VERSION "$Format:%h$"

NS_ :

BS_:

BU_: APB APP APS BCCEN BDY DAS DBG EAS EPAS EPAS2 EPAS3S EPB EPBM ESP GTW GTWU IBST IC MCU OCS PARK PARK3 RADAR RCM RT3000 SCCM SDM SEC TAS TAS2 TAS2DBG TOOL TPMS VCSEATD VCSEATP

BO_ 1463 EPBM_alertLog: 8 EPBM
 SG_ EPBM_alertID M : 0|15@1+ (1,0) [0|0] "" GTW
 SG_ EPBM_alertType : 15|1@1+ (1,0) [0|0] "" GTW
 SG_ EPBM_a001_leftEncIntrpt m1 : 16|16@1+ (1,0) [0|0] "" GTW
 SG_ EPBM_a002_leftIdleOc m2 : 16|16@1+ (0.01115686274,0) [0|0] "" GTW
 SG_ EPBM_a003_leftEncIrrational m3 : 16|16@1+ (1,0) [0|0] "" GTW
 SG_ EPBM_a005_leftOc m5 : 16|16@1+ (0.017346834,-37.87878788) [0|0] "A" GTW
 SG_ EPBM_a006_leftUc m6 : 16|16@1+ (0.017346834,-37.87878788) [0|0] "A" GTW
 SG_ EPBM_a007_leftEndStop m7 : 16|16@1+ (0.017346834,-37.87878788) [0|0] "A" GTW
 SG_ EPBM_a008_voltageCounts m8 : 16|16@1+ (1,0) [0|0] "" GTW
 SG_ EPBM_a008_encPosition m8 : 32|16@1+ (1,0) [0|0] "" GTW
 SG_ EPBM_a009_voltageN m9 : 16|16@1+ (0.004833984375,0) [0|0] "V" GTW
 SG_ EPBM_a009_voltageP m9 : 32|16@1+ (0.004833984375,0) [0|0] "V" GTW
 SG_ EPBM_a010_voltageN m10 : 16|16@1+ (0.004833984375,0) [0|0] "V" GTW
 SG_ EPBM_a010_voltageP m10 : 32|16@1+ (0.004833984375,0) [0|0] "V" GTW
 SG_ EPBM_a011_voltageN m11 : 16|16@1+ (0.004833984375,0) [0|0] "V" GTW
 SG_ EPBM_a011_voltageP m11 : 32|16@1+ (0.004833984375,0) [0|0] "V" GTW
 SG_ EPBM_a012_voltageN m12 : 16|16@1+ (0.004833984375,0) [0|0] "V" GTW
 SG_ EPBM_a012_voltageP m12 : 32|16@1+ (0.004833984375,0) [0|0] "V" GTW
 SG_ EPBM_a013_reqState m13 : 16|16@1+ (1,0) [0|0] "" GTW
 SG_ EPBM_a013_substate m13 : 32|16@1+ (1,0) [0|0] "" GTW
 SG_ EPBM_a014_reqState m14 : 16|16@1+ (1,0) [0|0] "" GTW
 SG_ EPBM_a014_substate m14 : 32|16@1+ (1,0) [0|0] "" GTW
 SG_ EPBM_a015_state m15 : 16|16@1+ (1,0) [0|0] "" GTW
 SG_ EPBM_a015_reqState m15 : 32|16@1+ (1,0) [0|0] "" GTW
 SG_ EPBM_a015_EPB_substate m15 : 48|8@1+ (1,0) [0|0] "" GTW
 SG_ EPBM_a016_leftPHalfBridge m16 : 16|16@1+ (1,0) [0|0] "" GTW
 SG_ EPBM_a017_leftNHalfBridge m17 : 16|16@1+ (1,0) [0|0] "" GTW
 SG_ EPBM_a018_voltageN m18 : 16|16@1+ (0.004833984375,0) [0|0] "V" GTW
 SG_ EPBM_a018_voltageP m18 : 32|16@1+ (0.004833984375,0) [0|0] "V" GTW
 SG_ EPBM_a019_voltageN m19 : 16|16@1+ (0.004833984375,0) [0|0] "V" GTW
 SG_ EPBM_a019_voltageP m19 : 32|16@1+ (0.004833984375,0) [0|0] "V" GTW
 SG_ EPBM_a020_voltageN m20 : 16|16@1+ (0.004833984375,0) [0|0] "V" GTW
 SG_ EPBM_a020_voltageP m20 : 32|16@1+ (0.004833984375,0) [0|0] "V" GTW
 SG_ EPBM_a021_voltageN m21 : 16|16@1+ (0.004833984375,0) [0|0] "V" GTW
 SG_ EPBM_a021_voltageP m21 : 32|16@1+ (0.004833984375,0) [0|0] "V" GTW
 SG_ EPBM_a022_substateEPB m22 : 16|16@1+ (1,0) [0|0] "" GTW
 SG_ EPBM_a022_substateEPBM m22 : 32|16@1+ (1,0) [0|0] "" GTW
 SG_ EPBM_a023_targetCurrent m23 : 16|16@1+ (0.017346834,-37.87878788) [0|0] "A" GTW
 SG_ EPBM_a023_measuredCurrent m23 : 32|16@1+ (0.017346834,-37.87878788) [0|0] "A" GTW
 SG_ EPBM_a023_peakCurrent m23 : 48|16@1+ (0.017346834,-37.87878788) [0|0] "A" GTW
 SG_ EPBM_a024_encPosition m24 : 16|16@1+ (1,0) [0|0] "" GTW
 SG_ EPBM_a024_current m24 : 32|16@1+ (0.017346834,-37.87878788) [0|0] "A" GTW
 SG_ EPBM_a025_encPosition m25 : 16|16@1+ (1,0) [0|0] "" GTW
 SG_ EPBM_a025_voltageCounts m25 : 32|16@1+ (1,0) [0|0] "" GTW
 SG_ EPBM_a026_leftUnderRelease m26 : 16|16@1+ (1,0) [0|0] "" GTW
 SG_ EPBM_a027_encoderElapsed m27 : 16|16@1+ (1,0) [0|0] "" GTW
 SG_ EPBM_a028_uncalibratedCurrent m28 : 16|12@1+ (0.017346834,-37.87878788) [0|0] "A" GTW
 SG_ EPBM_a028_calibratedCurrent m28 : 28|12@1+ (0.017346834,-37.87878788) [0|0] "A" GTW
 SG_ EPBM_a029_canDisabled m29 : 16|16@1+ (1,0) [0|0] "" GTW
 SG_ EPBM_a030_spiCksum m30 : 16|16@1+ (1,0) [0|0] "" GTW
 SG_ EPBM_a030_calcCksum m30 : 32|16@1+ (1,0) [0|0] "" GTW
 SG_ EPBM_a031_stateEPB m31 : 16|16@1+ (1,0) [0|0] "" GTW
 SG_ EPBM_a031_stateEPBM m31 : 32|16@1+ (1,0) [0|0] "" GTW
 SG_ EPBM_a032_reqStateEPB m32 : 16|16@1+ (1,0) [0|0] "" GTW
 SG_ EPBM_a032_reqStateEPBM m32 : 32|16@1+ (1,0) [0|0] "" GTW
 SG_ EPBM_a033_canID m33 : 16|12@1+ (1,0) [0|0] "" GTW
 SG_ EPBM_a033_mbox m33 : 28|4@1+ (1,0) [0|0] "" GTW
 SG_ EPBM_a034_canID m34 : 16|12@1+ (1,0) [0|0] "" GTW
 SG_ EPBM_a034_errorType m34 : 28|4@1+ (1,0) [0|0] "" GTW
 SG_ EPBM_a034_badValue1 m34 : 32|16@1+ (1,0) [0|0] "" GTW
 SG_ EPBM_a034_badValue2 m34 : 48|16@1+ (1,0) [0|0] "" GTW
 SG_ EPBM_canAddress m35 : 16|12@1+ (1,0) [0|0] "" GTW
 SG_ EPBM_canErrorType m35 : 28|4@1+ (1,0) [0|0] "" GTW
 SG_ EPBM_canErrorWord1 m35 : 32|16@1+ (1,0) [0|0] "" GTW
 SG_ EPBM_canErrorWord2 m35 : 48|16@1+ (1,0) [0|0] "" GTW
 SG_ EPBM_a036_canOverrun m36 : 16|16@1+ (1,0) [0|0] "" GTW
 SG_ EPBM_a037_firmware m37 : 16|16@1+ (1,0) [0|0] "" GTW
 SG_ EPBM_eepromErrorType m38 : 16|16@1+ (1,0) [0|0] "" GTW
 SG_ EPBM_a039_watchdogReset m39 : 16|16@1+ (1,0) [0|0] "" GTW
 SG_ EPBM_a040_memoryError m40 : 16|16@1+ (1,0) [0|0] "" GTW
 SG_ EPBM_a041_spiOpen m41 : 16|16@1+ (1,0) [0|0] "" GTW
 SG_ EPBM_a042_spiRead m42 : 16|16@1+ (1,0) [0|0] "" GTW
 SG_ EPBM_a043_ABS_A m43 : 16|16@1+ (1,0) [0|0] "" GTW
 SG_ EPBM_a043_ABS_E m43 : 32|16@1+ (1,0) [0|0] "" GTW
 SG_ EPBM_a043_ABS_B m43 : 48|16@1+ (1,0) [0|0] "" GTW
 SG_ EPBM_a044_DI_Torque1 m44 : 16|1@1+ (1,0) [0|0] "" GTW
 SG_ EPBM_a044_DI_Torque2 m44 : 17|1@1+ (1,0) [0|0] "" GTW
 SG_ EPBM_a044_DI_state m44 : 18|1@1+ (1,0) [0|0] "" GTW
 SG_ EPBM_a044_DI_state2 m44 : 19|1@1+ (1,0) [0|0] "" GTW
 SG_ EPBM_a045_GTW_status m45 : 16|1@1+ (1,0) [0|0] "" GTW
 SG_ EPBM_a045_GTW_chControl m45 : 17|1@1+ (1,0) [0|0] "" GTW
 SG_ EPBM_a045_GTW_carConfig m45 : 18|1@1+ (1,0) [0|0] "" GTW
 SG_ EPBM_a045_GTW_odo m45 : 19|1@1+ (1,0) [0|0] "" GTW
 SG_ EPBM_a046_SBW_RQ_SCCM m46 : 16|16@1+ (1,0) [0|0] "" GTW
 SG_ EPBM_a047_EPB_status m47 : 16|16@1+ (1,0) [0|0] "" GTW
 SG_ EPBM_a048_CHG_status m48 : 16|16@1+ (1,0) [0|0] "" GTW
 SG_ EPBM_a049_ESP_125h m49 : 16|1@1+ (1,0) [0|0] "" GTW
 SG_ EPBM_a049_ESP_A m49 : 17|1@1+ (1,0) [0|0] "" GTW
 SG_ EPBM_a049_ESP_B m49 : 18|1@1+ (1,0) [0|0] "" GTW
 SG_ EPBM_a049_ESP_E m49 : 19|1@1+ (1,0) [0|0] "" GTW
 SG_ EPBM_a049_ESP_C m49 : 20|1@1+ (1,0) [0|0] "" GTW
 SG_ EPBM_a049_ESP_wheelSpeeds m49 : 21|1@1+ (1,0) [0|0] "" GTW
 SG_ EPBM_a049_ESP_145h m49 : 22|1@1+ (1,0) [0|0] "" GTW
 SG_ EPBM_a049_ESP_115h m49 : 23|1@1+ (1,0) [0|0] "" GTW
 SG_ EPBM_a050_MCU_chControl m50 : 16|16@1+ (1,0) [0|0] "" GTW
 SG_ EPBM_a050_MCU_chControl2 m50 : 32|1@1+ (1,0) [0|0] "" GTW
 SG_ EPBM_a051_voltageN m51 : 16|16@1+ (0.004833984375,0) [0|0] "V" GTW
 SG_ EPBM_a051_voltageP m51 : 32|16@1+ (0.004833984375,0) [0|0] "V" GTW
 SG_ EPBM_a052_voltageN m52 : 16|16@1+ (0.004833984375,0) [0|0] "V" GTW
 SG_ EPBM_a052_voltageP m52 : 32|16@1+ (0.004833984375,0) [0|0] "V" GTW
 SG_ EPBM_a055_taskID m55 : 16|16@1+ (1,0) [0|0] "" GTW
 SG_ EPBM_a055_stackUsed m55 : 32|16@1+ (1,0) [0|0] "" GTW
 SG_ EPBM_a055_stackSize m55 : 48|16@1+ (1,0) [0|0] "" GTW
 SG_ EPBM_a056_twelveV m56 : 16|16@1+ (0.004833984375,0) [0|0] "V" GTW
 SG_ EPBM_a057_twelveV m57 : 16|16@1+ (0.004833984375,0) [0|0] "V" GTW
 SG_ EPBM_a058_5vLost m58 : 16|16@1+ (1,0) [0|0] "" GTW
 SG_ EPBM_a059_batt1 m59 : 16|16@1+ (0.004833984375,0) [0|0] "V" GTW
 SG_ EPBM_a059_batt2 m59 : 32|16@1+ (0.004833984375,0) [0|0] "V" GTW
 SG_ EPBM_a060_maxCycles1 m60 : 16|16@1+ (1,0) [0|0] "" GTW
 SG_ EPBM_a061_maxCycles2 m61 : 16|16@1+ (1,0) [0|0] "" GTW
 SG_ EPBM_a062_diGear m62 : 16|16@1+ (1,0) [0|0] "" GTW
 SG_ EPBM_a062_state m62 : 32|16@1+ (1,0) [0|0] "" GTW
 SG_ EPBM_a063_frontWhlSpeed m63 : 16|16@1+ (1,0) [0|0] "MPH" GTW
 SG_ EPBM_a063_rearWhlSpeed m63 : 32|16@1+ (1,0) [0|0] "MPH" GTW
 SG_ EPBM_a063_motorMPH m63 : 48|16@1+ (1,0) [0|0] "MPH" GTW
 SG_ EPBM_a065_rightEncIntrpt m65 : 16|16@1+ (1,0) [0|0] "" GTW
 SG_ EPBM_a066_rightIdleOc m66 : 16|16@1+ (0.01115686274,0) [0|0] "" GTW
 SG_ EPBM_a067_rightEncIrrational m67 : 16|16@1+ (1,0) [0|0] "" GTW
 SG_ EPBM_a069_rightOc m69 : 16|16@1+ (0.017346834,-37.87878788) [0|0] "A" GTW
 SG_ EPBM_a070_rightUc m70 : 16|16@1+ (0.017346834,-37.87878788) [0|0] "A" GTW
 SG_ EPBM_a071_rightEndStop m71 : 16|16@1+ (0.017346834,-37.87878788) [0|0] "A" GTW
 SG_ EPBM_a072_voltageCounts m72 : 16|16@1+ (1,0) [0|0] "" GTW
 SG_ EPBM_a072_encPosition m72 : 32|16@1+ (1,0) [0|0] "" GTW
 SG_ EPBM_a073_voltageN m73 : 16|16@1+ (0.004833984375,0) [0|0] "V" GTW
 SG_ EPBM_a073_voltageP m73 : 32|16@1+ (0.004833984375,0) [0|0] "V" GTW
 SG_ EPBM_a074_voltageN m74 : 16|16@1+ (0.004833984375,0) [0|0] "V" GTW
 SG_ EPBM_a074_voltageP m74 : 32|16@1+ (0.004833984375,0) [0|0] "V" GTW
 SG_ EPBM_a075_voltageN m75 : 16|16@1+ (0.004833984375,0) [0|0] "V" GTW
 SG_ EPBM_a075_voltageP m75 : 32|16@1+ (0.004833984375,0) [0|0] "V" GTW
 SG_ EPBM_a076_voltageN m76 : 16|16@1+ (0.004833984375,0) [0|0] "V" GTW
 SG_ EPBM_a076_voltageP m76 : 32|16@1+ (0.004833984375,0) [0|0] "V" GTW
 SG_ EPBM_a077_reqState m77 : 16|16@1+ (1,0) [0|0] "" GTW
 SG_ EPBM_a077_substate m77 : 32|16@1+ (1,0) [0|0] "" GTW
 SG_ EPBM_a078_reqState m78 : 16|16@1+ (1,0) [0|0] "" GTW
 SG_ EPBM_a078_substate m78 : 32|16@1+ (1,0) [0|0] "" GTW
 SG_ EPBM_a079_state m79 : 16|16@1+ (1,0) [0|0] "" GTW
 SG_ EPBM_a079_reqState m79 : 32|16@1+ (1,0) [0|0] "" GTW
 SG_ EPBM_a079_EPB_substate m79 : 48|8@1+ (1,0) [0|0] "" GTW
 SG_ EPBM_a080_rightPHalfBridge m80 : 16|16@1+ (1,0) [0|0] "" GTW
 SG_ EPBM_a081_rightNHalfBridge m81 : 16|16@1+ (1,0) [0|0] "" GTW
 SG_ EPBM_a082_voltageN m82 : 16|16@1+ (0.004833984375,0) [0|0] "V" GTW
 SG_ EPBM_a082_voltageP m82 : 32|16@1+ (0.004833984375,0) [0|0] "V" GTW
 SG_ EPBM_a083_voltageN m83 : 16|16@1+ (0.004833984375,0) [0|0] "V" GTW
 SG_ EPBM_a083_voltageP m83 : 32|16@1+ (0.004833984375,0) [0|0] "V" GTW
 SG_ EPBM_a084_voltageN m84 : 16|16@1+ (0.004833984375,0) [0|0] "V" GTW
 SG_ EPBM_a084_voltageP m84 : 32|16@1+ (0.004833984375,0) [0|0] "V" GTW
 SG_ EPBM_a085_voltageN m85 : 16|16@1+ (0.004833984375,0) [0|0] "V" GTW
 SG_ EPBM_a085_voltageP m85 : 32|16@1+ (0.004833984375,0) [0|0] "V" GTW
 SG_ EPBM_a086_substateEPB m86 : 16|16@1+ (1,0) [0|0] "" GTW
 SG_ EPBM_a086_substateEPBM m86 : 32|16@1+ (1,0) [0|0] "" GTW
 SG_ EPBM_a087_targetCurrent m87 : 16|16@1+ (0.017346834,-37.87878788) [0|0] "A" GTW
 SG_ EPBM_a087_measuredCurrent m87 : 32|16@1+ (0.017346834,-37.87878788) [0|0] "A" GTW
 SG_ EPBM_a087_peakCurrent m87 : 48|16@1+ (0.017346834,-37.87878788) [0|0] "A" GTW
 SG_ EPBM_a088_encPosition m88 : 16|16@1+ (1,0) [0|0] "" GTW
 SG_ EPBM_a088_current m88 : 32|16@1+ (0.017346834,-37.87878788) [0|0] "A" GTW
 SG_ EPBM_a089_encPosition m89 : 16|16@1+ (1,0) [0|0] "" GTW
 SG_ EPBM_a089_voltageCounts m89 : 32|16@1+ (1,0) [0|0] "" GTW
 SG_ EPBM_a090_rightUnderRelease m90 : 16|16@1+ (1,0) [0|0] "" GTW
 SG_ EPBM_a091_encoderElapsed m91 : 16|16@1+ (1,0) [0|0] "" GTW
 SG_ EPBM_a092_uncalibratedCurrent m92 : 16|12@1+ (0.017346834,-37.87878788) [0|0] "A" GTW
 SG_ EPBM_a092_calibratedCurrent m92 : 28|12@1+ (0.017346834,-37.87878788) [0|0] "A" GTW
 SG_ EPBM_a093_DAS_control m93 : 16|1@1+ (1,0) [0|0] "" GTW
 SG_ EPBM_a095_expectedConfig m95 : 16|3@1+ (1,0) [0|0] "" GTW
 SG_ EPBM_a095_actualConfig m95 : 19|3@1+ (1,0) [0|0] "" GTW
 SG_ EPBM_a095_alertLatch m95 : 22|10@1+ (1,0) [0|0] "" GTW
 SG_ EPBM_a095_chassisType m95 : 48|1@1+ (1,0) [0|0] "" GTW
 SG_ EPBM_a095_timeout m95 : 49|1@1+ (1,0) [0|0] "" GTW
 SG_ EPBM_a095_brakeHwType_CAN m95 : 50|2@1+ (1,0) [0|0] "" GTW
 SG_ EPBM_a095_brakeHwType_EPB m95 : 54|2@1+ (1,0) [0|0] "" GTW
 SG_ EPBM_a095_chassisType_CAN m95 : 56|2@1+ (1,0) [0|0] "" GTW
 SG_ EPBM_a095_chassisType_EPB m95 : 58|2@1+ (1,0) [0|0] "" GTW
 SG_ EPBM_a096_selfParkAbortReason m96 : 16|16@1+ (1,0) [0|0] "" GTW
 SG_ EPBM_a097_parkOocStatus m97 : 16|1@1+ (1,0) [0|0] "" GTW
 SG_ EPBM_a098_pmState2 m98 : 16|1@1+ (1,0) [0|0] "" GTW
 SG_ EPBM_a100_uncalibratedCurrentL m100 : 16|12@1+ (0.017346834,-37.87878788) [0|0] "A" GTW
 SG_ EPBM_a100_uncalibratedCurrentR m100 : 28|12@1+ (0.017346834,-37.87878788) [0|0] "A" GTW
 SG_ EPBM_a101_uncalibratedCurrentL m101 : 16|12@1+ (0.017346834,-37.87878788) [0|0] "A" GTW
 SG_ EPBM_a101_uncalibratedCurrentR m101 : 28|12@1+ (0.017346834,-37.87878788) [0|0] "A" GTW
 SG_ EPBM_a102_measuredCurrent m102 : 16|12@1+ (0.017346834,-37.87878788) [0|0] "A" GTW
 SG_ EPBM_a102_targetCurrent m102 : 28|12@1+ (0.017346834,-37.87878788) [0|0] "A" GTW
 SG_ EPBM_a102_peakCurrent m102 : 40|12@1+ (0.017346834,-37.87878788) [0|0] "A" GTW
 SG_ EPBM_a103_measuredCurrent m103 : 16|12@1+ (0.017346834,-37.87878788) [0|0] "A" GTW
 SG_ EPBM_a103_targetCurrent m103 : 28|12@1+ (0.017346834,-37.87878788) [0|0] "A" GTW
 SG_ EPBM_a103_peakCurrent m103 : 40|12@1+ (0.017346834,-37.87878788) [0|0] "A" GTW
 SG_ EPBM_a106_voltage1 m106 : 16|16@1+ (0.004833984375,0) [0|0] "V" GTW
 SG_ EPBM_a106_voltage2 m106 : 32|16@1+ (0.004833984375,0) [0|0] "V" GTW
 SG_ EPBM_a106_alertID m106 : 48|15@1+ (1,0) [0|0] "" GTW
 SG_ EPBM_a106_motorSel m106 : 63|1@1+ (1,0) [0|0] "" GTW
 SG_ EPBM_a107_current1 m107 : 16|16@1+ (0.017346834,-37.87878788) [0|0] "A" GTW
 SG_ EPBM_a107_current2 m107 : 32|16@1+ (0.017346834,-37.87878788) [0|0] "A" GTW
 SG_ EPBM_a107_alertID m107 : 48|15@1+ (1,0) [0|0] "" GTW
 SG_ EPBM_a107_motorSel m107 : 63|1@1+ (1,0) [0|0] "" GTW
 SG_ EPBM_a110_offsetApplied m110 : 16|2@1+ (1,0) [0|0] "" GTW
 SG_ EPBM_a110_uncalibratedCurrent m110 : 18|12@1+ (0.017346834,-37.87878788) [0|0] "A" GTW
 SG_ EPBM_a110_appliedOffsetValue m110 : 30|12@1+ (0.017346834,-37.87878788) [0|0] "A" GTW
 SG_ EPBM_a111_offsetApplied m111 : 16|2@1+ (1,0) [0|0] "" GTW
 SG_ EPBM_a111_uncalibratedCurrent m111 : 18|12@1+ (0.017346834,-37.87878788) [0|0] "A" GTW
 SG_ EPBM_a111_appliedOffsetValue m111 : 30|12@1+ (0.017346834,-37.87878788) [0|0] "A" GTW
 SG_ EPBM_a112_offsetApplied m112 : 16|2@1+ (1,0) [0|0] "" GTW
 SG_ EPBM_a112_uncalibratedCurrent m112 : 18|12@1+ (0.017346834,-37.87878788) [0|0] "A" GTW
 SG_ EPBM_a113_offsetApplied m113 : 16|2@1+ (1,0) [0|0] "" GTW
 SG_ EPBM_a113_uncalibratedCurrent m113 : 18|12@1+ (0.017346834,-37.87878788) [0|0] "A" GTW
 SG_ EPBM_a114_diGear m114 : 16|4@1+ (1,0) [0|0] "" GTW
 SG_ EPBM_a114_unparkAllowed m114 : 20|1@1+ (1,0) [0|0] "" GTW
 SG_ EPBM_a114_pendingState m114 : 21|4@1+ (1,0) [0|0] "" GTW
 SG_ EPBM_a115_voltageN m115 : 16|16@1+ (0.004833984375,0) [0|0] "V" GTW
 SG_ EPBM_a115_voltageP m115 : 32|16@1+ (0.004833984375,0) [0|0] "V" GTW
 SG_ EPBM_a116_voltageN m116 : 16|16@1+ (0.004833984375,0) [0|0] "V" GTW
 SG_ EPBM_a116_voltageP m116 : 32|16@1+ (0.004833984375,0) [0|0] "V" GTW
 SG_ EPBM_a117_brakeHwType_CAN m117 : 16|2@1+ (1,0) [0|0] "" GTW
 SG_ EPBM_a117_brakeHwType_EPB m117 : 18|2@1+ (1,0) [0|0] "" GTW

BO_ 775 EPBM_alertMatrix0: 8 EPBM
 SG_ EPBM_f001_leftEncIntrpt : 0|1@1+ (1,0) [0|0] "" GTW
 SG_ EPBM_f002_leftIdleOc : 1|1@1+ (1,0) [0|0] "" GTW
 SG_ EPBM_f003_leftEncIrrational : 2|1@1+ (1,0) [0|0] "" GTW
 SG_ EPBM_f004_leftEncoderSna : 3|1@1+ (1,0) [0|0] "" GTW
 SG_ EPBM_f005_leftOc : 4|1@1+ (1,0) [0|0] "" GTW
 SG_ EPBM_f006_leftUc : 5|1@1+ (1,0) [0|0] "" GTW
 SG_ EPBM_f007_leftEndStop : 6|1@1+ (1,0) [0|0] "" GTW
 SG_ EPBM_f008_leftShortApply : 7|1@1+ (1,0) [0|0] "" GTW
 SG_ EPBM_f009_leftNShort : 8|1@1+ (1,0) [0|0] "" GTW
 SG_ EPBM_f010_leftPShort : 9|1@1+ (1,0) [0|0] "" GTW
 SG_ EPBM_f011_leftNOpen : 10|1@1+ (1,0) [0|0] "" GTW
 SG_ EPBM_f012_leftPOpen : 11|1@1+ (1,0) [0|0] "" GTW
 SG_ EPBM_f013_leftEnaStuckHigh : 12|1@1+ (1,0) [0|0] "" GTW
 SG_ EPBM_f014_leftEnaStuckLow : 13|1@1+ (1,0) [0|0] "" GTW
 SG_ EPBM_f015_leftDriveDuration : 14|1@1+ (1,0) [0|0] "" GTW
 SG_ EPBM_f016_leftPHalfBridge : 15|1@1+ (1,0) [0|0] "" GTW
 SG_ EPBM_f017_leftNHalfBridge : 16|1@1+ (1,0) [0|0] "" GTW
 SG_ EPBM_f018_leftNvOv : 17|1@1+ (1,0) [0|0] "" GTW
 SG_ EPBM_f019_leftNvUv : 18|1@1+ (1,0) [0|0] "" GTW
 SG_ EPBM_f020_leftPvOv : 19|1@1+ (1,0) [0|0] "" GTW
 SG_ EPBM_f021_leftPvUv : 20|1@1+ (1,0) [0|0] "" GTW
 SG_ EPBM_f022_leftSubstateErr : 21|1@1+ (1,0) [0|0] "" GTW
 SG_ EPBM_f023_leftOverApply : 22|1@1+ (1,0) [0|0] "" GTW
 SG_ EPBM_f024_leftUnderApply : 23|1@1+ (1,0) [0|0] "" GTW
 SG_ EPBM_f025_leftOverRelease : 24|1@1+ (1,0) [0|0] "" GTW
 SG_ EPBM_f026_leftUnderRelease : 25|1@1+ (1,0) [0|0] "" GTW
 SG_ EPBM_f027_spuriousEncIntL : 26|1@1+ (1,0) [0|0] "" GTW
 SG_ EPBM_f028_noCurrentCalL : 27|1@1+ (1,0) [0|0] "" GTW
 SG_ EPBM_f029_canDisabled : 28|1@1+ (1,0) [0|0] "" GTW
 SG_ EPBM_f030_interProcSpi : 29|1@1+ (1,0) [0|0] "" GTW
 SG_ EPBM_f031_stateErr : 30|1@1+ (1,0) [0|0] "" GTW
 SG_ EPBM_f032_reqStateErr : 31|1@1+ (1,0) [0|0] "" GTW
 SG_ EPBM_f033_canHardware : 32|1@1+ (1,0) [0|0] "" GTW
 SG_ EPBM_f034_canData : 33|1@1+ (1,0) [0|0] "" GTW
 SG_ EPBM_f035_canErr : 34|1@1+ (1,0) [0|0] "" GTW
 SG_ EPBM_f036_canOverrun : 35|1@1+ (1,0) [0|0] "" GTW
 SG_ EPBM_f037_firmware : 36|1@1+ (1,0) [0|0] "" GTW
 SG_ EPBM_f038_eeprom : 37|1@1+ (1,0) [0|0] "" GTW
 SG_ EPBM_f039_watchdogReset : 38|1@1+ (1,0) [0|0] "" GTW
 SG_ EPBM_f040_memoryError : 39|1@1+ (1,0) [0|0] "" GTW
 SG_ EPBM_f041_spiOpen : 40|1@1+ (1,0) [0|0] "" GTW
 SG_ EPBM_f042_spiRead : 41|1@1+ (1,0) [0|0] "" GTW
 SG_ EPBM_f043_absMIA : 42|1@1+ (1,0) [0|0] "" GTW
 SG_ EPBM_f044_diMIA : 43|1@1+ (1,0) [0|0] "" GTW
 SG_ EPBM_f045_gtwMIA : 44|1@1+ (1,0) [0|0] "" GTW
 SG_ EPBM_f046_sccmMIA : 45|1@1+ (1,0) [0|0] "" GTW
 SG_ EPBM_f047_epbMIA : 46|1@1+ (1,0) [0|0] "" GTW
 SG_ EPBM_f048_chgMIA : 47|1@1+ (1,0) [0|0] "" GTW
 SG_ EPBM_f049_espMIA : 48|1@1+ (1,0) [0|0] "" GTW
 SG_ EPBM_f050_mcuMIA : 49|1@1+ (1,0) [0|0] "" GTW
 SG_ EPBM_f051_leftNVoltageLow : 50|1@1+ (1,0) [0|0] "" GTW
 SG_ EPBM_f052_leftPVoltageHigh : 51|1@1+ (1,0) [0|0] "" GTW
 SG_ EPBM_f053_unused : 52|1@1+ (1,0) [0|0] "" GTW
 SG_ EPBM_f054_unused : 53|1@1+ (1,0) [0|0] "" GTW
 SG_ EPBM_f055_stackOverflow : 54|1@1+ (1,0) [0|0] "" GTW
 SG_ EPBM_f056_12vOv : 55|1@1+ (1,0) [0|0] "" GTW
 SG_ EPBM_f057_12vUv : 56|1@1+ (1,0) [0|0] "" GTW
 SG_ EPBM_f058_5vLost : 57|1@1+ (1,0) [0|0] "" GTW
 SG_ EPBM_f059_battMismatch : 58|1@1+ (1,0) [0|0] "" GTW
 SG_ EPBM_f060_maxCycles1 : 59|1@1+ (1,0) [0|0] "" GTW
 SG_ EPBM_f061_maxCycles2 : 60|1@1+ (1,0) [0|0] "" GTW
 SG_ EPBM_f062_diGearInvld : 61|1@1+ (1,0) [0|0] "" GTW
 SG_ EPBM_f063_unused : 62|1@1+ (1,0) [0|0] "" GTW
 SG_ EPBM_f064_unused : 63|1@1+ (1,0) [0|0] "" GTW

BO_ 823 EPBM_alertMatrix1: 8 EPBM
 SG_ EPBM_f065_rightEncIntrpt : 0|1@1+ (1,0) [0|0] "" GTW
 SG_ EPBM_f066_rightIdleOc : 1|1@1+ (1,0) [0|0] "" GTW
 SG_ EPBM_f067_rightEncIrrational : 2|1@1+ (1,0) [0|0] "" GTW
 SG_ EPBM_f068_rightEncoderSna : 3|1@1+ (1,0) [0|0] "" GTW
 SG_ EPBM_f069_rightOc : 4|1@1+ (1,0) [0|0] "" GTW
 SG_ EPBM_f070_rightUc : 5|1@1+ (1,0) [0|0] "" GTW
 SG_ EPBM_f071_rightEndStop : 6|1@1+ (1,0) [0|0] "" GTW
 SG_ EPBM_f072_rightShortApply : 7|1@1+ (1,0) [0|0] "" GTW
 SG_ EPBM_f073_rightNShort : 8|1@1+ (1,0) [0|0] "" GTW
 SG_ EPBM_f074_rightPShort : 9|1@1+ (1,0) [0|0] "" GTW
 SG_ EPBM_f075_rightNOpen : 10|1@1+ (1,0) [0|0] "" GTW
 SG_ EPBM_f076_rightPOpen : 11|1@1+ (1,0) [0|0] "" GTW
 SG_ EPBM_f077_rightEnaStuckHigh : 12|1@1+ (1,0) [0|0] "" GTW
 SG_ EPBM_f078_rightEnaStuckLow : 13|1@1+ (1,0) [0|0] "" GTW
 SG_ EPBM_f079_rightDriveDuration : 14|1@1+ (1,0) [0|0] "" GTW
 SG_ EPBM_f080_rightPHalfBridge : 15|1@1+ (1,0) [0|0] "" GTW
 SG_ EPBM_f081_rightNHalfBridge : 16|1@1+ (1,0) [0|0] "" GTW
 SG_ EPBM_f082_rightNvOv : 17|1@1+ (1,0) [0|0] "" GTW
 SG_ EPBM_f083_rightNvUv : 18|1@1+ (1,0) [0|0] "" GTW
 SG_ EPBM_f084_rightPvOv : 19|1@1+ (1,0) [0|0] "" GTW
 SG_ EPBM_f085_rightPvUv : 20|1@1+ (1,0) [0|0] "" GTW
 SG_ EPBM_f086_rightSubstateErr : 21|1@1+ (1,0) [0|0] "" GTW
 SG_ EPBM_f087_rightOverApply : 22|1@1+ (1,0) [0|0] "" GTW
 SG_ EPBM_f088_rightUnderApply : 23|1@1+ (1,0) [0|0] "" GTW
 SG_ EPBM_f089_rightOverRelease : 24|1@1+ (1,0) [0|0] "" GTW
 SG_ EPBM_f090_rightUnderRelease : 25|1@1+ (1,0) [0|0] "" GTW
 SG_ EPBM_f091_spuriousEncIntR : 26|1@1+ (1,0) [0|0] "" GTW
 SG_ EPBM_f092_noCurrentCalR : 27|1@1+ (1,0) [0|0] "" GTW
 SG_ EPBM_f093_dasMIA : 28|1@1+ (1,0) [0|0] "" GTW
 SG_ EPBM_f094_unused : 29|1@1+ (1,0) [0|0] "" GTW
 SG_ EPBM_f095_invalidConfig : 30|1@1+ (1,0) [0|0] "" GTW
 SG_ EPBM_f096_selfParkAborted : 31|1@1+ (1,0) [0|0] "" GTW
 SG_ EPBM_f097_parkMia : 32|1@1+ (1,0) [0|0] "" GTW
 SG_ EPBM_f098_pmMia : 33|1@1+ (1,0) [0|0] "" GTW
 SG_ EPBM_f099_unused : 34|1@1+ (1,0) [0|0] "" GTW
 SG_ EPBM_f100_calibrationWarning : 35|1@1+ (1,0) [0|0] "" GTW
 SG_ EPBM_f101_calibrationFault : 36|1@1+ (1,0) [0|0] "" GTW
 SG_ EPBM_f102_targetNotReachedL : 37|1@1+ (1,0) [0|0] "" GTW
 SG_ EPBM_f103_targetNotReachedR : 38|1@1+ (1,0) [0|0] "" GTW
 SG_ EPBM_f104_epbStillAsleep : 39|1@1+ (1,0) [0|0] "" GTW
 SG_ EPBM_f105_epbWentToSleep : 40|1@1+ (1,0) [0|0] "" GTW
 SG_ EPBM_f106_voltageWarning : 41|1@1+ (1,0) [0|0] "" GTW
 SG_ EPBM_f107_currentWarning : 42|1@1+ (1,0) [0|0] "" GTW
 SG_ EPBM_f108_unused : 43|1@1+ (1,0) [0|0] "" GTW
 SG_ EPBM_f109_unused : 44|1@1+ (1,0) [0|0] "" GTW
 SG_ EPBM_f110_calWarningLeft : 45|1@1+ (1,0) [0|0] "" GTW
 SG_ EPBM_f111_calWarningRight : 46|1@1+ (1,0) [0|0] "" GTW
 SG_ EPBM_f112_calFaultLeft : 47|1@1+ (1,0) [0|0] "" GTW
 SG_ EPBM_f113_calFaultRight : 48|1@1+ (1,0) [0|0] "" GTW
 SG_ EPBM_f114_unparkNotAllowed : 49|1@1+ (1,0) [0|0] "" GTW
 SG_ EPBM_f115_rightNVoltageLow : 50|1@1+ (1,0) [0|0] "" GTW
 SG_ EPBM_f116_rightPVoltageHigh : 51|1@1+ (1,0) [0|0] "" GTW
 SG_ EPBM_f117_usedFallbackValues : 52|1@1+ (1,0) [0|0] "" GTW
 SG_ EPBM_f118_unused : 53|1@1+ (1,0) [0|0] "" GTW
 SG_ EPBM_f119_unused : 54|1@1+ (1,0) [0|0] "" GTW
 SG_ EPBM_f120_unused : 55|1@1+ (1,0) [0|0] "" GTW
 SG_ EPBM_f121_unused : 56|1@1+ (1,0) [0|0] "" GTW
 SG_ EPBM_f122_unused : 57|1@1+ (1,0) [0|0] "" GTW
 SG_ EPBM_f123_unused : 58|1@1+ (1,0) [0|0] "" GTW
 SG_ EPBM_f124_unused : 59|1@1+ (1,0) [0|0] "" GTW
 SG_ EPBM_f125_unused : 60|1@1+ (1,0) [0|0] "" GTW
 SG_ EPBM_f126_unused : 61|1@1+ (1,0) [0|0] "" GTW
 SG_ EPBM_f127_unused : 62|1@1+ (1,0) [0|0] "" GTW
 SG_ EPBM_f128_unused : 63|1@1+ (1,0) [0|0] "" GTW

BO_ 791 EPBM_alertMatrix2: 8 EPBM
 SG_ EPBM_w001_leftEncIntrpt : 0|1@1+ (1,0) [0|0] "" GTW
 SG_ EPBM_w002_leftIdleOc : 1|1@1+ (1,0) [0|0] "" GTW
 SG_ EPBM_w003_leftEncIrrational : 2|1@1+ (1,0) [0|0] "" GTW
 SG_ EPBM_w004_leftEncoderSna : 3|1@1+ (1,0) [0|0] "" GTW
 SG_ EPBM_w005_leftOc : 4|1@1+ (1,0) [0|0] "" GTW
 SG_ EPBM_w006_leftUc : 5|1@1+ (1,0) [0|0] "" GTW
 SG_ EPBM_w007_leftEndStop : 6|1@1+ (1,0) [0|0] "" GTW
 SG_ EPBM_w008_leftShortApply : 7|1@1+ (1,0) [0|0] "" GTW
 SG_ EPBM_w009_leftNShort : 8|1@1+ (1,0) [0|0] "" GTW
 SG_ EPBM_w010_leftPShort : 9|1@1+ (1,0) [0|0] "" GTW
 SG_ EPBM_w011_leftNOpen : 10|1@1+ (1,0) [0|0] "" GTW
 SG_ EPBM_w012_leftPOpen : 11|1@1+ (1,0) [0|0] "" GTW
 SG_ EPBM_w013_leftEnaStuckHigh : 12|1@1+ (1,0) [0|0] "" GTW
 SG_ EPBM_w014_leftEnaStuckLow : 13|1@1+ (1,0) [0|0] "" GTW
 SG_ EPBM_w015_leftDriveDuration : 14|1@1+ (1,0) [0|0] "" GTW
 SG_ EPBM_w016_leftPHalfBridge : 15|1@1+ (1,0) [0|0] "" GTW
 SG_ EPBM_w017_leftNHalfBridge : 16|1@1+ (1,0) [0|0] "" GTW
 SG_ EPBM_w018_leftNvOv : 17|1@1+ (1,0) [0|0] "" GTW
 SG_ EPBM_w019_leftNvUv : 18|1@1+ (1,0) [0|0] "" GTW
 SG_ EPBM_w020_leftPvOv : 19|1@1+ (1,0) [0|0] "" GTW
 SG_ EPBM_w021_leftPvUv : 20|1@1+ (1,0) [0|0] "" GTW
 SG_ EPBM_w022_leftSubstateErr : 21|1@1+ (1,0) [0|0] "" GTW
 SG_ EPBM_w023_leftOverApply : 22|1@1+ (1,0) [0|0] "" GTW
 SG_ EPBM_w024_leftUnderApply : 23|1@1+ (1,0) [0|0] "" GTW
 SG_ EPBM_w025_leftOverRelease : 24|1@1+ (1,0) [0|0] "" GTW
 SG_ EPBM_w026_leftUnderRelease : 25|1@1+ (1,0) [0|0] "" GTW
 SG_ EPBM_w027_spuriousEncIntL : 26|1@1+ (1,0) [0|0] "" GTW
 SG_ EPBM_w028_noCurrentCalL : 27|1@1+ (1,0) [0|0] "" GTW
 SG_ EPBM_w029_canDisabled : 28|1@1+ (1,0) [0|0] "" GTW
 SG_ EPBM_w030_interProcSpi : 29|1@1+ (1,0) [0|0] "" GTW
 SG_ EPBM_w031_stateErr : 30|1@1+ (1,0) [0|0] "" GTW
 SG_ EPBM_w032_reqStateErr : 31|1@1+ (1,0) [0|0] "" GTW
 SG_ EPBM_w033_canHardware : 32|1@1+ (1,0) [0|0] "" GTW
 SG_ EPBM_w034_canData : 33|1@1+ (1,0) [0|0] "" GTW
 SG_ EPBM_w035_canErr : 34|1@1+ (1,0) [0|0] "" GTW
 SG_ EPBM_w036_canOverrun : 35|1@1+ (1,0) [0|0] "" GTW
 SG_ EPBM_w037_firmware : 36|1@1+ (1,0) [0|0] "" GTW
 SG_ EPBM_w038_eeprom : 37|1@1+ (1,0) [0|0] "" GTW
 SG_ EPBM_w039_watchdogReset : 38|1@1+ (1,0) [0|0] "" GTW
 SG_ EPBM_w040_memoryError : 39|1@1+ (1,0) [0|0] "" GTW
 SG_ EPBM_w041_spiOpen : 40|1@1+ (1,0) [0|0] "" GTW
 SG_ EPBM_w042_spiRead : 41|1@1+ (1,0) [0|0] "" GTW
 SG_ EPBM_w043_absMIA : 42|1@1+ (1,0) [0|0] "" GTW
 SG_ EPBM_w044_diMIA : 43|1@1+ (1,0) [0|0] "" GTW
 SG_ EPBM_w045_gtwMIA : 44|1@1+ (1,0) [0|0] "" GTW
 SG_ EPBM_w046_sccmMIA : 45|1@1+ (1,0) [0|0] "" GTW
 SG_ EPBM_w047_epbMIA : 46|1@1+ (1,0) [0|0] "" GTW
 SG_ EPBM_w048_chgMIA : 47|1@1+ (1,0) [0|0] "" GTW
 SG_ EPBM_w049_espMIA : 48|1@1+ (1,0) [0|0] "" GTW
 SG_ EPBM_w050_mcuMIA : 49|1@1+ (1,0) [0|0] "" GTW
 SG_ EPBM_w051_leftNVoltageLow : 50|1@1+ (1,0) [0|0] "" GTW
 SG_ EPBM_w052_leftPVoltageHigh : 51|1@1+ (1,0) [0|0] "" GTW
 SG_ EPBM_w053_unused : 52|1@1+ (1,0) [0|0] "" GTW
 SG_ EPBM_w054_unused : 53|1@1+ (1,0) [0|0] "" GTW
 SG_ EPBM_w055_stackOverflow : 54|1@1+ (1,0) [0|0] "" GTW
 SG_ EPBM_w056_12vOv : 55|1@1+ (1,0) [0|0] "" GTW
 SG_ EPBM_w057_12vUv : 56|1@1+ (1,0) [0|0] "" GTW
 SG_ EPBM_w058_5vLost : 57|1@1+ (1,0) [0|0] "" GTW
 SG_ EPBM_w059_battMismatch : 58|1@1+ (1,0) [0|0] "" GTW
 SG_ EPBM_w060_maxCycles1 : 59|1@1+ (1,0) [0|0] "" GTW
 SG_ EPBM_w061_maxCycles2 : 60|1@1+ (1,0) [0|0] "" GTW
 SG_ EPBM_w062_diGearInvld : 61|1@1+ (1,0) [0|0] "" GTW
 SG_ EPBM_w063_unused : 62|1@1+ (1,0) [0|0] "" GTW
 SG_ EPBM_w064_unused : 63|1@1+ (1,0) [0|0] "" GTW

BO_ 807 EPBM_alertMatrix3: 8 EPBM
 SG_ EPBM_w065_rightEncIntrpt : 0|1@1+ (1,0) [0|0] "" GTW
 SG_ EPBM_w066_rightIdleOc : 1|1@1+ (1,0) [0|0] "" GTW
 SG_ EPBM_w067_rightEncIrrational : 2|1@1+ (1,0) [0|0] "" GTW
 SG_ EPBM_w068_rightEncoderSna : 3|1@1+ (1,0) [0|0] "" GTW
 SG_ EPBM_w069_rightOc : 4|1@1+ (1,0) [0|0] "" GTW
 SG_ EPBM_w070_rightUc : 5|1@1+ (1,0) [0|0] "" GTW
 SG_ EPBM_w071_rightEndStop : 6|1@1+ (1,0) [0|0] "" GTW
 SG_ EPBM_w072_rightShortApply : 7|1@1+ (1,0) [0|0] "" GTW
 SG_ EPBM_w073_rightNShort : 8|1@1+ (1,0) [0|0] "" GTW
 SG_ EPBM_w074_rightPShort : 9|1@1+ (1,0) [0|0] "" GTW
 SG_ EPBM_w075_rightNOpen : 10|1@1+ (1,0) [0|0] "" GTW
 SG_ EPBM_w076_rightPOpen : 11|1@1+ (1,0) [0|0] "" GTW
 SG_ EPBM_w077_rightEnaStuckHigh : 12|1@1+ (1,0) [0|0] "" GTW
 SG_ EPBM_w078_rightEnaStuckLow : 13|1@1+ (1,0) [0|0] "" GTW
 SG_ EPBM_w079_rightDriveDuration : 14|1@1+ (1,0) [0|0] "" GTW
 SG_ EPBM_w080_rightPHalfBridge : 15|1@1+ (1,0) [0|0] "" GTW
 SG_ EPBM_w081_rightNHalfBridge : 16|1@1+ (1,0) [0|0] "" GTW
 SG_ EPBM_w082_rightNvOv : 17|1@1+ (1,0) [0|0] "" GTW
 SG_ EPBM_w083_rightNvUv : 18|1@1+ (1,0) [0|0] "" GTW
 SG_ EPBM_w084_rightPvOv : 19|1@1+ (1,0) [0|0] "" GTW
 SG_ EPBM_w085_rightPvUv : 20|1@1+ (1,0) [0|0] "" GTW
 SG_ EPBM_w086_rightSubstateErr : 21|1@1+ (1,0) [0|0] "" GTW
 SG_ EPBM_w087_rightOverApply : 22|1@1+ (1,0) [0|0] "" GTW
 SG_ EPBM_w088_rightUnderApply : 23|1@1+ (1,0) [0|0] "" GTW
 SG_ EPBM_w089_rightOverRelease : 24|1@1+ (1,0) [0|0] "" GTW
 SG_ EPBM_w090_rightUnderRelease : 25|1@1+ (1,0) [0|0] "" GTW
 SG_ EPBM_w091_spuriousEncIntR : 26|1@1+ (1,0) [0|0] "" GTW
 SG_ EPBM_w092_noCurrentCalR : 27|1@1+ (1,0) [0|0] "" GTW
 SG_ EPBM_w093_dasMIA : 28|1@1+ (1,0) [0|0] "" GTW
 SG_ EPBM_w094_unused : 29|1@1+ (1,0) [0|0] "" GTW
 SG_ EPBM_w095_invalidConfig : 30|1@1+ (1,0) [0|0] "" GTW
 SG_ EPBM_w096_selfParkAborted : 31|1@1+ (1,0) [0|0] "" GTW
 SG_ EPBM_w097_parkMia : 32|1@1+ (1,0) [0|0] "" GTW
 SG_ EPBM_w098_pmMia : 33|1@1+ (1,0) [0|0] "" GTW
 SG_ EPBM_w099_unused : 34|1@1+ (1,0) [0|0] "" GTW
 SG_ EPBM_w100_calibrationWarning : 35|1@1+ (1,0) [0|0] "" GTW
 SG_ EPBM_w101_calibrationFault : 36|1@1+ (1,0) [0|0] "" GTW
 SG_ EPBM_w102_targetNotReachedL : 37|1@1+ (1,0) [0|0] "" GTW
 SG_ EPBM_w103_targetNotReachedR : 38|1@1+ (1,0) [0|0] "" GTW
 SG_ EPBM_w104_epbStillAsleep : 39|1@1+ (1,0) [0|0] "" GTW
 SG_ EPBM_w105_epbWentToSleep : 40|1@1+ (1,0) [0|0] "" GTW
 SG_ EPBM_w106_voltageWarning : 41|1@1+ (1,0) [0|0] "" GTW
 SG_ EPBM_w107_currentWarning : 42|1@1+ (1,0) [0|0] "" GTW
 SG_ EPBM_w108_unused : 43|1@1+ (1,0) [0|0] "" GTW
 SG_ EPBM_w109_unused : 44|1@1+ (1,0) [0|0] "" GTW
 SG_ EPBM_w110_calWarningLeft : 45|1@1+ (1,0) [0|0] "" GTW
 SG_ EPBM_w111_calWarningRight : 46|1@1+ (1,0) [0|0] "" GTW
 SG_ EPBM_w112_calFaultLeft : 47|1@1+ (1,0) [0|0] "" GTW
 SG_ EPBM_w113_calFaultRight : 48|1@1+ (1,0) [0|0] "" GTW
 SG_ EPBM_w114_unparkNotAllowed : 49|1@1+ (1,0) [0|0] "" GTW
 SG_ EPBM_w115_rightNVoltageLow : 50|1@1+ (1,0) [0|0] "" GTW
 SG_ EPBM_w116_rightPVoltageHigh : 51|1@1+ (1,0) [0|0] "" GTW
 SG_ EPBM_w117_usedFallbackValues : 52|1@1+ (1,0) [0|0] "" GTW
 SG_ EPBM_w118_unused : 53|1@1+ (1,0) [0|0] "" GTW
 SG_ EPBM_w119_unused : 54|1@1+ (1,0) [0|0] "" GTW
 SG_ EPBM_w120_unused : 55|1@1+ (1,0) [0|0] "" GTW
 SG_ EPBM_w121_unused : 56|1@1+ (1,0) [0|0] "" GTW
 SG_ EPBM_w122_unused : 57|1@1+ (1,0) [0|0] "" GTW
 SG_ EPBM_w123_unused : 58|1@1+ (1,0) [0|0] "" GTW
 SG_ EPBM_w124_unused : 59|1@1+ (1,0) [0|0] "" GTW
 SG_ EPBM_w125_unused : 60|1@1+ (1,0) [0|0] "" GTW
 SG_ EPBM_w126_unused : 61|1@1+ (1,0) [0|0] "" GTW
 SG_ EPBM_w127_unused : 62|1@1+ (1,0) [0|0] "" GTW
 SG_ EPBM_w128_unused : 63|1@1+ (1,0) [0|0] "" GTW

BO_ 1527 EPBM_bootID: 8 EPBM
 SG_ EPBM_bootIdData : 0|64@1+ (1,0) [0|0] "" GTWU

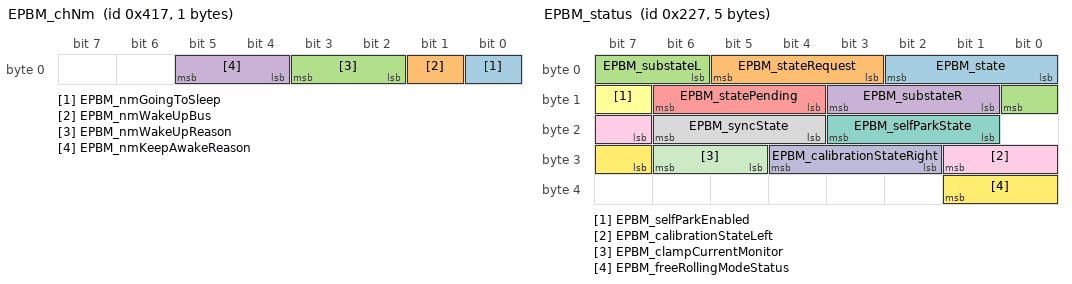
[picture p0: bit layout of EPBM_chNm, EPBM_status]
BO_ 1047 EPBM_chNm: 1 EPBM
 SG_ EPBM_nmGoingToSleep : 0|1@1+ (1,0) [0|0] "" GTW
 SG_ EPBM_nmWakeUpBus : 1|1@1+ (1,0) [0|0] "" GTW
 SG_ EPBM_nmWakeUpReason : 2|2@1+ (1,0) [0|0] "" GTW
 SG_ EPBM_nmKeepAwakeReason : 4|2@1+ (1,0) [0|0] "" GTW

BO_ 1815 EPBM_debugOutput: 8 EPBM
 SG_ EPBM_debugOutput M : 0|8@1+ (1,0) [0|0] "" DBG
 SG_ EPBM_armRelease m0 : 21|1@1+ (1,0) [0|0] "" DBG
 SG_ EPBM_CAN_brakeHwType m0 : 22|2@1+ (1,0) [0|2] "" DBG
 SG_ EPBM_EPB_brakeHwType m0 : 24|2@1+ (1,0) [0|2] "" DBG
 SG_ EPBM_CAN_brakeHwTypeMismatch m0 : 26|1@1+ (1,0) [0|0] "" DBG
 SG_ EPBM_EPB_brakeHwTypeMismatch m0 : 27|1@1+ (1,0) [0|0] "" DBG
 SG_ EPBM_BOTH_brakeHwTypeMismatch m0 : 28|1@1+ (1,0) [0|0] "" DBG
 SG_ EPBM_CAN_chassisType m0 : 29|2@1+ (1,0) [0|2] "" DBG
 SG_ EPBM_EPB_chassisType m0 : 31|2@1+ (1,0) [0|2] "" DBG
 SG_ EPBM_CAN_chassisTypeMismatch m0 : 33|1@1+ (1,0) [0|0] "" DBG
 SG_ EPBM_EPB_chassisTypeMismatch m0 : 34|1@1+ (1,0) [0|0] "" DBG
 SG_ EPBM_BOTH_chassisTypeMismatch m0 : 35|1@1+ (1,0) [0|0] "" DBG
 SG_ EPBM_leftMotorEna m0 : 36|1@1+ (1,0) [0|0] "" DBG
 SG_ EPBM_rightMotorEna m0 : 37|1@1+ (1,0) [0|0] "" DBG
 SG_ EPBM_diEpbUnparkRequest m0 : 38|1@1+ (1,0) [0|0] "" DBG
 SG_ EPBM_leftVoltageCounts m0 : 40|12@1+ (1,0) [0|0] "" DBG
 SG_ EPBM_3VFilt m0 : 52|12@1+ (0.0008056640625,0) [0|0] "V" DBG
 SG_ EPBM_leftCurrentFilt m1 : 8|12@1+ (0.017346834,-37.87878788) [0|0] "A" DBG
 SG_ EPBM_rightCurrentFilt m1 : 24|12@1+ (0.017346834,-37.87878788) [0|0] "A" DBG
 SG_ EPBM_EPB_state m1 : 40|12@1+ (1,0) [0|0] "" DBG
 SG_ EPBM_5VFilt m1 : 52|12@1+ (0.001220703125,0) [0|0] "V" DBG
 SG_ EPBM_12VFilt m2 : 8|12@1+ (0.00544367,0) [0|0] "V" DBG
 SG_ EPBM_EPB_reqState m2 : 24|12@1+ (1,0) [0|0] "" DBG
 SG_ EPBM_EPB_substateL m2 : 40|12@1+ (1,0) [0|0] "" DBG
 SG_ EPBM_dynamic m2 : 55|1@1+ (1,0) [0|0] "" DBG
 SG_ EPBM_autoReapplyRequested m2 : 56|2@1+ (1,0) [0|0] "" DBG
 SG_ EPBM_leftPVFilt m3 : 8|12@1+ (0.004833984375,0) [0|0] "V" DBG
 SG_ EPBM_rightPVFilt m3 : 24|12@1+ (0.004833984375,0) [0|0] "V" DBG
 SG_ EPBM_EPB_substateR m3 : 40|12@1+ (1,0) [0|0] "" DBG
 SG_ EPBM_leftNVFilt m4 : 8|12@1+ (0.004833984375,0) [0|0] "V" DBG
 SG_ EPBM_rightNVFilt m4 : 24|12@1+ (0.004833984375,0) [0|0] "V" DBG
 SG_ EPBM_rightVoltageCounts m4 : 40|12@1+ (1,0) [0|0] "" DBG
 SG_ EPBM_batt1 m5 : 8|12@1+ (0.00544367,0) [0|0] "V" DBG
 SG_ EPBM_batt2 m5 : 24|12@1+ (0.00544367,0) [0|0] "V" DBG
 SG_ EPBM_transitionL m5 : 36|1@1+ (1,0) [0|0] "" DBG
 SG_ EPBM_transitionR m5 : 37|1@1+ (1,0) [0|0] "" DBG
 SG_ EPBM_selfParkFaultReason m5 : 40|8@1+ (1,0) [0|0] "" DBG
 SG_ EPBM_currentDiffMaxLeft m6 : 8|12@1+ (0.244140625,0) [0|0] "mA" DBG
 SG_ EPBM_currentDiffMaxRight m6 : 20|12@1+ (0.244140625,0) [0|0] "mA" DBG
 SG_ EPBM_uncalibratedCurrentLeft m7 : 8|12@1+ (0.017346834,-37.87878788) [0|0] "A" DBG
 SG_ EPBM_uncalibratedCurrentRight m7 : 20|12@1+ (0.017346834,-37.87878788) [0|0] "A" DBG
 SG_ EPBM_currentDiffLeft m7 : 32|12@1+ (0.017346834,-37.87878788) [0|0] "A" DBG
 SG_ EPBM_currentDiffRight m7 : 44|12@1+ (0.017346834,-37.87878788) [0|0] "A" DBG
 SG_ EPBM_currentOffsetLeft m8 : 8|12@1+ (0.017346834,-37.87878788) [0|0] "A" DBG
 SG_ EPBM_currentOffsetRight m8 : 20|12@1+ (0.017346834,-37.87878788) [0|0] "A" DBG
 SG_ EPBM_currentPeakLeft m8 : 32|12@1+ (0.017346834,-37.87878788) [0|0] "A" DBG
 SG_ EPBM_currentPeakRight m8 : 44|12@1+ (0.017346834,-37.87878788) [0|0] "A" DBG
 SG_ EPBM_triggerReason m8 : 56|5@1+ (1,0) [0|0] "" GTW
 SG_ EPBM_currentOffsetMaxLeft m9 : 8|12@1+ (0.017346834,-37.87878788) [0|0] "A" DBG
 SG_ EPBM_currentOffsetMinLeft m9 : 20|12@1+ (0.017346834,-37.87878788) [0|0] "A" DBG
 SG_ EPBM_currentOffsetMaxRight m9 : 32|12@1+ (0.017346834,-37.87878788) [0|0] "A" DBG
 SG_ EPBM_currentOffsetMinRight m9 : 44|12@1+ (0.017346834,-37.87878788) [0|0] "A" DBG
 SG_ EPBM_nmState m9 : 56|3@1+ (1,0) [0|0] "" DBG
 SG_ EPBM_offsetApplied m9 : 62|2@1+ (1,0) [0|0] "" DBG

BO_ 1831 EPBM_debugOutput2: 8 EPBM
 SG_ EPBM_debugOutput2 M : 0|8@1+ (1,0) [0|0] "" DBG
 SG_ EPBM_idleStack m0 : 8|16@1+ (1,0) [0|0] "" DBG
 SG_ EPBM_delayL m0 : 40|12@1+ (1,0) [0|0] "" DBG
 SG_ EPBM_delayR m0 : 52|12@1+ (1,0) [0|0] "" DBG
 SG_ EPBM_currentOffsetStatSatLeft m2 : 8|12@1+ (0.017346834,-37.87878788) [0|0] "A" DBG
 SG_ EPBM_currentOffsetStatSatRight m2 : 20|12@1+ (0.017346834,-37.87878788) [0|0] "A" DBG
 SG_ EPBM_currentOffsetDynSatLeft m2 : 32|12@1+ (0.017346834,-37.87878788) [0|0] "A" DBG
 SG_ EPBM_currentOffsetDynSatRight m2 : 44|12@1+ (0.017346834,-37.87878788) [0|0] "A" DBG
 SG_ EPBM_currentOffsetReleaseLeft m3 : 8|12@1+ (0.017346834,-37.87878788) [0|0] "A" DBG
 SG_ EPBM_currentOffsetReleaseRight m3 : 20|12@1+ (0.017346834,-37.87878788) [0|0] "A" DBG
 SG_ EPBM_inrushTimerL m3 : 32|12@1+ (1,0) [0|0] "" DBG
 SG_ EPBM_inrushTimerR m3 : 44|12@1+ (1,0) [0|0] "" DBG

BO_ 1335 EPBM_info: 8 EPBM
 SG_ EPBM_infoIndex M : 0|8@1+ (1,0) [0|0] "" GTW,GTWU
 SG_ EPBM_infoBuildType m10 : 8|8@1+ (1,0) [0|0] "" GTW
 SG_ EPBM_infoBuildConfigID m10 : 16|16@1+ (1,0) [0|0] "" GTW
 SG_ EPBM_infoHardwareID m10 : 32|16@1+ (1,0) [0|0] "" GTW
 SG_ EPBM_infoComponentID m10 : 48|16@1+ (1,0) [0|0] "" GTW
 SG_ EPBM_infoPcbaID m11 : 16|8@1+ (1,0) [0|0] "" GTW
 SG_ EPBM_infoAssemblyID m11 : 24|8@1+ (1,0) [0|255] "" GTW
 SG_ EPBM_infoUsageID m11 : 32|16@1+ (1,0) [0|65535] "" GTW
 SG_ EPBM_infoSubUsageID m11 : 48|16@1+ (1,0) [0|65535] "" GTW
 SG_ EPBM_infoApplicationCRC m13 : 32|32@1+ (1,0) [0|0] "" GTW,GTWU
 SG_ EPBM_infoBootloaderSvnRevision m14 : 8|24@1+ (1,0) [0|0] "" GTW
 SG_ EPBM_infoAppGitHashBytes m17 : 8|56@1+ (1,0) [0|0] "" GTW
 SG_ EPBM_infoBootGitHashBytes m18 : 8|56@1+ (1,0) [0|0] "" GTW
 SG_ EPBM_infoPlatformType m19 : 8|8@1+ (1,0) [0|0] "" GTW
 SG_ EPBM_infoMajorVersion m19 : 16|8@1+ (1,0) [0|0] "" GTW
 SG_ EPBM_infoBranchOrigin m19 : 24|8@1+ (1,0) [0|0] "" GTW
 SG_ EPBM_infoMaturity m19 : 32|8@1+ (1,0) [0|0] "" GTW
 SG_ EPBM_infoHardwareRevision m19 : 40|8@1+ (1,0) [0|0] "" GTW
 SG_ EPBM_infoBootUdsProtoVersion m20 : 8|8@1+ (1,0) [0|0] "" GTW
 SG_ EPBM_infoBootloaderCRC m20 : 32|32@1+ (1,0) [0|0] "" GTW

BO_ 551 EPBM_status: 5 EPBM
 SG_ EPBM_state : 0|3@1+ (1,0) [0|0] "" GTW,EPB
 SG_ EPBM_stateRequest : 3|3@1+ (1,0) [0|0] "" GTW
 SG_ EPBM_substateL : 6|3@1+ (1,0) [0|0] "" GTW
 SG_ EPBM_substateR : 9|3@1+ (1,0) [0|0] "" GTW
 SG_ EPBM_statePending : 12|3@1+ (1,0) [0|0] "" GTW
 SG_ EPBM_selfParkEnabled : 15|1@1+ (1,0) [0|3] "" GTW
 SG_ EPBM_selfParkState : 17|3@1+ (1,0) [0|7] "" GTW
 SG_ EPBM_syncState : 20|3@1+ (1,0) [0|7] "" GTW
 SG_ EPBM_calibrationStateLeft : 23|3@1+ (1,0) [0|0] "" GTW
 SG_ EPBM_calibrationStateRight : 26|3@1+ (1,0) [0|0] "" GTW
 SG_ EPBM_clampCurrentMonitor : 29|2@1+ (1,0) [0|0] "" GTW
 SG_ EPBM_freeRollingModeStatus : 31|3@1+ (1,0) [0|0] "" GTW

BO_ 1623 EPBM_udsResponse: 8 EPBM
 SG_ EPBM_udsResponseData_H : 7|32@0+ (1,0) [0|4294967295] "" GTW,GTWU
 SG_ EPBM_udsResponseData_L : 39|32@0+ (1,0) [0|4294967295] "" GTW,GTWU

BO_ 1476 EPB_alertLog: 8 EPB
 SG_ EPB_alertID M : 0|15@1+ (1,0) [0|0] "" GTW,APP
 SG_ EPB_alertType : 15|1@1+ (1,0) [0|0] "" GTW
 SG_ EPB_a001_leftEncIntrpt m1 : 16|16@1+ (1,0) [0|0] "" GTW
 SG_ EPB_a002_leftIdleOc m2 : 16|16@1+ (0.00080566952,0) [0|0] "V" GTW
 SG_ EPB_a003_leftEncIrrational m3 : 16|16@1+ (0.00080566952,0) [0|0] "V" GTW
 SG_ EPB_a005_leftOc m5 : 16|16@1+ (0.017346834,-37.87878788) [0|0] "A" GTW
 SG_ EPB_a006_leftUc m6 : 16|16@1+ (0.017346834,-37.87878788) [0|0] "A" GTW
 SG_ EPB_a007_leftEndStop m7 : 16|16@1+ (1,0) [0|0] "" GTW
 SG_ EPB_a008_encPosition m8 : 16|16@1+ (1,0) [0|0] "" GTW
 SG_ EPB_a008_voltageCounts m8 : 32|16@1+ (1,0) [0|0] "" GTW
 SG_ EPB_a009_voltageN m9 : 16|16@1+ (0.004833984375,0) [0|0] "V" GTW
 SG_ EPB_a009_voltageP m9 : 32|16@1+ (0.004833984375,0) [0|0] "V" GTW
 SG_ EPB_a010_voltageN m10 : 16|16@1+ (0.004833984375,0) [0|0] "V" GTW
 SG_ EPB_a010_voltageP m10 : 32|16@1+ (0.004833984375,0) [0|0] "V" GTW
 SG_ EPB_a011_voltageN m11 : 16|16@1+ (0.004833984375,0) [0|0] "V" GTW
 SG_ EPB_a011_voltageP m11 : 32|16@1+ (0.004833984375,0) [0|0] "V" GTW
 SG_ EPB_a012_voltageN m12 : 16|16@1+ (0.004833984375,0) [0|0] "V" GTW
 SG_ EPB_a012_voltageP m12 : 32|16@1+ (0.004833984375,0) [0|0] "V" GTW
 SG_ EPB_a013_reqState m13 : 16|16@1+ (1,0) [0|0] "" GTW
 SG_ EPB_a013_substate m13 : 32|16@1+ (1,0) [0|0] "" GTW
 SG_ EPB_a014_reqState m14 : 16|16@1+ (1,0) [0|0] "" GTW
 SG_ EPB_a014_substate m14 : 32|16@1+ (1,0) [0|0] "" GTW
 SG_ EPB_a015_state m15 : 16|4@1+ (1,0) [0|0] "" GTW
 SG_ EPB_a015_reqState m15 : 20|4@1+ (1,0) [0|0] "" GTW
 SG_ EPB_a015_voltageCounts m15 : 24|12@1+ (1,0) [0|0] "" GTW
 SG_ EPB_a015_encPosition m15 : 36|12@1+ (1,0) [0|0] "" GTW
 SG_ EPB_a016_leftPHalfBridge m16 : 16|16@1+ (1,0) [0|0] "" GTW
 SG_ EPB_a017_leftNHalfBridge m17 : 16|16@1+ (1,0) [0|0] "" GTW
 SG_ EPB_a018_voltageN m18 : 16|16@1+ (0.004833984375,0) [0|0] "V" GTW
 SG_ EPB_a018_voltageP m18 : 32|16@1+ (0.004833984375,0) [0|0] "V" GTW
 SG_ EPB_a019_voltageN m19 : 16|16@1+ (0.004833984375,0) [0|0] "V" GTW
 SG_ EPB_a019_voltageP m19 : 32|16@1+ (0.004833984375,0) [0|0] "V" GTW
 SG_ EPB_a020_voltageN m20 : 16|16@1+ (0.004833984375,0) [0|0] "V" GTW
 SG_ EPB_a020_voltageP m20 : 32|16@1+ (0.004833984375,0) [0|0] "V" GTW
 SG_ EPB_a021_voltageN m21 : 16|16@1+ (0.004833984375,0) [0|0] "V" GTW
 SG_ EPB_a021_voltageP m21 : 32|16@1+ (0.004833984375,0) [0|0] "V" GTW
 SG_ EPB_a022_EPBsubstate m22 : 16|16@1+ (1,0) [0|0] "" GTW
 SG_ EPB_a022_EPBMsubstate m22 : 32|16@1+ (1,0) [0|0] "" GTW
 SG_ EPB_a023_leftFirstShortApply m23 : 16|16@1+ (1,0) [0|0] "" GTW
 SG_ EPB_a024_noLoadCurrent m24 : 16|16@1+ (0.017346834,-37.87878788) [0|0] "A" GTW
 SG_ EPB_a025_noLoadCurrent m25 : 16|16@1+ (0.017346834,-37.87878788) [0|0] "A" GTW
 SG_ EPB_a025_encPosition m25 : 32|16@1+ (1,0) [0|0] "" GTW
 SG_ EPB_a025_voltageCounts m25 : 48|16@1+ (1,0) [0|0] "" GTW
 SG_ EPB_a026_uncalibratedCurrent m26 : 16|12@1+ (0.017346834,-37.87878788) [0|0] "A" GTW
 SG_ EPB_a026_calibratedCurrent m26 : 28|12@1+ (0.017346834,-37.87878788) [0|0] "A" GTW
 SG_ EPB_a027_encoderElapsed m27 : 16|16@1+ (1,0) [0|0] "" GTW
 SG_ EPB_a028_EPBreqState m28 : 16|16@1+ (1,0) [0|0] "" GTW
 SG_ EPB_a028_EPBMreqState m28 : 32|16@1+ (1,0) [0|0] "" GTW
 SG_ EPB_a029_EPBstate m29 : 16|16@1+ (1,0) [0|0] "" GTW
 SG_ EPB_a029_EPBMstate m29 : 32|16@1+ (1,0) [0|0] "" GTW
 SG_ EPB_a030_spiCksum m30 : 16|16@1+ (1,0) [0|0] "" GTW
 SG_ EPB_a030_calcCksum m30 : 32|16@1+ (1,0) [0|0] "" GTW
 SG_ EPB_a031_CHG_status m31 : 16|16@1+ (1,0) [0|0] "" GTW
 SG_ EPB_a032_canDisabled m32 : 16|16@1+ (1,0) [0|0] "" GTW
 SG_ EPB_a033_canID m33 : 16|12@1+ (1,0) [0|0] "" GTW
 SG_ EPB_a033_mbox m33 : 28|4@1+ (1,0) [0|0] "" GTW
 SG_ EPB_a034_canID m34 : 16|12@1+ (1,0) [0|0] "" GTW
 SG_ EPB_a034_errorType m34 : 28|4@1+ (1,0) [0|0] "" GTW
 SG_ EPB_a034_badValue1 m34 : 32|16@1+ (1,0) [0|0] "" GTW
 SG_ EPB_a034_badValue2 m34 : 48|16@1+ (1,0) [0|0] "" GTW
 SG_ EPB_canAddress m35 : 16|12@1+ (1,0) [0|0] "" GTW
 SG_ EPB_canErrorType m35 : 28|4@1+ (1,0) [0|0] "" GTW
 SG_ EPB_canErrorWord1 m35 : 32|16@1+ (1,0) [0|0] "" GTW
 SG_ EPB_canErrorWord2 m35 : 48|16@1+ (1,0) [0|0] "" GTW
 SG_ EPB_a036_canOverrun m36 : 16|16@1+ (1,0) [0|0] "" GTW
 SG_ EPB_a037_firmware m37 : 16|16@1+ (1,0) [0|0] "" GTW
 SG_ EPB_eepromErrorType m38 : 16|16@1+ (1,0) [0|0] "" GTW
 SG_ EPB_a039_watchdogReset m39 : 16|16@1+ (1,0) [0|0] "" GTW
 SG_ EPB_a040_memoryError m40 : 16|16@1+ (1,0) [0|0] "" GTW
 SG_ EPB_a041_spiOpen m41 : 16|16@1+ (1,0) [0|0] "" GTW
 SG_ EPB_a042_spiRead m42 : 16|16@1+ (1,0) [0|0] "" GTW
 SG_ EPB_a043_ESP_A m43 : 16|16@1+ (1,0) [0|0] "" GTW
 SG_ EPB_a043_ESP_E m43 : 32|16@1+ (1,0) [0|0] "" GTW
 SG_ EPB_a043_ESP_B m43 : 48|16@1+ (1,0) [0|0] "" GTW
 SG_ EPB_a044_DI_Torque1 m44 : 16|1@1+ (1,0) [0|0] "" GTW
 SG_ EPB_a044_DI_Torque2 m44 : 17|1@1+ (1,0) [0|0] "" GTW
 SG_ EPB_a044_DI_state m44 : 18|1@1+ (1,0) [0|0] "" GTW
 SG_ EPB_a044_DI_state2 m44 : 19|1@1+ (1,0) [0|0] "" GTW
 SG_ EPB_a045_GTW_status m45 : 16|1@1+ (1,0) [0|0] "" GTW
 SG_ EPB_a045_GTW_chControl m45 : 17|1@1+ (1,0) [0|0] "" GTW
 SG_ EPB_a045_GTW_odo m45 : 18|1@1+ (1,0) [0|0] "" GTW
 SG_ EPB_a045_GTW_carConfig m45 : 19|1@1+ (1,0) [0|0] "" GTW
 SG_ EPB_a046_SBW_RQ_SCCM m46 : 16|1@1+ (1,0) [0|0] "" GTW
 SG_ EPB_a046_STW_ACTN_RQ m46 : 17|1@1+ (1,0) [0|0] "" GTW
 SG_ EPB_a047_EPBM_status m47 : 16|16@1+ (1,0) [0|0] "" GTW
 SG_ EPB_a048_MCU_chControl m48 : 16|16@1+ (1,0) [0|0] "" GTW
 SG_ EPB_a048_MCU_chControl2 m48 : 32|1@1+ (1,0) [0|0] "" GTW
 SG_ EPB_a049_ESP_125h m49 : 16|1@1+ (1,0) [0|0] "" GTW
 SG_ EPB_a049_ESP_A m49 : 17|1@1+ (1,0) [0|0] "" GTW
 SG_ EPB_a049_ESP_B m49 : 18|1@1+ (1,0) [0|0] "" GTW
 SG_ EPB_a049_ESP_E m49 : 19|1@1+ (1,0) [0|0] "" GTW
 SG_ EPB_a049_ESP_C m49 : 20|1@1+ (1,0) [0|0] "" GTW
 SG_ EPB_a049_ESP_wheelSpeeds m49 : 21|1@1+ (1,0) [0|0] "" GTW
 SG_ EPB_a049_ESP_145h m49 : 22|1@1+ (1,0) [0|0] "" GTW
 SG_ EPB_a049_ESP_115h m49 : 23|1@1+ (1,0) [0|0] "" GTW
 SG_ EPB_a050_resetRequired m50 : 16|16@1+ (1,0) [0|0] "" GTW
 SG_ EPB_a051_epbNotApplied m51 : 16|16@1+ (1,0) [0|0] "" GTW
 SG_ EPB_a052_epbProblem m52 : 16|16@1+ (1,0) [0|0] "" GTW
 SG_ EPB_a053_epbNotReleased m53 : 16|16@1+ (1,0) [0|0] "" GTW
 SG_ EPB_a054_severeShortApply m54 : 16|16@1+ (1,0) [0|0] "" GTW
 SG_ EPB_a055_taskID m55 : 16|8@1+ (1,0) [0|0] "" GTW
 SG_ EPB_a055_stackUsed m55 : 32|16@1+ (1,0) [0|0] "" GTW
 SG_ EPB_a055_stackSize m55 : 48|16@1+ (1,0) [0|0] "" GTW
 SG_ EPB_a056_twelveV m56 : 16|16@1+ (0.004833984375,0) [0|0] "V" GTW
 SG_ EPB_a057_twelveV m57 : 16|16@1+ (0.004833984375,0) [0|0] "V" GTW
 SG_ EPB_a058_5vLost m58 : 16|16@1+ (1,0) [0|0] "" GTW
 SG_ EPB_a059_batt1 m59 : 16|16@1+ (0.004833984375,0) [0|0] "V" GTW
 SG_ EPB_a059_batt2 m59 : 32|16@1+ (0.004833984375,0) [0|0] "V" GTW
 SG_ EPB_a060_maxCycles1 m60 : 16|16@1+ (1,0) [0|0] "" GTW
 SG_ EPB_a061_maxCycles2 m61 : 16|16@1+ (1,0) [0|0] "" GTW
 SG_ EPB_a062_diGear m62 : 16|16@1+ (1,0) [0|0] "" GTW
 SG_ EPB_a062_state m62 : 32|16@1+ (1,0) [0|0] "" GTW
 SG_ EPB_a063_frontWhlSpeed m63 : 16|16@1+ (0.01,0) [0|327.67] "MPH" GTW
 SG_ EPB_a063_rearWhlSpeed m63 : 32|16@1+ (0.01,0) [0|327.67] "MPH" GTW
 SG_ EPB_a063_motorMPH m63 : 48|16@1+ (0.01,0) [0|0] "MPH" GTW
 SG_ EPB_a064_EPBMTimeout m64 : 16|16@1+ (1,0) [0|0] "" GTW
 SG_ EPB_a065_rightEncIntrpt m65 : 16|16@1+ (1,0) [0|0] "" GTW
 SG_ EPB_a066_rightIdleOc m66 : 16|16@1+ (0.00080566952,0) [0|0] "V" GTW
 SG_ EPB_a067_rightEncIrrational m67 : 16|16@1+ (0.00080566952,0) [0|0] "V" GTW
 SG_ EPB_a069_rightOc m69 : 16|16@1+ (0.017346834,-37.87878788) [0|0] "A" GTW
 SG_ EPB_a070_rightUc m70 : 16|16@1+ (0.017346834,-37.87878788) [0|0] "A" GTW
 SG_ EPB_a071_rightEndStop m71 : 16|16@1+ (0.01115686274,0) [0|0] "" GTW
 SG_ EPB_a072_encPosition m72 : 16|16@1+ (1,0) [0|0] "" GTW
 SG_ EPB_a072_voltageCounts m72 : 32|16@1+ (1,0) [0|0] "" GTW
 SG_ EPB_a073_voltageN m73 : 16|16@1+ (0.004833984375,0) [0|0] "V" GTW
 SG_ EPB_a073_voltageP m73 : 32|16@1+ (0.004833984375,0) [0|0] "V" GTW
 SG_ EPB_a074_voltageN m74 : 16|16@1+ (0.004833984375,0) [0|0] "V" GTW
 SG_ EPB_a074_voltageP m74 : 32|16@1+ (0.004833984375,0) [0|0] "V" GTW
 SG_ EPB_a075_voltageN m75 : 16|16@1+ (0.004833984375,0) [0|0] "V" GTW
 SG_ EPB_a075_voltageP m75 : 32|16@1+ (0.004833984375,0) [0|0] "V" GTW
 SG_ EPB_a076_voltageN m76 : 16|16@1+ (0.004833984375,0) [0|0] "V" GTW
 SG_ EPB_a076_voltageP m76 : 32|16@1+ (0.004833984375,0) [0|0] "V" GTW
 SG_ EPB_a077_reqState m77 : 16|16@1+ (1,0) [0|0] "" GTW
 SG_ EPB_a077_substate m77 : 32|16@1+ (1,0) [0|0] "" GTW
 SG_ EPB_a078_reqState m78 : 16|16@1+ (1,0) [0|0] "" GTW
 SG_ EPB_a078_substate m78 : 32|16@1+ (1,0) [0|0] "" GTW
 SG_ EPB_a079_state m79 : 16|4@1+ (1,0) [0|0] "" GTW
 SG_ EPB_a079_reqState m79 : 20|4@1+ (1,0) [0|0] "" GTW
 SG_ EPB_a079_voltageCounts m79 : 24|12@1+ (1,0) [0|0] "" GTW
 SG_ EPB_a079_encPosition m79 : 36|12@1+ (1,0) [0|0] "" GTW
 SG_ EPB_a080_rightPHalfBridge m80 : 16|16@1+ (1,0) [0|0] "" GTW
 SG_ EPB_a081_rightNHalfBridge m81 : 16|16@1+ (1,0) [0|0] "" GTW
 SG_ EPB_a082_voltageN m82 : 16|16@1+ (0.004833984375,0) [0|0] "V" GTW
 SG_ EPB_a082_voltageP m82 : 32|16@1+ (0.004833984375,0) [0|0] "V" GTW
 SG_ EPB_a083_voltageN m83 : 16|16@1+ (0.004833984375,0) [0|0] "V" GTW
 SG_ EPB_a083_voltageP m83 : 32|16@1+ (0.004833984375,0) [0|0] "V" GTW
 SG_ EPB_a084_voltageN m84 : 16|16@1+ (0.004833984375,0) [0|0] "V" GTW
 SG_ EPB_a084_voltageP m84 : 32|16@1+ (0.004833984375,0) [0|0] "V" GTW
 SG_ EPB_a085_voltageN m85 : 16|16@1+ (0.004833984375,0) [0|0] "V" GTW
 SG_ EPB_a085_voltageP m85 : 32|16@1+ (0.004833984375,0) [0|0] "V" GTW
 SG_ EPB_a086_EPBsubstate m86 : 16|16@1+ (1,0) [0|0] "" GTW
 SG_ EPB_a086_EPBMsubstate m86 : 32|16@1+ (1,0) [0|0] "" GTW
 SG_ EPB_a087_rightFirstShortApply m87 : 16|16@1+ (1,0) [0|0] "" GTW
 SG_ EPB_a088_noLoadCurrent m88 : 16|16@1+ (0.017346834,-37.87878788) [0|0] "A" GTW
 SG_ EPB_a089_noLoadCurrent m89 : 16|12@1+ (0.017346834,-37.87878788) [0|0] "A" GTW
 SG_ EPB_a089_encPosition m89 : 32|16@1+ (1,0) [0|0] "" GTW
 SG_ EPB_a089_voltageCounts m89 : 48|16@1+ (1,0) [0|0] "" GTW
 SG_ EPB_a090_uncalibratedCurrent m90 : 16|12@1+ (0.017346834,-37.87878788) [0|0] "A" GTW
 SG_ EPB_a090_calibratedCurrent m90 : 28|12@1+ (0.017346834,-37.87878788) [0|0] "A" GTW
 SG_ EPB_a090_side m90 : 40|1@1+ (1,0) [0|0] "" GTW
 SG_ EPB_a091_encoderElapsed m91 : 16|16@1+ (1,0) [0|0] "" GTW
 SG_ EPB_a093_DAS_steeringControl m93 : 16|1@1+ (1,0) [0|0] "" GTW
 SG_ EPB_a093_DAS_pscControl m93 : 17|1@1+ (1,0) [0|0] "" GTW
 SG_ EPB_a093_DAS_control m93 : 19|1@1+ (1,0) [0|0] "" GTW
 SG_ EPB_a093_DAS_status2 m93 : 20|1@1+ (1,0) [0|0] "" GTW
 SG_ EPB_a093_DAS_status m93 : 21|1@1+ (1,0) [0|0] "" GTW
 SG_ EPB_a094_inhibitEacReason m94 : 16|16@1+ (1,0) [0|0] "" GTW
 SG_ EPB_a095_expectedConfig m95 : 16|3@1+ (1,0) [0|0] "" GTW
 SG_ EPB_a095_actualConfig m95 : 19|3@1+ (1,0) [0|0] "" GTW
 SG_ EPB_a095_learnedConfig m95 : 22|3@1+ (1,0) [0|0] "" GTW
 SG_ EPB_a095_alertLatch m95 : 25|10@1+ (1,0) [0|0] "" GTW
 SG_ EPB_a095_chassisType m95 : 48|1@1+ (1,0) [0|0] "" GTW
 SG_ EPB_a095_epasType m95 : 49|1@1+ (1,0) [0|0] "" GTW
 SG_ EPB_a095_autopilotType m95 : 50|1@1+ (1,0) [0|0] "" GTW
 SG_ EPB_a095_brakeHwType m95 : 51|1@1+ (1,0) [0|0] "" GTW
 SG_ EPB_a095_timeout m95 : 52|1@1+ (1,0) [0|0] "" GTW
 SG_ EPB_a095_efuseType m95 : 53|1@1+ (1,0) [0|0] "" GTW
 SG_ EPB_a096_EPAS_sysStatus m96 : 16|1@1+ (1,0) [0|0] "" GTW
 SG_ EPB_a097_selfParkAbortReason m97 : 16|16@1+ (1,0) [0|0] "" GTW
 SG_ EPB_a098_parkOocStatus m98 : 16|1@1+ (1,0) [0|0] "" GTW
 SG_ EPB_a099_pmState2 m99 : 16|1@1+ (1,0) [0|0] "" GTW
 SG_ EPB_a100_uncalibratedCurrentL m100 : 16|12@1+ (0.017346834,-37.87878788) [0|0] "A" GTW
 SG_ EPB_a100_uncalibratedCurrentR m100 : 28|12@1+ (0.017346834,-37.87878788) [0|0] "A" GTW
 SG_ EPB_a101_uncalibratedCurrentL m101 : 16|12@1+ (0.017346834,-37.87878788) [0|0] "A" GTW
 SG_ EPB_a101_uncalibratedCurrentR m101 : 28|12@1+ (0.017346834,-37.87878788) [0|0] "A" GTW
 SG_ EPB_a101_side m101 : 40|1@1+ (1,0) [0|0] "" GTW
 SG_ EPB_a102_stateDataCorrupt m102 : 16|1@1+ (1,0) [0|0] "" GTW
 SG_ EPB_a102_statisticsCorrupt m102 : 17|1@1+ (1,0) [0|0] "" GTW
 SG_ EPB_a102_brakeHwTypeCorrupt m102 : 18|1@1+ (1,0) [0|0] "" GTW
 SG_ EPB_a102_epasTypeCorrupt m102 : 19|1@1+ (1,0) [0|0] "" GTW
 SG_ EPB_a102_chassisTypeCorrupt m102 : 20|1@1+ (1,0) [0|0] "" GTW
 SG_ EPB_a103_datatype m103 : 16|4@1+ (1,0) [0|0] "" GTW
 SG_ EPB_a103_oldVersion m103 : 20|3@1+ (1,0) [0|0] "" GTW
 SG_ EPB_a103_newVersion m103 : 23|3@1+ (1,0) [0|0] "" GTW
 SG_ EPB_a106_voltageN m106 : 16|16@1+ (0.004833984375,0) [0|0] "V" GTW
 SG_ EPB_a106_voltageP m106 : 32|16@1+ (0.004833984375,0) [0|0] "V" GTW
 SG_ EPB_a107_voltageN m107 : 16|16@1+ (0.004833984375,0) [0|0] "V" GTW
 SG_ EPB_a107_voltageP m107 : 32|16@1+ (0.004833984375,0) [0|0] "V" GTW
 SG_ EPB_a108_voltageN m108 : 16|16@1+ (0.004833984375,0) [0|0] "V" GTW
 SG_ EPB_a108_voltageP m108 : 32|16@1+ (0.004833984375,0) [0|0] "V" GTW
 SG_ EPB_a109_voltageN m109 : 16|16@1+ (0.004833984375,0) [0|0] "V" GTW
 SG_ EPB_a109_voltageP m109 : 32|16@1+ (0.004833984375,0) [0|0] "V" GTW
 SG_ EPB_a110_offsetApplied m110 : 16|2@1+ (1,0) [0|0] "" GTW
 SG_ EPB_a110_uncalibratedCurrent m110 : 18|12@1+ (0.017346834,-37.87878788) [0|0] "A" GTW
 SG_ EPB_a110_appliedOffsetValue m110 : 30|12@1+ (0.017346834,-37.87878788) [0|0] "A" GTW
 SG_ EPB_a111_offsetApplied m111 : 16|2@1+ (1,0) [0|0] "" GTW
 SG_ EPB_a111_uncalibratedCurrent m111 : 18|12@1+ (0.017346834,-37.87878788) [0|0] "A" GTW
 SG_ EPB_a111_appliedOffsetValue m111 : 30|12@1+ (0.017346834,-37.87878788) [0|0] "A" GTW
 SG_ EPB_a112_offsetApplied m112 : 16|2@1+ (1,0) [0|0] "" GTW
 SG_ EPB_a112_uncalibratedCurrent m112 : 18|12@1+ (0.017346834,-37.87878788) [0|0] "A" GTW
 SG_ EPB_a113_offsetApplied m113 : 16|2@1+ (1,0) [0|0] "" GTW
 SG_ EPB_a113_uncalibratedCurrent m113 : 18|12@1+ (0.017346834,-37.87878788) [0|0] "A" GTW
 SG_ EPB_a114_voltage1 m114 : 16|16@1+ (0.004833984375,0) [0|0] "V" GTW
 SG_ EPB_a114_voltage2 m114 : 32|16@1+ (0.004833984375,0) [0|0] "V" GTW
 SG_ EPB_a114_alertID m114 : 48|15@1+ (1,0) [0|0] "" GTW
 SG_ EPB_a114_motorSel m114 : 63|1@1+ (1,0) [0|0] "" GTW
 SG_ EPB_a115_current1 m115 : 16|16@1+ (0.017346834,-37.87878788) [0|0] "A" GTW
 SG_ EPB_a115_current2 m115 : 32|16@1+ (0.017346834,-37.87878788) [0|0] "A" GTW
 SG_ EPB_a115_alertID m115 : 48|15@1+ (1,0) [0|0] "" GTW
 SG_ EPB_a115_motorSel m115 : 63|1@1+ (1,0) [0|0] "" GTW
 SG_ EPB_a116_ESP_MIA m116 : 16|1@1+ (1,0) [0|0] "" GTW
 SG_ EPB_a117_brakeHwTypeLearnState m117 : 16|2@1+ (1,0) [0|0] "" GTW
 SG_ EPB_a117_learnedBrakeHwType m117 : 18|2@1+ (1,0) [0|0] "" GTW
 SG_ EPB_a117_tempSelect m117 : 20|2@1+ (1,0) [0|0] "" GTW
 SG_ EPB_a119_DIgear m119 : 16|3@1+ (1,0) [0|0] "" GTW
 SG_ EPB_a119_EPBstate m119 : 19|3@1+ (1,0) [0|0] "" GTW
 SG_ EPB_a119_EPBreqState m119 : 22|3@1+ (1,0) [0|0] "" GTW
 SG_ EPB_a119_wheelSelfParkState_FL m119 : 25|1@1+ (1,0) [0|0] "" GTW
 SG_ EPB_a119_wheelSelfParkState_FR m119 : 26|1@1+ (1,0) [0|0] "" GTW
 SG_ EPB_a119_wheelSelfParkState_RL m119 : 27|1@1+ (1,0) [0|0] "" GTW
 SG_ EPB_a119_wheelSelfParkState_RR m119 : 28|1@1+ (1,0) [0|0] "" GTW
 SG_ EPB_a119_wheelParkState_FL m119 : 29|2@1+ (1,0) [0|0] "" GTW
 SG_ EPB_a119_wheelParkState_FR m119 : 31|2@1+ (1,0) [0|0] "" GTW
 SG_ EPB_a119_wheelParkState_RL m119 : 33|2@1+ (1,0) [0|0] "" GTW
 SG_ EPB_a119_wheelParkState_RR m119 : 35|2@1+ (1,0) [0|0] "" GTW
 SG_ EPB_a120_state m120 : 16|4@1+ (1,0) [0|0] "" GTW
 SG_ EPB_a120_intReqState m120 : 20|4@1+ (1,0) [0|0] "" GTW
 SG_ EPB_a120_voltageCounts m120 : 24|12@1+ (1,0) [0|0] "" GTW
 SG_ EPB_a120_encPosition m120 : 36|12@1+ (1,0) [0|0] "" GTW
 SG_ EPB_a121_state m121 : 16|4@1+ (1,0) [0|0] "" GTW
 SG_ EPB_a121_intReqState m121 : 20|4@1+ (1,0) [0|0] "" GTW
 SG_ EPB_a121_voltageCounts m121 : 24|12@1+ (1,0) [0|0] "" GTW
 SG_ EPB_a121_encPosition m121 : 36|12@1+ (1,0) [0|0] "" GTW
 SG_ EPB_a123_voltageCounts m123 : 16|16@1+ (1,0) [0|0] "" GTW
 SG_ EPB_a123_encPosition m123 : 32|16@1+ (1,0) [0|0] "" GTW
 SG_ EPB_a124_voltageCounts m124 : 16|16@1+ (1,0) [0|0] "" GTW
 SG_ EPB_a124_encPosition m124 : 32|16@1+ (1,0) [0|0] "" GTW
 SG_ EPB_a125_longAFilt m125 : 16|8@1- (0.08,0) [-10.24|10] "m/s^2" GTW
 SG_ EPB_a125_vehicleSpeed m125 : 24|16@1+ (0.1,0) [0|150] "MPH" GTW
 SG_ EPB_a125_slope m125 : 40|2@1+ (1,0) [0|0] "" GTW
 SG_ EPB_a127_setSpeed m127 : 16|10@1+ (0.5,0) [0|511] "kph" GTW
 SG_ EPB_a127_oocConfidence m127 : 32|16@1+ (1,0) [0|65535] "" GTW
 SG_ EPB_a127_oocDistance m127 : 48|16@1+ (1,0) [0|65535] "" GTW
 SG_ EPB_a128_DIgear m128 : 16|3@1+ (1,0) [0|0] "" GTW
 SG_ EPB_a128_EPBstate m128 : 19|3@1+ (1,0) [0|0] "" GTW
 SG_ EPB_a128_EPBreqState m128 : 22|3@1+ (1,0) [0|0] "" GTW
 SG_ EPB_a128_EPBpendingState m128 : 25|3@1+ (1,0) [0|0] "" GTW
 SG_ EPB_a128_EPBsubstateL m128 : 28|3@1+ (1,0) [0|0] "" GTW
 SG_ EPB_a128_EPBsubstateR m128 : 31|3@1+ (1,0) [0|0] "" GTW
 SG_ EPB_a129_diGear m129 : 16|4@1+ (1,0) [0|0] "" GTW
 SG_ EPB_a129_unparkAllowed m129 : 20|1@1+ (1,0) [0|0] "" GTW
 SG_ EPB_a129_internalPendingState m129 : 21|4@1+ (1,0) [0|0] "" GTW
 SG_ EPB_u003_motorSpeed m8195 : 16|16@1+ (0.1,0) [0|150] "MPH" GTW
 SG_ EPB_u003_vehicleSpeed m8195 : 32|16@1+ (0.1,0) [0|150] "MPH" GTW
 SG_ EPB_u011_parkSlopeData m8203 : 16|16@1- (0.08,0) [-10.24|10] "m/s^2" GTW

BO_ 772 EPB_alertMatrix0: 8 EPB
 SG_ EPB_f001_leftEncIntrpt : 0|1@1+ (1,0) [0|0] "" GTW
 SG_ EPB_f002_leftIdleOc : 1|1@1+ (1,0) [0|0] "" GTW
 SG_ EPB_f003_leftEncIrrational : 2|1@1+ (1,0) [0|0] "" GTW
 SG_ EPB_f004_leftEncoderSna : 3|1@1+ (1,0) [0|0] "" GTW
 SG_ EPB_f005_leftOc : 4|1@1+ (1,0) [0|0] "" GTW
 SG_ EPB_f006_leftUc : 5|1@1+ (1,0) [0|0] "" GTW
 SG_ EPB_f007_leftEndStop : 6|1@1+ (1,0) [0|0] "" GTW
 SG_ EPB_f008_leftShortApply : 7|1@1+ (1,0) [0|0] "" GTW
 SG_ EPB_f009_leftNShort : 8|1@1+ (1,0) [0|0] "" GTW
 SG_ EPB_f010_leftPShort : 9|1@1+ (1,0) [0|0] "" GTW
 SG_ EPB_f011_leftNOpen : 10|1@1+ (1,0) [0|0] "" GTW
 SG_ EPB_f012_leftPOpen : 11|1@1+ (1,0) [0|0] "" GTW
 SG_ EPB_f013_leftEnaStuckHigh : 12|1@1+ (1,0) [0|0] "" GTW
 SG_ EPB_f014_leftEnaStuckLow : 13|1@1+ (1,0) [0|0] "" GTW
 SG_ EPB_f015_leftDriveDuration : 14|1@1+ (1,0) [0|0] "" GTW
 SG_ EPB_f016_leftPHalfBridge : 15|1@1+ (1,0) [0|0] "" GTW
 SG_ EPB_f017_leftNHalfBridge : 16|1@1+ (1,0) [0|0] "" GTW
 SG_ EPB_f018_leftNvOv : 17|1@1+ (1,0) [0|0] "" GTW
 SG_ EPB_f019_leftNvUv : 18|1@1+ (1,0) [0|0] "" GTW
 SG_ EPB_f020_leftPvOv : 19|1@1+ (1,0) [0|0] "" GTW
 SG_ EPB_f021_leftPvUv : 20|1@1+ (1,0) [0|0] "" GTW
 SG_ EPB_f022_leftSubstateErr : 21|1@1+ (1,0) [0|0] "" GTW
 SG_ EPB_f023_leftFirstShortApply : 22|1@1+ (1,0) [0|0] "" GTW
 SG_ EPB_f024_motorShortedReleaseL : 23|1@1+ (1,0) [0|0] "" GTW
 SG_ EPB_f025_motorShortedApplyL : 24|1@1+ (1,0) [0|0] "" GTW
 SG_ EPB_f026_noCurrentCalL : 25|1@1+ (1,0) [0|0] "" GTW
 SG_ EPB_f027_spuriousEncIntL : 26|1@1+ (1,0) [0|0] "" GTW
 SG_ EPB_f028_reqStateErr : 27|1@1+ (1,0) [0|0] "" GTW
 SG_ EPB_f029_stateErr : 28|1@1+ (1,0) [0|0] "" GTW
 SG_ EPB_f030_interProcSpi : 29|1@1+ (1,0) [0|0] "" GTW
 SG_ EPB_f031_chgMIA : 30|1@1+ (1,0) [0|0] "" GTW
 SG_ EPB_f032_canDisabled : 31|1@1+ (1,0) [0|0] "" GTW
 SG_ EPB_f033_canHardware : 32|1@1+ (1,0) [0|0] "" GTW
 SG_ EPB_f034_canData : 33|1@1+ (1,0) [0|0] "" GTW
 SG_ EPB_f035_canErr : 34|1@1+ (1,0) [0|0] "" GTW
 SG_ EPB_f036_canOverrun : 35|1@1+ (1,0) [0|0] "" GTW
 SG_ EPB_f037_firmware : 36|1@1+ (1,0) [0|0] "" GTW
 SG_ EPB_f038_eeprom : 37|1@1+ (1,0) [0|0] "" GTW
 SG_ EPB_f039_watchdogReset : 38|1@1+ (1,0) [0|0] "" GTW
 SG_ EPB_f040_memoryError : 39|1@1+ (1,0) [0|0] "" GTW
 SG_ EPB_f041_spiOpen : 40|1@1+ (1,0) [0|0] "" GTW
 SG_ EPB_f042_spiRead : 41|1@1+ (1,0) [0|0] "" GTW
 SG_ EPB_f043_absMIA : 42|1@1+ (1,0) [0|0] "" GTW
 SG_ EPB_f044_diMIA : 43|1@1+ (1,0) [0|0] "" GTW
 SG_ EPB_f045_gtwMIA : 44|1@1+ (1,0) [0|0] "" GTW
 SG_ EPB_f046_sccmMIA : 45|1@1+ (1,0) [0|0] "" GTW
 SG_ EPB_f047_epbmMIA : 46|1@1+ (1,0) [0|0] "" GTW
 SG_ EPB_f048_mcuMIA : 47|1@1+ (1,0) [0|0] "" GTW
 SG_ EPB_f049_espMIA : 48|1@1+ (1,0) [0|0] "" GTW
 SG_ EPB_f050_resetRequired : 49|1@1+ (1,0) [0|0] "" GTW
 SG_ EPB_f051_epbNotApplied : 50|1@1+ (1,0) [0|0] "" GTW
 SG_ EPB_f052_epbProblem : 51|1@1+ (1,0) [0|0] "" GTW
 SG_ EPB_f053_epbNotReleased : 52|1@1+ (1,0) [0|0] "" GTW
 SG_ EPB_f054_severeShortApply : 53|1@1+ (1,0) [0|0] "" GTW
 SG_ EPB_f055_stackOverflow : 54|1@1+ (1,0) [0|0] "" GTW
 SG_ EPB_f056_12vOv : 55|1@1+ (1,0) [0|0] "" GTW
 SG_ EPB_f057_12vUv : 56|1@1+ (1,0) [0|0] "" GTW
 SG_ EPB_f058_5vLost : 57|1@1+ (1,0) [0|0] "" GTW
 SG_ EPB_f059_battMismatch : 58|1@1+ (1,0) [0|0] "" GTW
 SG_ EPB_f060_maxCycles1 : 59|1@1+ (1,0) [0|0] "" GTW
 SG_ EPB_f061_maxCycles2 : 60|1@1+ (1,0) [0|0] "" GTW
 SG_ EPB_f062_diGearInvld : 61|1@1+ (1,0) [0|0] "" GTW
 SG_ EPB_f063_parkWhlSpeed : 62|1@1+ (1,0) [0|0] "" GTW
 SG_ EPB_f064_EPBMTimeout : 63|1@1+ (1,0) [0|0] "" GTW

BO_ 820 EPB_alertMatrix1: 8 EPB
 SG_ EPB_f065_rightEncIntrpt : 0|1@1+ (1,0) [0|0] "" GTW
 SG_ EPB_f066_rightIdleOc : 1|1@1+ (1,0) [0|0] "" GTW
 SG_ EPB_f067_rightEncIrrational : 2|1@1+ (1,0) [0|0] "" GTW
 SG_ EPB_f068_rightEncoderSna : 3|1@1+ (1,0) [0|0] "" GTW
 SG_ EPB_f069_rightOc : 4|1@1+ (1,0) [0|0] "" GTW
 SG_ EPB_f070_rightUc : 5|1@1+ (1,0) [0|0] "" GTW
 SG_ EPB_f071_rightEndStop : 6|1@1+ (1,0) [0|0] "" GTW
 SG_ EPB_f072_rightShortApply : 7|1@1+ (1,0) [0|0] "" GTW
 SG_ EPB_f073_rightNShort : 8|1@1+ (1,0) [0|0] "" GTW
 SG_ EPB_f074_rightPShort : 9|1@1+ (1,0) [0|0] "" GTW
 SG_ EPB_f075_rightNOpen : 10|1@1+ (1,0) [0|0] "" GTW
 SG_ EPB_f076_rightPOpen : 11|1@1+ (1,0) [0|0] "" GTW
 SG_ EPB_f077_rightEnaStuckHigh : 12|1@1+ (1,0) [0|0] "" GTW
 SG_ EPB_f078_rightEnaStuckLow : 13|1@1+ (1,0) [0|0] "" GTW
 SG_ EPB_f079_rightDriveDuration : 14|1@1+ (1,0) [0|0] "" GTW
 SG_ EPB_f080_rightPHalfBridge : 15|1@1+ (1,0) [0|0] "" GTW
 SG_ EPB_f081_rightNHalfBridge : 16|1@1+ (1,0) [0|0] "" GTW
 SG_ EPB_f082_rightNvOv : 17|1@1+ (1,0) [0|0] "" GTW
 SG_ EPB_f083_rightNvUv : 18|1@1+ (1,0) [0|0] "" GTW
 SG_ EPB_f084_rightPvOv : 19|1@1+ (1,0) [0|0] "" GTW
 SG_ EPB_f085_rightPvUv : 20|1@1+ (1,0) [0|0] "" GTW
 SG_ EPB_f086_rightSubstateErr : 21|1@1+ (1,0) [0|0] "" GTW
 SG_ EPB_f087_rightFirstShortApply : 22|1@1+ (1,0) [0|0] "" GTW
 SG_ EPB_f088_motorShortedReleaseR : 23|1@1+ (1,0) [0|0] "" GTW
 SG_ EPB_f089_motorShortedApplyR : 24|1@1+ (1,0) [0|0] "" GTW
 SG_ EPB_f090_noCurrentCalR : 25|1@1+ (1,0) [0|0] "" GTW
 SG_ EPB_f091_spuriousEncIntR : 26|1@1+ (1,0) [0|0] "" GTW
 SG_ EPB_f092_obsolete : 27|1@1+ (1,0) [0|0] "" GTW
 SG_ EPB_f093_dasMIA : 28|1@1+ (1,0) [0|0] "" GTW
 SG_ EPB_f094_inhibitEac : 29|1@1+ (1,0) [0|0] "" GTW
 SG_ EPB_f095_invalidConfig : 30|1@1+ (1,0) [0|0] "" GTW
 SG_ EPB_f096_epasMia : 31|1@1+ (1,0) [0|0] "" GTW
 SG_ EPB_f097_selfParkAborted : 32|1@1+ (1,0) [0|0] "" GTW
 SG_ EPB_f098_parkMia : 33|1@1+ (1,0) [0|0] "" GTW
 SG_ EPB_f099_pmMia : 34|1@1+ (1,0) [0|0] "" GTW
 SG_ EPB_f100_calibrationWarning : 35|1@1+ (1,0) [0|0] "" GTW
 SG_ EPB_f101_calibrationFault : 36|1@1+ (1,0) [0|0] "" GTW
 SG_ EPB_f102_eepromCorrupt : 37|1@1+ (1,0) [0|0] "" GTW
 SG_ EPB_f103_eepromUpdated : 38|1@1+ (1,0) [0|0] "" GTW
 SG_ EPB_f104_epbmStillAsleep : 39|1@1+ (1,0) [0|0] "" GTW
 SG_ EPB_f105_epbmWentToSleep : 40|1@1+ (1,0) [0|0] "" GTW
 SG_ EPB_f106_leftNVoltageLow : 41|1@1+ (1,0) [0|0] "" GTW
 SG_ EPB_f107_leftPVoltageHigh : 42|1@1+ (1,0) [0|0] "" GTW
 SG_ EPB_f108_rightNVoltageLow : 43|1@1+ (1,0) [0|0] "" GTW
 SG_ EPB_f109_rightPVoltageHigh : 44|1@1+ (1,0) [0|0] "" GTW
 SG_ EPB_f110_calWarningLeft : 45|1@1+ (1,0) [0|0] "" GTW
 SG_ EPB_f111_calWarningRight : 46|1@1+ (1,0) [0|0] "" GTW
 SG_ EPB_f112_calFaultLeft : 47|1@1+ (1,0) [0|0] "" GTW
 SG_ EPB_f113_calFaultRight : 48|1@1+ (1,0) [0|0] "" GTW
 SG_ EPB_f114_voltageWarning : 49|1@1+ (1,0) [0|0] "" GTW
 SG_ EPB_f115_currentWarning : 50|1@1+ (1,0) [0|0] "" GTW
 SG_ EPB_f116_unableToCalcGrade : 51|1@1+ (1,0) [0|0] "" GTW
 SG_ EPB_f117_usedFallbackValues : 52|1@1+ (1,0) [0|0] "" GTW
 SG_ EPB_f118_freeRollingModeActive : 53|1@1+ (1,0) [0|0] "" GTW
 SG_ EPB_f119_freeRollingModeAborted : 54|1@1+ (1,0) [0|0] "" GTW
 SG_ EPB_f120_releaseLogL : 55|1@1+ (1,0) [0|0] "" GTW
 SG_ EPB_f121_releaseLogR : 56|1@1+ (1,0) [0|0] "" GTW
 SG_ EPB_f122_freeRollMdEpbmMismatch : 57|1@1+ (1,0) [0|0] "" GTW
 SG_ EPB_f123_releaseDistanceL : 58|1@1+ (1,0) [0|0] "" GTW
 SG_ EPB_f124_releaseDistanceR : 59|1@1+ (1,0) [0|0] "" GTW
 SG_ EPB_f125_gradeTooSteep : 60|1@1+ (1,0) [0|0] "" GTW
 SG_ EPB_f126_ShortApplyUF : 61|1@1+ (1,0) [0|0] "" GTW
 SG_ EPB_f127_oocSpeedViolation : 62|1@1+ (1,0) [0|0] "" GTW
 SG_ EPB_f128_followedDiToPark : 63|1@1+ (1,0) [0|0] "" GTW

BO_ 788 EPB_alertMatrix2: 8 EPB
 SG_ EPB_w001_leftEncIntrpt : 0|1@1+ (1,0) [0|0] "" GTW
 SG_ EPB_w002_leftIdleOc : 1|1@1+ (1,0) [0|0] "" GTW
 SG_ EPB_w003_leftEncIrrational : 2|1@1+ (1,0) [0|0] "" GTW
 SG_ EPB_w004_leftEncoderSna : 3|1@1+ (1,0) [0|0] "" GTW
 SG_ EPB_w005_leftOc : 4|1@1+ (1,0) [0|0] "" GTW
 SG_ EPB_w006_leftUc : 5|1@1+ (1,0) [0|0] "" GTW
 SG_ EPB_w007_leftEndStop : 6|1@1+ (1,0) [0|0] "" GTW
 SG_ EPB_w008_leftShortApply : 7|1@1+ (1,0) [0|0] "" GTW
 SG_ EPB_w009_leftNShort : 8|1@1+ (1,0) [0|0] "" GTW
 SG_ EPB_w010_leftPShort : 9|1@1+ (1,0) [0|0] "" GTW
 SG_ EPB_w011_leftNOpen : 10|1@1+ (1,0) [0|0] "" GTW
 SG_ EPB_w012_leftPOpen : 11|1@1+ (1,0) [0|0] "" GTW
 SG_ EPB_w013_leftEnaStuckHigh : 12|1@1+ (1,0) [0|0] "" GTW
 SG_ EPB_w014_leftEnaStuckLow : 13|1@1+ (1,0) [0|0] "" GTW
 SG_ EPB_w015_leftDriveDuration : 14|1@1+ (1,0) [0|0] "" GTW
 SG_ EPB_w016_leftPHalfBridge : 15|1@1+ (1,0) [0|0] "" GTW
 SG_ EPB_w017_leftNHalfBridge : 16|1@1+ (1,0) [0|0] "" GTW
 SG_ EPB_w018_leftNvOv : 17|1@1+ (1,0) [0|0] "" GTW
 SG_ EPB_w019_leftNvUv : 18|1@1+ (1,0) [0|0] "" GTW
 SG_ EPB_w020_leftPvOv : 19|1@1+ (1,0) [0|0] "" GTW
 SG_ EPB_w021_leftPvUv : 20|1@1+ (1,0) [0|0] "" GTW
 SG_ EPB_w022_leftSubstateErr : 21|1@1+ (1,0) [0|0] "" GTW
 SG_ EPB_w023_leftFirstShortApply : 22|1@1+ (1,0) [0|0] "" GTW
 SG_ EPB_w024_motorShortedReleaseL : 23|1@1+ (1,0) [0|0] "" GTW
 SG_ EPB_w025_motorShortedApplyL : 24|1@1+ (1,0) [0|0] "" GTW
 SG_ EPB_w026_noCurrentCalL : 25|1@1+ (1,0) [0|0] "" GTW
 SG_ EPB_w027_spuriousEncIntL : 26|1@1+ (1,0) [0|0] "" GTW
 SG_ EPB_w028_reqStateErr : 27|1@1+ (1,0) [0|0] "" GTW
 SG_ EPB_w029_stateErr : 28|1@1+ (1,0) [0|0] "" GTW
 SG_ EPB_w030_interProcSpi : 29|1@1+ (1,0) [0|0] "" GTW
 SG_ EPB_w031_chgMIA : 30|1@1+ (1,0) [0|0] "" GTW
 SG_ EPB_w032_canDisabled : 31|1@1+ (1,0) [0|0] "" GTW
 SG_ EPB_w033_canHardware : 32|1@1+ (1,0) [0|0] "" GTW
 SG_ EPB_w034_canData : 33|1@1+ (1,0) [0|0] "" GTW
 SG_ EPB_w035_canErr : 34|1@1+ (1,0) [0|0] "" GTW
 SG_ EPB_w036_canOverrun : 35|1@1+ (1,0) [0|0] "" GTW
 SG_ EPB_w037_firmware : 36|1@1+ (1,0) [0|0] "" GTW
 SG_ EPB_w038_eeprom : 37|1@1+ (1,0) [0|0] "" GTW
 SG_ EPB_w039_watchdogReset : 38|1@1+ (1,0) [0|0] "" GTW
 SG_ EPB_w040_memoryError : 39|1@1+ (1,0) [0|0] "" GTW
 SG_ EPB_w041_spiOpen : 40|1@1+ (1,0) [0|0] "" GTW
 SG_ EPB_w042_spiRead : 41|1@1+ (1,0) [0|0] "" GTW
 SG_ EPB_w043_absMIA : 42|1@1+ (1,0) [0|0] "" GTW
 SG_ EPB_w044_diMIA : 43|1@1+ (1,0) [0|0] "" GTW
 SG_ EPB_w045_gtwMIA : 44|1@1+ (1,0) [0|0] "" GTW
 SG_ EPB_w046_sccmMIA : 45|1@1+ (1,0) [0|0] "" GTW
 SG_ EPB_w047_epbmMIA : 46|1@1+ (1,0) [0|0] "" GTW
 SG_ EPB_w048_mcuMIA : 47|1@1+ (1,0) [0|0] "" GTW
 SG_ EPB_w049_espMIA : 48|1@1+ (1,0) [0|0] "" GTW
 SG_ EPB_w050_resetRequired : 49|1@1+ (1,0) [0|0] "" GTW
 SG_ EPB_w051_epbNotApplied : 50|1@1+ (1,0) [0|0] "" GTW
 SG_ EPB_w052_epbProblem : 51|1@1+ (1,0) [0|0] "" GTW
 SG_ EPB_w053_epbNotReleased : 52|1@1+ (1,0) [0|0] "" GTW
 SG_ EPB_w054_severeShortApply : 53|1@1+ (1,0) [0|0] "" GTW
 SG_ EPB_w055_stackOverflow : 54|1@1+ (1,0) [0|0] "" GTW
 SG_ EPB_w056_12vOv : 55|1@1+ (1,0) [0|0] "" GTW
 SG_ EPB_w057_12vUv : 56|1@1+ (1,0) [0|0] "" GTW
 SG_ EPB_w058_5vLost : 57|1@1+ (1,0) [0|0] "" GTW
 SG_ EPB_w059_battMismatch : 58|1@1+ (1,0) [0|0] "" GTW
 SG_ EPB_w060_maxCycles1 : 59|1@1+ (1,0) [0|0] "" GTW
 SG_ EPB_w061_maxCycles2 : 60|1@1+ (1,0) [0|0] "" GTW
 SG_ EPB_w062_diGearInvld : 61|1@1+ (1,0) [0|0] "" GTW
 SG_ EPB_w063_parkWhlSpeed : 62|1@1+ (1,0) [0|0] "" GTW
 SG_ EPB_w064_EPBMTimeout : 63|1@1+ (1,0) [0|0] "" GTW

BO_ 804 EPB_alertMatrix3: 8 EPB
 SG_ EPB_w065_rightEncIntrpt : 0|1@1+ (1,0) [0|0] "" GTW
 SG_ EPB_w066_rightIdleOc : 1|1@1+ (1,0) [0|0] "" GTW
 SG_ EPB_w067_rightEncIrrational : 2|1@1+ (1,0) [0|0] "" GTW
 SG_ EPB_w068_rightEncoderSna : 3|1@1+ (1,0) [0|0] "" GTW
 SG_ EPB_w069_rightOc : 4|1@1+ (1,0) [0|0] "" GTW
 SG_ EPB_w070_rightUc : 5|1@1+ (1,0) [0|0] "" GTW
 SG_ EPB_w071_rightEndStop : 6|1@1+ (1,0) [0|0] "" GTW
 SG_ EPB_w072_rightShortApply : 7|1@1+ (1,0) [0|0] "" GTW
 SG_ EPB_w073_rightNShort : 8|1@1+ (1,0) [0|0] "" GTW
 SG_ EPB_w074_rightPShort : 9|1@1+ (1,0) [0|0] "" GTW
 SG_ EPB_w075_rightNOpen : 10|1@1+ (1,0) [0|0] "" GTW
 SG_ EPB_w076_rightPOpen : 11|1@1+ (1,0) [0|0] "" GTW
 SG_ EPB_w077_rightEnaStuckHigh : 12|1@1+ (1,0) [0|0] "" GTW
 SG_ EPB_w078_rightEnaStuckLow : 13|1@1+ (1,0) [0|0] "" GTW
 SG_ EPB_w079_rightDriveDuration : 14|1@1+ (1,0) [0|0] "" GTW
 SG_ EPB_w080_rightPHalfBridge : 15|1@1+ (1,0) [0|0] "" GTW
 SG_ EPB_w081_rightNHalfBridge : 16|1@1+ (1,0) [0|0] "" GTW
 SG_ EPB_w082_rightNvOv : 17|1@1+ (1,0) [0|0] "" GTW
 SG_ EPB_w083_rightNvUv : 18|1@1+ (1,0) [0|0] "" GTW
 SG_ EPB_w084_rightPvOv : 19|1@1+ (1,0) [0|0] "" GTW
 SG_ EPB_w085_rightPvUv : 20|1@1+ (1,0) [0|0] "" GTW
 SG_ EPB_w086_rightSubstateErr : 21|1@1+ (1,0) [0|0] "" GTW
 SG_ EPB_w087_rightFirstShortApply : 22|1@1+ (1,0) [0|0] "" GTW
 SG_ EPB_w088_motorShortedReleaseR : 23|1@1+ (1,0) [0|0] "" GTW
 SG_ EPB_w089_motorShortedApplyR : 24|1@1+ (1,0) [0|0] "" GTW
 SG_ EPB_w090_noCurrentCalR : 25|1@1+ (1,0) [0|0] "" GTW
 SG_ EPB_w091_spuriousEncIntR : 26|1@1+ (1,0) [0|0] "" GTW
 SG_ EPB_w092_obsolete : 27|1@1+ (1,0) [0|0] "" GTW
 SG_ EPB_w093_dasMIA : 28|1@1+ (1,0) [0|0] "" GTW
 SG_ EPB_w094_inhibitEac : 29|1@1+ (1,0) [0|0] "" GTW
 SG_ EPB_w095_invalidConfig : 30|1@1+ (1,0) [0|0] "" GTW
 SG_ EPB_w096_epasMia : 31|1@1+ (1,0) [0|0] "" GTW
 SG_ EPB_w097_selfParkAborted : 32|1@1+ (1,0) [0|0] "" GTW
 SG_ EPB_w098_parkMia : 33|1@1+ (1,0) [0|0] "" GTW
 SG_ EPB_w099_pmMia : 34|1@1+ (1,0) [0|0] "" GTW
 SG_ EPB_w100_calibrationWarning : 35|1@1+ (1,0) [0|0] "" GTW
 SG_ EPB_w101_calibrationFault : 36|1@1+ (1,0) [0|0] "" GTW
 SG_ EPB_w102_eepromCorrupt : 37|1@1+ (1,0) [0|0] "" GTW
 SG_ EPB_w103_eepromUpdated : 38|1@1+ (1,0) [0|0] "" GTW
 SG_ EPB_w104_epbmStillAsleep : 39|1@1+ (1,0) [0|0] "" GTW
 SG_ EPB_w105_epbmWentToSleep : 40|1@1+ (1,0) [0|0] "" GTW
 SG_ EPB_w106_leftNVoltageLow : 41|1@1+ (1,0) [0|0] "" GTW
 SG_ EPB_w107_leftPVoltageHigh : 42|1@1+ (1,0) [0|0] "" GTW
 SG_ EPB_w108_rightNVoltageLow : 43|1@1+ (1,0) [0|0] "" GTW
 SG_ EPB_w109_rightPVoltageHigh : 44|1@1+ (1,0) [0|0] "" GTW
 SG_ EPB_w110_calWarningLeft : 45|1@1+ (1,0) [0|0] "" GTW
 SG_ EPB_w111_calWarningRight : 46|1@1+ (1,0) [0|0] "" GTW
 SG_ EPB_w112_calFaultLeft : 47|1@1+ (1,0) [0|0] "" GTW
 SG_ EPB_w113_calFaultRight : 48|1@1+ (1,0) [0|0] "" GTW
 SG_ EPB_w114_voltageWarning : 49|1@1+ (1,0) [0|0] "" GTW
 SG_ EPB_w115_currentWarning : 50|1@1+ (1,0) [0|0] "" GTW
 SG_ EPB_w116_unableToCalcGrade : 51|1@1+ (1,0) [0|0] "" GTW
 SG_ EPB_w117_usedFallbackValues : 52|1@1+ (1,0) [0|0] "" GTW
 SG_ EPB_w118_freeRollingModeActive : 53|1@1+ (1,0) [0|0] "" GTW
 SG_ EPB_w119_freeRollingModeAborted : 54|1@1+ (1,0) [0|0] "" GTW
 SG_ EPB_w120_releaseLogL : 55|1@1+ (1,0) [0|0] "" GTW
 SG_ EPB_w121_releaseLogR : 56|1@1+ (1,0) [0|0] "" GTW
 SG_ EPB_w122_freeRollMdEpbmMismatch : 57|1@1+ (1,0) [0|0] "" GTW
 SG_ EPB_w123_releaseDistanceL : 58|1@1+ (1,0) [0|0] "" GTW
 SG_ EPB_w124_releaseDistanceR : 59|1@1+ (1,0) [0|0] "" GTW
 SG_ EPB_w125_gradeTooSteep : 60|1@1+ (1,0) [0|0] "" GTW
 SG_ EPB_w126_ShortApplyUF : 61|1@1+ (1,0) [0|0] "" GTW
 SG_ EPB_w127_oocSpeedViolation : 62|1@1+ (1,0) [0|0] "" GTW
 SG_ EPB_w128_followedDiToPark : 63|1@1+ (1,0) [0|0] "" GTW

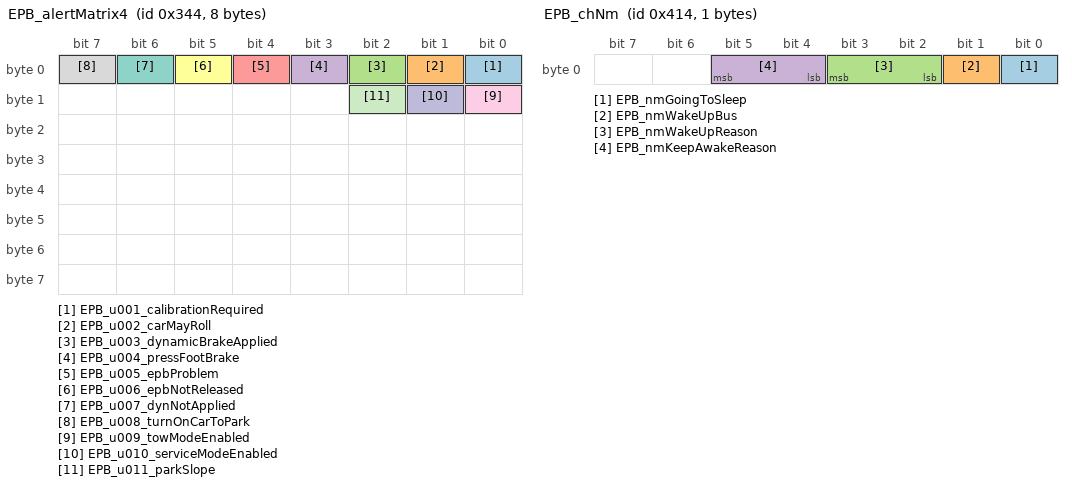
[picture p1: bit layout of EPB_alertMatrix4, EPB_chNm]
BO_ 836 EPB_alertMatrix4: 8 EPB
 SG_ EPB_u001_calibrationRequired : 0|1@1+ (1,0) [0|0] "" GTW
 SG_ EPB_u002_carMayRoll : 1|1@1+ (1,0) [0|0] "" GTW
 SG_ EPB_u003_dynamicBrakeApplied : 2|1@1+ (1,0) [0|0] "" GTW
 SG_ EPB_u004_pressFootBrake : 3|1@1+ (1,0) [0|0] "" GTW
 SG_ EPB_u005_epbProblem : 4|1@1+ (1,0) [0|0] "" GTW
 SG_ EPB_u006_epbNotReleased : 5|1@1+ (1,0) [0|0] "" GTW
 SG_ EPB_u007_dynNotApplied : 6|1@1+ (1,0) [0|0] "" GTW
 SG_ EPB_u008_turnOnCarToPark : 7|1@1+ (1,0) [0|0] "" GTW
 SG_ EPB_u009_towModeEnabled : 8|1@1+ (1,0) [0|0] "" GTW
 SG_ EPB_u010_serviceModeEnabled : 9|1@1+ (1,0) [0|0] "" GTW
 SG_ EPB_u011_parkSlope : 10|1@1+ (1,0) [0|0] "" GTW

BO_ 852 EPB_alertMatrix5: 8 EPB
 SG_ EPB_w129_unparkNotAllowed : 0|1@1+ (1,0) [0|0] "" GTW
 SG_ EPB_w130_unused : 1|1@1+ (1,0) [0|0] "" GTW
 SG_ EPB_w131_unused : 2|1@1+ (1,0) [0|0] "" GTW
 SG_ EPB_w132_unused : 3|1@1+ (1,0) [0|0] "" GTW
 SG_ EPB_w133_unused : 4|1@1+ (1,0) [0|0] "" GTW
 SG_ EPB_w134_unused : 5|1@1+ (1,0) [0|0] "" GTW
 SG_ EPB_w135_unused : 6|1@1+ (1,0) [0|0] "" GTW
 SG_ EPB_w136_unused : 7|1@1+ (1,0) [0|0] "" GTW
 SG_ EPB_w137_unused : 8|1@1+ (1,0) [0|0] "" GTW
 SG_ EPB_w138_unused : 9|1@1+ (1,0) [0|0] "" GTW
 SG_ EPB_w139_unused : 10|1@1+ (1,0) [0|0] "" GTW
 SG_ EPB_w140_unused : 11|1@1+ (1,0) [0|0] "" GTW
 SG_ EPB_w141_unused : 12|1@1+ (1,0) [0|0] "" GTW
 SG_ EPB_w142_unused : 13|1@1+ (1,0) [0|0] "" GTW
 SG_ EPB_w143_unused : 14|1@1+ (1,0) [0|0] "" GTW
 SG_ EPB_w144_unused : 15|1@1+ (1,0) [0|0] "" GTW
 SG_ EPB_w145_unused : 16|1@1+ (1,0) [0|0] "" GTW
 SG_ EPB_w146_unused : 17|1@1+ (1,0) [0|0] "" GTW
 SG_ EPB_w147_unused : 18|1@1+ (1,0) [0|0] "" GTW
 SG_ EPB_w148_unused : 19|1@1+ (1,0) [0|0] "" GTW
 SG_ EPB_w149_unused : 20|1@1+ (1,0) [0|0] "" GTW
 SG_ EPB_w150_unused : 21|1@1+ (1,0) [0|0] "" GTW
 SG_ EPB_w151_unused : 22|1@1+ (1,0) [0|0] "" GTW
 SG_ EPB_w152_unused : 23|1@1+ (1,0) [0|0] "" GTW
 SG_ EPB_w153_unused : 24|1@1+ (1,0) [0|0] "" GTW
 SG_ EPB_w154_unused : 25|1@1+ (1,0) [0|0] "" GTW
 SG_ EPB_w155_unused : 26|1@1+ (1,0) [0|0] "" GTW
 SG_ EPB_w156_unused : 27|1@1+ (1,0) [0|0] "" GTW
 SG_ EPB_w157_unused : 28|1@1+ (1,0) [0|0] "" GTW
 SG_ EPB_w158_unused : 29|1@1+ (1,0) [0|0] "" GTW
 SG_ EPB_w159_unused : 30|1@1+ (1,0) [0|0] "" GTW
 SG_ EPB_w160_unused : 31|1@1+ (1,0) [0|0] "" GTW
 SG_ EPB_w161_unused : 32|1@1+ (1,0) [0|0] "" GTW
 SG_ EPB_w162_unused : 33|1@1+ (1,0) [0|0] "" GTW
 SG_ EPB_w163_unused : 34|1@1+ (1,0) [0|0] "" GTW
 SG_ EPB_w164_unused : 35|1@1+ (1,0) [0|0] "" GTW
 SG_ EPB_w165_unused : 36|1@1+ (1,0) [0|0] "" GTW
 SG_ EPB_w166_unused : 37|1@1+ (1,0) [0|0] "" GTW
 SG_ EPB_w167_unused : 38|1@1+ (1,0) [0|0] "" GTW
 SG_ EPB_w168_unused : 39|1@1+ (1,0) [0|0] "" GTW
 SG_ EPB_w169_unused : 40|1@1+ (1,0) [0|0] "" GTW
 SG_ EPB_w170_unused : 41|1@1+ (1,0) [0|0] "" GTW
 SG_ EPB_w171_unused : 42|1@1+ (1,0) [0|0] "" GTW
 SG_ EPB_w172_unused : 43|1@1+ (1,0) [0|0] "" GTW
 SG_ EPB_w173_unused : 44|1@1+ (1,0) [0|0] "" GTW
 SG_ EPB_w174_unused : 45|1@1+ (1,0) [0|0] "" GTW
 SG_ EPB_w175_unused : 46|1@1+ (1,0) [0|0] "" GTW
 SG_ EPB_w176_unused : 47|1@1+ (1,0) [0|0] "" GTW
 SG_ EPB_w177_unused : 48|1@1+ (1,0) [0|0] "" GTW
 SG_ EPB_w178_unused : 49|1@1+ (1,0) [0|0] "" GTW
 SG_ EPB_w179_unused : 50|1@1+ (1,0) [0|0] "" GTW
 SG_ EPB_w180_unused : 51|1@1+ (1,0) [0|0] "" GTW
 SG_ EPB_w181_unused : 52|1@1+ (1,0) [0|0] "" GTW
 SG_ EPB_w182_unused : 53|1@1+ (1,0) [0|0] "" GTW
 SG_ EPB_w183_unused : 54|1@1+ (1,0) [0|0] "" GTW
 SG_ EPB_w184_unused : 55|1@1+ (1,0) [0|0] "" GTW
 SG_ EPB_w185_unused : 56|1@1+ (1,0) [0|0] "" GTW
 SG_ EPB_w186_unused : 57|1@1+ (1,0) [0|0] "" GTW
 SG_ EPB_w187_unused : 58|1@1+ (1,0) [0|0] "" GTW
 SG_ EPB_w188_unused : 59|1@1+ (1,0) [0|0] "" GTW
 SG_ EPB_w189_unused : 60|1@1+ (1,0) [0|0] "" GTW
 SG_ EPB_w190_unused : 61|1@1+ (1,0) [0|0] "" GTW
 SG_ EPB_w191_unused : 62|1@1+ (1,0) [0|0] "" GTW
 SG_ EPB_w192_unused : 63|1@1+ (1,0) [0|0] "" GTW

BO_ 884 EPB_alertMatrix6: 8 EPB
 SG_ EPB_f129_unparkNotAllowed : 0|1@1+ (1,0) [0|0] "" GTW
 SG_ EPB_f130_unused : 1|1@1+ (1,0) [0|0] "" GTW
 SG_ EPB_f131_unused : 2|1@1+ (1,0) [0|0] "" GTW
 SG_ EPB_f132_unused : 3|1@1+ (1,0) [0|0] "" GTW
 SG_ EPB_f133_unused : 4|1@1+ (1,0) [0|0] "" GTW
 SG_ EPB_f134_unused : 5|1@1+ (1,0) [0|0] "" GTW
 SG_ EPB_f135_unused : 6|1@1+ (1,0) [0|0] "" GTW
 SG_ EPB_f136_unused : 7|1@1+ (1,0) [0|0] "" GTW
 SG_ EPB_f137_unused : 8|1@1+ (1,0) [0|0] "" GTW
 SG_ EPB_f138_unused : 9|1@1+ (1,0) [0|0] "" GTW
 SG_ EPB_f139_unused : 10|1@1+ (1,0) [0|0] "" GTW
 SG_ EPB_f140_unused : 11|1@1+ (1,0) [0|0] "" GTW
 SG_ EPB_f141_unused : 12|1@1+ (1,0) [0|0] "" GTW
 SG_ EPB_f142_unused : 13|1@1+ (1,0) [0|0] "" GTW
 SG_ EPB_f143_unused : 14|1@1+ (1,0) [0|0] "" GTW
 SG_ EPB_f144_unused : 15|1@1+ (1,0) [0|0] "" GTW
 SG_ EPB_f145_unused : 16|1@1+ (1,0) [0|0] "" GTW
 SG_ EPB_f146_unused : 17|1@1+ (1,0) [0|0] "" GTW
 SG_ EPB_f147_unused : 18|1@1+ (1,0) [0|0] "" GTW
 SG_ EPB_f148_unused : 19|1@1+ (1,0) [0|0] "" GTW
 SG_ EPB_f149_unused : 20|1@1+ (1,0) [0|0] "" GTW
 SG_ EPB_f150_unused : 21|1@1+ (1,0) [0|0] "" GTW
 SG_ EPB_f151_unused : 22|1@1+ (1,0) [0|0] "" GTW
 SG_ EPB_f152_unused : 23|1@1+ (1,0) [0|0] "" GTW
 SG_ EPB_f153_unused : 24|1@1+ (1,0) [0|0] "" GTW
 SG_ EPB_f154_unused : 25|1@1+ (1,0) [0|0] "" GTW
 SG_ EPB_f155_unused : 26|1@1+ (1,0) [0|0] "" GTW
 SG_ EPB_f156_unused : 27|1@1+ (1,0) [0|0] "" GTW
 SG_ EPB_f157_unused : 28|1@1+ (1,0) [0|0] "" GTW
 SG_ EPB_f158_unused : 29|1@1+ (1,0) [0|0] "" GTW
 SG_ EPB_f159_unused : 30|1@1+ (1,0) [0|0] "" GTW
 SG_ EPB_f160_unused : 31|1@1+ (1,0) [0|0] "" GTW
 SG_ EPB_f161_unused : 32|1@1+ (1,0) [0|0] "" GTW
 SG_ EPB_f162_unused : 33|1@1+ (1,0) [0|0] "" GTW
 SG_ EPB_f163_unused : 34|1@1+ (1,0) [0|0] "" GTW
 SG_ EPB_f164_unused : 35|1@1+ (1,0) [0|0] "" GTW
 SG_ EPB_f165_unused : 36|1@1+ (1,0) [0|0] "" GTW
 SG_ EPB_f166_unused : 37|1@1+ (1,0) [0|0] "" GTW
 SG_ EPB_f167_unused : 38|1@1+ (1,0) [0|0] "" GTW
 SG_ EPB_f168_unused : 39|1@1+ (1,0) [0|0] "" GTW
 SG_ EPB_f169_unused : 40|1@1+ (1,0) [0|0] "" GTW
 SG_ EPB_f170_unused : 41|1@1+ (1,0) [0|0] "" GTW
 SG_ EPB_f171_unused : 42|1@1+ (1,0) [0|0] "" GTW
 SG_ EPB_f172_unused : 43|1@1+ (1,0) [0|0] "" GTW
 SG_ EPB_f173_unused : 44|1@1+ (1,0) [0|0] "" GTW
 SG_ EPB_f174_unused : 45|1@1+ (1,0) [0|0] "" GTW
 SG_ EPB_f175_unused : 46|1@1+ (1,0) [0|0] "" GTW
 SG_ EPB_f176_unused : 47|1@1+ (1,0) [0|0] "" GTW
 SG_ EPB_f177_unused : 48|1@1+ (1,0) [0|0] "" GTW
 SG_ EPB_f178_unused : 49|1@1+ (1,0) [0|0] "" GTW
 SG_ EPB_f179_unused : 50|1@1+ (1,0) [0|0] "" GTW
 SG_ EPB_f180_unused : 51|1@1+ (1,0) [0|0] "" GTW
 SG_ EPB_f181_unused : 52|1@1+ (1,0) [0|0] "" GTW
 SG_ EPB_f182_unused : 53|1@1+ (1,0) [0|0] "" GTW
 SG_ EPB_f183_unused : 54|1@1+ (1,0) [0|0] "" GTW
 SG_ EPB_f184_unused : 55|1@1+ (1,0) [0|0] "" GTW
 SG_ EPB_f185_unused : 56|1@1+ (1,0) [0|0] "" GTW
 SG_ EPB_f186_unused : 57|1@1+ (1,0) [0|0] "" GTW
 SG_ EPB_f187_unused : 58|1@1+ (1,0) [0|0] "" GTW
 SG_ EPB_f188_unused : 59|1@1+ (1,0) [0|0] "" GTW
 SG_ EPB_f189_unused : 60|1@1+ (1,0) [0|0] "" GTW
 SG_ EPB_f190_unused : 61|1@1+ (1,0) [0|0] "" GTW
 SG_ EPB_f191_unused : 62|1@1+ (1,0) [0|0] "" GTW
 SG_ EPB_f192_unused : 63|1@1+ (1,0) [0|0] "" GTW

BO_ 1524 EPB_bootID: 8 EPB
 SG_ EPB_bootIdData : 0|64@1+ (1,0) [0|0] "" GTWU

BO_ 1044 EPB_chNm: 1 EPB
 SG_ EPB_nmGoingToSleep : 0|1@1+ (1,0) [0|0] "" GTW
 SG_ EPB_nmWakeUpBus : 1|1@1+ (1,0) [0|0] "" GTW
 SG_ EPB_nmWakeUpReason : 2|2@1+ (1,0) [0|0] "" GTW
 SG_ EPB_nmKeepAwakeReason : 4|2@1+ (1,0) [0|0] "" GTW

BO_ 1812 EPB_debugOutput: 8 EPB
 SG_ EPB_debugOutput M : 0|8@1+ (1,0) [0|0] "" DBG
 SG_ EPB_dutyCycleL m0 : 8|12@1+ (1,0) [0|0] "" DBG
 SG_ EPB_leftMotorEna m0 : 20|1@1+ (1,0) [0|0] "" DBG
 SG_ EPB_rightMotorEna m0 : 21|1@1+ (1,0) [0|0] "" DBG
 SG_ EPB_learnedBrakeHwType m0 : 22|2@1+ (1,0) [0|2] "" DBG
 SG_ EPB_brakeHwTypeLearnState m0 : 24|2@1+ (1,0) [0|2] "" DBG
 SG_ EPB_learnedEpasType m0 : 26|3@1+ (1,0) [0|2] "" DBG
 SG_ EPB_epasTypeLearnState m0 : 29|2@1+ (1,0) [0|2] "" DBG
 SG_ EPB_configMismatch m0 : 31|1@1+ (1,0) [0|2] "" DBG
 SG_ EPB_CAN_brakeHwType m0 : 32|2@1+ (1,0) [0|2] "" DBG
 SG_ EPB_learnedChassisType m0 : 34|2@1+ (1,0) [0|2] "" DBG
 SG_ EPB_chassisTypeLearnState m0 : 36|2@1+ (1,0) [0|2] "" DBG
 SG_ EPB_epasTypeMismatch m0 : 38|1@1+ (1,0) [0|0] "" DBG
 SG_ EPB_chassisTypeMismatch m0 : 39|1@1+ (1,0) [0|0] "" DBG
 SG_ EPB_leftVoltageCounts m0 : 40|12@1+ (1,0) [0|0] "" DBG
 SG_ EPB_3VFilt m0 : 52|12@1+ (0.0008056640625,0) [0|0] "V" DBG
 SG_ EPB_leftCurrentFilt m1 : 8|12@1+ (0.017346834,-37.87878788) [0|0] "A" DBG
 SG_ EPB_idleFaultLeft m1 : 20|1@1+ (1,0) [0|0] "" DBG
 SG_ EPB_idleFaultRight m1 : 21|1@1+ (1,0) [0|0] "" DBG
 SG_ EPB_rightCurrentFilt m1 : 24|12@1+ (0.017346834,-37.87878788) [0|0] "A" DBG
 SG_ EPB_epasEacState m1 : 36|3@1+ (1,0) [0|0] "" DBG
 SG_ EPB_armRelease m1 : 39|1@1+ (1,0) [0|0] "" DBG
 SG_ EPB_dutyCycleR m1 : 40|12@1+ (1,0) [0|0] "" DBG
 SG_ EPB_5VFilt m1 : 52|12@1+ (0.001220703125,0) [0|0] "V" DBG
 SG_ EPB_iFactor m2 : 8|14@1+ (0.017346834,0) [0|0] "A" DBG
 SG_ EPB_pFactor m2 : 22|14@1+ (0.017346834,0) [0|0] "A" DBG
 SG_ EPB_12VFilt m2 : 40|12@1+ (0.005443676098,0) [0|0] "V" DBG
 SG_ EPB_autoReapplyRequested m2 : 52|1@1+ (1,0) [0|0] "" DBG
 SG_ EPB_slopeReapplyRequested m2 : 53|1@1+ (1,0) [0|0] "" DBG
 SG_ EPB_slope m2 : 54|2@1+ (1,0) [0|0] "" DBG
 SG_ EPB_reqVL m2 : 56|8@1+ (0.07734375,0) [0|0] "V" DBG
 SG_ EPB_leftPVFilt m3 : 8|12@1+ (0.004833984375,0) [0|0] "V" DBG
 SG_ EPB_rightPVFilt m3 : 20|12@1+ (0.004833984375,0) [0|0] "V" DBG
 SG_ EPB_internalState m3 : 32|4@1+ (1,0) [0|0] "" DBG
 SG_ EPB_internalReqState m3 : 36|4@1+ (1,0) [0|0] "" DBG
 SG_ EPB_ctrl m3 : 40|12@1+ (1,0) [0|0] "" DBG
 SG_ EPB_leftNVFilt m4 : 8|12@1+ (0.004833984375,0) [0|0] "V" DBG
 SG_ EPB_rightNVFilt m4 : 20|12@1+ (0.004833984375,0) [0|0] "V" DBG
 SG_ EPB_internalPendingState m4 : 32|4@1+ (1,0) [0|0] "" DBG
 SG_ EPB_rightVoltageCounts m4 : 40|12@1+ (1,0) [0|0] "" DBG
 SG_ EPB_currentDiffMaxLeft m4 : 52|12@1+ (0.244140625,0) [0|0] "mA" DBG
 SG_ EPB_batt1 m5 : 8|12@1+ (0.005443676098,0) [0|0] "V" DBG
 SG_ EPB_batt2 m5 : 20|12@1+ (0.005443676098,0) [0|0] "V" DBG
 SG_ EPB_currentDiffMaxRight m5 : 44|12@1+ (0.244140625,0) [0|0] "mA" DBG
 SG_ EPB_reqVR m5 : 56|8@1+ (0.07734375,0) [0|0] "V" DBG
 SG_ EPB_maxSteeringAngle m6 : 8|15@0+ (0.1,-1638.35) [-1638.35|1638.35] "deg" DBG
 SG_ EPB_steeringRequest m6 : 24|15@0+ (0.1,-1638.35) [-1638.35|1638.35] "deg" DBG
 SG_ EPB_diEpbUnparkRequest m6 : 25|1@1+ (1,0) [0|0] "" DBG
 SG_ EPB_longAFilt m6 : 48|8@1- (0.08,0) [-10.24|10] "m/s^2" DBG
 SG_ EPB_selfParkFaultReason m6 : 56|8@1+ (1,0) [0|0] "" DBG
 SG_ EPB_uncalibratedCurrentLeft m7 : 8|12@1+ (0.017346834,-37.87878788) [0|0] "A" DBG
 SG_ EPB_uncalibratedCurrentRight m7 : 20|12@1+ (0.017346834,-37.87878788) [0|0] "A" DBG
 SG_ EPB_currentDiffLeft m7 : 32|12@1+ (0.017346834,-37.87878788) [0|0] "A" DBG
 SG_ EPB_currentDiffRight m7 : 44|12@1+ (0.017346834,-37.87878788) [0|0] "A" DBG
 SG_ EPB_eepromWrites m7 : 56|4@1+ (1,0) [0|0] "" DBG
 SG_ EPB_eepromReads m7 : 60|4@1+ (1,0) [0|0] "" DBG
 SG_ EPB_currentOffsetLeft m8 : 8|12@1+ (0.017346834,-37.87878788) [0|0] "A" DBG
 SG_ EPB_currentOffsetRight m8 : 20|12@1+ (0.017346834,-37.87878788) [0|0] "A" DBG
 SG_ EPB_currentPeakLeft m8 : 32|12@1+ (0.017346834,-37.87878788) [0|0] "A" GTW
 SG_ EPB_currentPeakRight m8 : 44|12@1+ (0.017346834,-37.87878788) [0|0] "A" GTW
 SG_ EPB_currentOffsetMaxLeft m9 : 8|12@1+ (0.017346834,-37.87878788) [0|0] "A" GTW
 SG_ EPB_currentOffsetMinLeft m9 : 20|12@1+ (0.017346834,-37.87878788) [0|0] "A" GTW
 SG_ EPB_currentOffsetMaxRight m9 : 32|12@1+ (0.017346834,-37.87878788) [0|0] "A" GTW
 SG_ EPB_currentOffsetMinRight m9 : 44|12@1+ (0.017346834,-37.87878788) [0|0] "A" GTW
 SG_ EPB_nmState m9 : 59|3@1+ (1,0) [0|0] "" DBG
 SG_ EPB_offsetApplied m9 : 62|2@1+ (1,0) [0|0] "" DBG

BO_ 1892 EPB_debugOutput2: 8 EPB
 SG_ EPB_debugOutput2 M : 0|8@1+ (1,0) [0|0] "" DBG
 SG_ EPB_idleStack m0 : 8|16@1+ (1,0) [0|0] "" DBG
 SG_ EPB_memoryStack m0 : 24|16@1+ (1,0) [0|0] "" DBG
 SG_ EPB_delayL m0 : 40|12@1+ (1,0) [0|0] "" DBG
 SG_ EPB_delayR m0 : 52|12@1+ (1,0) [0|0] "" DBG
 SG_ EPB_leftEncoderCounts m1 : 8|12@1+ (1,0) [0|0] "" DBG
 SG_ EPB_rightEncoderCounts m1 : 20|12@1+ (1,0) [0|0] "" DBG
 SG_ EPB_leftEncoderDelta m1 : 32|12@1+ (1,0) [0|0] "" DBG
 SG_ EPB_rightEncoderDelta m1 : 44|12@1+ (1,0) [0|0] "" DBG
 SG_ EPB_currentOffsetStatSatLeft m2 : 8|12@1+ (0.017346834,-37.87878788) [0|0] "A" DBG
 SG_ EPB_currentOffsetStatSatRight m2 : 20|12@1+ (0.017346834,-37.87878788) [0|0] "A" DBG
 SG_ EPB_currentOffsetDynSatLeft m2 : 32|12@1+ (0.017346834,-37.87878788) [0|0] "A" DBG
 SG_ EPB_currentOffsetDynSatRight m2 : 44|12@1+ (0.017346834,-37.87878788) [0|0] "A" DBG
 SG_ EPB_currentOffsetReleaseLeft m3 : 8|12@1+ (0.017346834,-37.87878788) [0|0] "A" DBG
 SG_ EPB_currentOffsetReleaseRight m3 : 20|12@1+ (0.017346834,-37.87878788) [0|0] "A" DBG
 SG_ EPB_inrushTimerL m3 : 32|12@1+ (1,0) [0|0] "" DBG
 SG_ EPB_inrushTimerR m3 : 44|12@1+ (1,0) [0|0] "" DBG

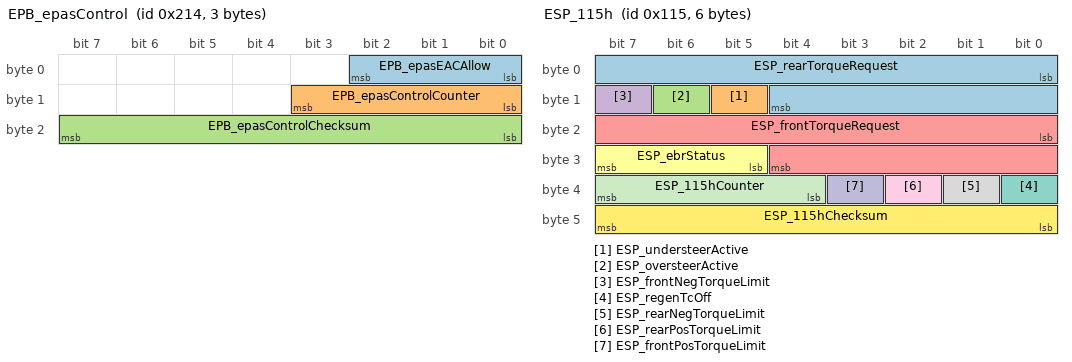
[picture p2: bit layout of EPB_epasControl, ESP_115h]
BO_ 532 EPB_epasControl: 3 EPB
 SG_ EPB_epasEACAllow : 0|3@1+ (1,0) [0|0] "" EPAS,EPAS2,EPAS3S
 SG_ EPB_epasControlCounter : 8|4@1+ (1,0) [0|0] "" EPAS,EPAS2,EPAS3S
 SG_ EPB_epasControlChecksum : 16|8@1+ (1,0) [0|0] "" EPAS,EPAS2,EPAS3S

BO_ 1332 EPB_info: 8 EPB
 SG_ EPB_infoIndex M : 0|8@1+ (1,0) [0|0] "" GTW,GTWU
 SG_ EPB_infoBuildType m10 : 8|8@1+ (1,0) [0|0] "" GTW
 SG_ EPB_infoBuildConfigID m10 : 16|16@1+ (1,0) [0|0] "" GTW
 SG_ EPB_infoHardwareID m10 : 32|16@1+ (1,0) [0|0] "" GTW
 SG_ EPB_infoComponentID m10 : 48|16@1+ (1,0) [0|0] "" GTW
 SG_ EPB_infoPcbaID m11 : 16|8@1+ (1,0) [0|0] "" GTW
 SG_ EPB_infoAssemblyID m11 : 24|8@1+ (1,0) [0|255] "" GTW
 SG_ EPB_infoUsageID m11 : 32|16@1+ (1,0) [0|65535] "" GTW
 SG_ EPB_infoSubUsageID m11 : 48|16@1+ (1,0) [0|65535] "" GTW
 SG_ EPB_infoApplicationCRC m13 : 32|32@1+ (1,0) [0|0] "" GTW,GTWU
 SG_ EPB_infoBootloaderSvnRevision m14 : 8|24@1+ (1,0) [0|0] "" GTW
 SG_ EPB_infoAppGitHashBytes m17 : 8|56@1+ (1,0) [0|0] "" GTW
 SG_ EPB_infoBootGitHashBytes m18 : 8|56@1+ (1,0) [0|0] "" GTW
 SG_ EPB_infoPlatformType m19 : 8|8@1+ (1,0) [0|0] "" GTW
 SG_ EPB_infoMajorVersion m19 : 16|8@1+ (1,0) [0|0] "" GTW
 SG_ EPB_infoBranchOrigin m19 : 24|8@1+ (1,0) [0|0] "" GTW
 SG_ EPB_infoMaturity m19 : 32|8@1+ (1,0) [0|0] "" GTW
 SG_ EPB_infoHardwareRevision m19 : 40|8@1+ (1,0) [0|0] "" GTW
 SG_ EPB_infoBootUdsProtoVersion m20 : 8|8@1+ (1,0) [0|0] "" GTW
 SG_ EPB_infoBootloaderCRC m20 : 32|32@1+ (1,0) [0|0] "" GTW

BO_ 1828 EPB_statsOutput: 8 EPB
 SG_ EPB_statsOutput M : 0|8@1+ (1,0) [0|0] "" DBG
 SG_ EPB_staticApply0Counts m0 : 8|25@1+ (1,0) [0|0] "" GTW
 SG_ EPB_eepromVersion m0 : 60|4@1+ (1,0) [0|0] "" DBG
 SG_ EPB_staticApply1Counts m1 : 8|25@1+ (1,0) [0|0] "" GTW
 SG_ EPB_staticApply2Counts m2 : 8|25@1+ (1,0) [0|0] "" GTW
 SG_ EPB_staticApply3Counts m3 : 8|25@1+ (1,0) [0|0] "" GTW
 SG_ EPB_dynamicApplyCounts m4 : 8|16@1+ (1,0) [0|0] "" GTW
 SG_ EPB_endstopCountL m4 : 24|16@1+ (1,0) [0|0] "" DBG
 SG_ EPB_endstopCountR m4 : 40|16@1+ (1,0) [0|0] "" DBG

BO_ 516 EPB_status: 8 EPB
 SG_ EPB_state : 0|3@1+ (1,0) [0|0] "" IBST,DAS,ESP,PARK,GTW,EPBM,GTWU,RCM
 SG_ EPB_stateRequest : 3|3@1+ (1,0) [0|0] "" ESP,GTW
 SG_ EPB_brakeLight : 8|2@1+ (1,0) [0|0] "" GTW,BDY,BCCEN
 SG_ EPB_substateL : 10|3@1+ (1,0) [0|0] "" PARK,GTW,EPBM
 SG_ EPB_substateR : 13|3@1+ (1,0) [0|0] "" PARK,GTW,EPBM
 SG_ EPB_brakeHwTypeMismatch : 16|1@1+ (1,0) [0|1] "" GTW
 SG_ EPB_freeRollingModeStatus : 17|3@1+ (1,0) [0|0] "" GTW
 SG_ EPB_brakeApplied : 22|2@1+ (1,0) [0|0] "" GTW
 SG_ EPB_statePending : 24|3@1+ (1,0) [0|0] "" GTW
 SG_ EPB_calibrationStateLeft : 27|3@1+ (1,0) [0|0] "" GTW
 SG_ EPB_towModeEnabled : 32|1@1+ (1,0) [0|0] "" GTW,EPBM,GTWU
 SG_ EPB_requestUserConfirmation : 33|1@1+ (1,0) [0|0] "" GTW
 SG_ EPB_ignoreCan : 34|2@1+ (1,0) [0|3] "" GTW,EPBM,GTWU
 SG_ EPB_selfParkEnabled : 36|1@1+ (1,0) [0|3] "" GTW
 SG_ EPB_selfParkState : 37|3@1+ (1,0) [0|7] "" GTW
 SG_ EPB_mcuButtonAvailable : 40|1@1+ (1,0) [0|1] "" GTW
 SG_ EPB_telltale : 41|3@1+ (1,0) [0|0] "" GTW
 SG_ EPB_syncState : 44|3@1+ (1,0) [0|7] "" GTW
 SG_ EPB_calibrationStateRight : 47|3@1+ (1,0) [0|0] "" GTW
 SG_ EPB_statusCounter : 52|4@1+ (1,0) [0|15] "" IBST,ESP,GTW,RCM
 SG_ EPB_statusChecksum : 56|8@1+ (1,0) [0|255] "" IBST,ESP,GTW,RCM

BO_ 1620 EPB_udsResponse: 8 EPB
 SG_ EPB_udsResponseData_H : 7|32@0+ (1,0) [0|4294967295] "" GTW,GTWU
 SG_ EPB_udsResponseData_L : 39|32@0+ (1,0) [0|4294967295] "" GTW,GTWU

BO_ 277 ESP_115h: 6 ESP
 SG_ ESP_rearTorqueRequest : 0|13@1- (0.25,0) [-1000|1000] "Nm" GTW
 SG_ ESP_understeerActive : 13|1@1+ (1,0) [0|1] "" GTW,TAS2,DAS
 SG_ ESP_oversteerActive : 14|1@1+ (1,0) [0|1] "" GTW,TAS2,DAS
 SG_ ESP_frontNegTorqueLimit : 15|1@1+ (1,0) [0|0] "" GTW,DAS,RADAR
 SG_ ESP_frontTorqueRequest : 16|13@1- (0.25,0) [-1000|1000] "Nm" GTW
 SG_ ESP_ebrStatus : 29|3@1+ (1,0) [0|7] "" GTW,EPB,EPBM
 SG_ ESP_regenTcOff : 32|1@1+ (1,0) [0|0] "" GTW
 SG_ ESP_rearNegTorqueLimit : 33|1@1+ (1,0) [0|0] "" GTW,RADAR
 SG_ ESP_rearPosTorqueLimit : 34|1@1+ (1,0) [0|0] "" GTW,RADAR
 SG_ ESP_frontPosTorqueLimit : 35|1@1+ (1,0) [0|0] "" GTW,RADAR
 SG_ ESP_115hCounter : 36|4@1+ (1,0) [0|0] "" GTW,TAS2
 SG_ ESP_115hChecksum : 40|8@1+ (1,0) [0|0] "" GTW,TAS2

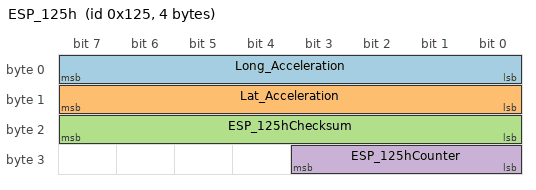
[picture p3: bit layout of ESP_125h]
BO_ 293 ESP_125h: 4 ESP
 SG_ Long_Acceleration : 0|8@1- (0.08,0) [-10.24|10] "m/s^2" DAS,GTW,EAS,EPAS3S
 SG_ Lat_Acceleration : 8|8@1- (0.08,0) [-10.24|10] "m/s^2" DAS,GTW,EAS,EPAS3S
 SG_ ESP_125hChecksum : 16|8@1+ (1,0) [0|0] "" GTW,EAS,EPAS3S
 SG_ ESP_125hCounter : 24|4@1+ (1,0) [0|0] "" GTW,EAS,EPAS3S

BO_ 309 ESP_135h: 5 ESP
 SG_ ESP_hillStartAssistActive : 0|2@1+ (1,0) [0|3] "" GTW
 SG_ ESP_absBrakeEvent : 2|1@1+ (1,0) [0|0] "" SDM,GTW
 SG_ ESP_brakeLamp : 3|1@1+ (1,0) [0|0] "" BDY,BCCEN,GTW
 SG_ ESP_brakeDiscWipingActive : 4|1@1+ (1,0) [0|1] "" GTW
 SG_ ESP_tcLampFlash : 5|1@1+ (1,0) [0|0] "" GTW,PARK
 SG_ ESP_espFaultLamp : 6|1@1+ (1,0) [0|0] "" GTW
 SG_ ESP_espLampFlash : 7|1@1+ (1,0) [0|0] "" GTW
 SG_ ESP_135hCounter : 8|4@1+ (1,0) [0|0] "" SDM,GTW,RCM
 SG_ ESP_stabilityControlSts : 12|3@1+ (1,0) [0|4] "" DAS,SDM,GTW
 SG_ ESP_tcOffLamp : 15|1@1+ (1,0) [0|0] "" GTW,RCM
 SG_ ESP_135hChecksum : 16|8@1+ (1,0) [0|0] "" SDM,GTW,RCM
 SG_ ESP_messagePumpService : 24|1@1+ (1,0) [0|0] "" GTW
 SG_ ESP_messagePumpFailure : 25|1@1+ (1,0) [0|0] "" GTW
 SG_ ESP_messageEBDFailure : 26|1@1+ (1,0) [0|0] "" GTW
 SG_ ESP_absFaultLamp : 27|1@1+ (1,0) [0|0] "" GTW,RCM
 SG_ ESP_tcDisabledByFault : 28|1@1+ (1,0) [0|0] "" GTW
 SG_ ESP_messageDynoModeActive : 29|1@1+ (1,0) [0|0] "" GTW
 SG_ ESP_hydraulicBoostEnabled : 30|1@1+ (1,0) [0|0] "" GTW
 SG_ ESP_espOffLamp : 31|1@1+ (1,0) [0|0] "" GTW

CM_ BO_ 277 "Cycle time is 10ms in Bosch 5/2/11 software. Will be 20ms in 6/24 release";
CM_ SG_ 551 EPBM_state "EPBM state";
CM_ SG_ 551 EPBM_substateL "EPBM substate";
CM_ SG_ 551 EPBM_substateR "EPBM substate";
CM_ SG_ 532 EPB_epasEACAllow "Inhibit / Allow for EPAS EAC feature";
CM_ SG_ 516 EPB_state "EPB state machine mode - EPB_STATE_PARK or EPB_STATE_HANDBRAKE means parking brake is applied";
CM_ SG_ 516 EPB_stateRequest "EPB requested state machine mode";
CM_ SG_ 516 EPB_brakeLight "Illuminates brake light when dynamic brake is engaged";
CM_ SG_ 516 EPB_substateL "EPB substate left motor";
CM_ SG_ 516 EPB_substateR "EPB substate right motor";
CM_ SG_ 516 EPB_statePending "EPB pending state machine mode";
CM_ SG_ 516 EPB_telltale "Illuminates telltale on the instrument cluster";
CM_ SG_ 277 ESP_rearTorqueRequest "ESP requested rear motor drive torque.";
CM_ SG_ 277 ESP_understeerActive "Indicates ESP understeer control is active";
CM_ SG_ 277 ESP_oversteerActive "Indicates ESP oversteer control is active";
CM_ SG_ 277 ESP_frontNegTorqueLimit "ESP front motor torque request: max.-mode 1=torque increase";
CM_ SG_ 277 ESP_frontTorqueRequest "ESP requested front drive unit torque";
CM_ SG_ 277 ESP_ebrStatus "Indicates the state of the ESP to perform pressure builds for external brake requests.";
CM_ SG_ 277 ESP_regenTcOff "ESP drag torque control is unavailable";
CM_ SG_ 277 ESP_rearNegTorqueLimit "ESP rear motor drive torque request: max.-mode 1=torque increase";
CM_ SG_ 277 ESP_rearPosTorqueLimit "ESP rear motor drive torque request: min.-mode. 1=torque decrease";
CM_ SG_ 277 ESP_frontPosTorqueLimit "ESP front motor drive torque request: min.-mode. 1=torque decrease";
CM_ SG_ 277 ESP_115hCounter "Message counter for ESP_115h message: increments in each message.";
CM_ SG_ 277 ESP_115hChecksum "Message checksum for ESP_115h message: sum of all bytes in message (Unused fields are set to 0) + originating CAN ID (0x1 + 0x15 = 0x16).";
CM_ SG_ 293 Long_Acceleration "Positive acceleration when the vehicle is braking. Long term offset compensated.";
CM_ SG_ 293 Lat_Acceleration "Positive acceleration during a turn to the right. Long term offset compensated.";
CM_ SG_ 293 ESP_125hChecksum "Message checksum for ESP_125h message: sum of all bytes in message (Unused fields are set to 0) + originating CAN ID (0x1 + 0x25 = 0x26)";
CM_ SG_ 293 ESP_125hCounter "Message counter for ESP_125h message: increments in each message.";
CM_ SG_ 309 ESP_hillStartAssistActive "Indicates whether ESP is holding brake pressure for hill start assist.";
CM_ SG_ 309 ESP_absBrakeEvent "Any ABS brake event";
CM_ SG_ 309 ESP_brakeLamp "ESP generated brake lamp control";
CM_ SG_ 309 ESP_brakeDiscWipingActive "Indicates when brake disc wiping is active.";
CM_ SG_ 309 ESP_tcLampFlash "TC in progress indicator lamp";
CM_ SG_ 309 ESP_espFaultLamp "ABS/ESP faulty, indicator lamp request";
CM_ SG_ 309 ESP_espLampFlash "ESP in progress indicator lamp, flashing light request";
CM_ SG_ 309 ESP_135hCounter "Message counter for ESP_135h message: increments in each message.";
CM_ SG_ 309 ESP_stabilityControlSts "{Off = 0, On, Engaged, Faulted, Not Configured}";
CM_ SG_ 309 ESP_tcOffLamp "ESP_tcOffLamp = 1 if User has disabled TC.";
CM_ SG_ 309 ESP_135hChecksum "Message checksum for ESP_135h message: sum of all bytes in message (Unused fields are set to 0) + originating CAN ID (0x1 + 0x35 = 0x36)";
CM_ SG_ 309 ESP_messagePumpService "ESP request to display message Brake Boost Pump Requires Service";
CM_ SG_ 309 ESP_messagePumpFailure "ESP request to display message Boost Pump Failure";
CM_ SG_ 309 ESP_messageEBDFailure "ESP request to display message EBD Failure";
CM_ SG_ 309 ESP_absFaultLamp "ESP request to display ABS Fault Lamp";
CM_ SG_ 309 ESP_tcDisabledByFault "ESP request to display message  TC Disabled by Fault";
CM_ SG_ 309 ESP_messageDynoModeActive "ESP request to display message Dyno Mode Active";
CM_ SG_ 309 ESP_hydraulicBoostEnabled "HBC enabled state when ESP detects failed or missing iBooster.";
CM_ SG_ 309 ESP_espOffLamp "ESP_espOffLamp = 1 if the user has disabled ESP. (not used in ESP1)";
BA_DEF_ BO_ "AlertLogSubSystemId" INT 0 0;
BA_DEF_ BO_ "AlertType" INT 0 4;
BA_DEF_ BO_ "AppBotschaft" ENUM "nein","ja";
BA_DEF_ BO_ "DiagRequest" ENUM "No","Yes";
BA_DEF_ BO_ "DiagResponse" ENUM "No","Yes";
BA_DEF_ BO_ "ETHGatewayMessageSendType" ENUM "UseGenMsgSendType","onWrite","noAutoCode";
BA_DEF_ BO_ "ETHId" STRING ;
BA_DEF_ BO_ "GatewayHandlerEnum" ENUM "noHandler","uds","alertLog","messageLogOnReception","udsClient";
BA_DEF_ BO_ "GatewayMessageAtomic" ENUM "No","Yes";
BA_DEF_ BO_ "GatewayMessageSendType" ENUM "UseGenMsgSendType","onWrite","noAutoCode";
BA_DEF_ BO_ "GenMsgCycleTime" INT 0 0;
BA_DEF_ BO_ "GenMsgCycleTimeFast" INT 0 0;
BA_DEF_ BO_ "GenMsgDelayTime" INT 0 0;
BA_DEF_ BO_ "GenMsgForceMiaCheck" ENUM "No","Yes";
BA_DEF_ BO_ "GenMsgGatewayNotification" STRING ;
BA_DEF_ BO_ "GenMsgILSupport" ENUM "No","Yes";
BA_DEF_ BO_ "GenMsgSaltingFunction" ENUM "No","Yes";
BA_DEF_ BO_ "GenMsgSendType" ENUM "Cyclic","NotUsed","NotUsed","NotUsed","NotUsed","NotUsed","NotUsed","IfActive","NoMsgSendType","Sporadic";
BA_DEF_ BO_ "GenMsgStartValue" STRING ;
BA_DEF_ BO_ "GenMsgTimeOut" INT 0 0;
BA_DEF_ BO_ "MessageIdType" ENUM "normal","udsRequest","udsResponse","udsReserved","udsFunctionalRequest","networkManagement","bootloader","xcp","dtc","diagnostic","vendorExempt";
BA_DEF_ BO_ "NWMBotschaft" ENUM "nein","ja";
BA_DEF_ BO_ "NmMessage" ENUM "No","Yes";
BA_DEF_ BO_ "SubSystemId" INT 0 256;
BA_DEF_ BO_ "UsesChecksum" ENUM "No","Yes";
BA_DEF_ SG_ "FieldType" STRING ;
BA_DEF_ SG_ "FlexKomComment" STRING ;
BA_DEF_ SG_ "FlexKomIsMotorola" ENUM "nein","ja";
BA_DEF_ SG_ "FlexKomSID" INT 0 2147483647;
BA_DEF_ SG_ "FlexKomSigLaenge" INT 0 64;
BA_DEF_ SG_ "FlexKomSigName" STRING ;
BA_DEF_ SG_ "FlexKomSigStartPos" INT 0 63;
BA_DEF_ SG_ "FlexKomSigStartValue" STRING ;
BA_DEF_ SG_ "Gatewaysignal" INT 0 1;
BA_DEF_ SG_ "GenSigCycleTime" INT 0 0;
BA_DEF_ SG_ "GenSigCycleTimeActive" INT 0 0;
BA_DEF_ SG_ "GenSigPersistent" ENUM "No","Yes";
BA_DEF_ SG_ "GenSigSNA" STRING ;
BA_DEF_ SG_ "GenSigSendType" ENUM "Cyclic","OnWrite","OnWriteWithRepetition","OnChange","OnChangeWithRepetition","IfActive","IfActiveWithRepetition","NoSigSendType","NotUsed","NotUsed","NotUsed","NotUsed","NotUsed";
BA_DEF_ SG_ "GenSigStartValue" INT 0 0;
BA_DEF_ SG_ "GenSigTimeout_CGW" INT 0 65535;
BA_DEF_ SG_ "GenSigTimeout_DRVU" INT 0 65535;
BA_DEF_ SG_ "GenSigTimeout_ECM" INT 0 65535;
BA_DEF_ SG_ "GenSigTimeout_EIS" INT 0 65535;
BA_DEF_ SG_ "GenSigTimeout_EPS" INT 0 65535;
BA_DEF_ SG_ "GenSigTimeout_ESP_ABR" INT 0 65535;
BA_DEF_ SG_ "GenSigTimeout_IC" INT 0 65535;
BA_DEF_ SG_ "GenSigTimeout_MPC" INT 0 65535;
BA_DEF_ SG_ "GenSigTimeout_NV" INT 0 65535;
BA_DEF_ SG_ "GenSigTimeout_ORC" INT 0 65535;
BA_DEF_ SG_ "GenSigTimeout_PTS" INT 0 65535;
BA_DEF_ SG_ "GenSigTimeout_RBTM_FL" INT 0 65535;
BA_DEF_ SG_ "GenSigTimeout_RBTM_FR" INT 0 65535;
BA_DEF_ SG_ "GenSigTimeout_RDU" INT 0 65535;
BA_DEF_ SG_ "GenSigTimeout_SCCM" INT 0 65535;
BA_DEF_ SG_ "GenSigTimeout_SPC" INT 0 65535;
BA_DEF_ SG_ "GenSigTimeout_TPM" INT 0 65535;
BA_DEF_ SG_ "LogSignal" STRING ;
BA_DEF_ SG_ "PektronUpdateBitType" ENUM "Not used","Has update bit","Is update bit";
BA_DEF_REL_ BU_SG_REL_ "GenSigTimeoutTime" INT 0 0;

BA_DEF_DEF_ "AlertLogSubSystemId" 0;
BA_DEF_DEF_ "AlertType" 4;
BA_DEF_DEF_ "AppBotschaft" "nein";
BA_DEF_DEF_ "DiagRequest" "No";
BA_DEF_DEF_ "DiagResponse" "No";
BA_DEF_DEF_ "ETHGatewayMessageSendType" "UseGenMsgSendType";
BA_DEF_DEF_ "ETHId" "";
BA_DEF_DEF_ "FieldType" "";
BA_DEF_DEF_ "FlexKomComment" "";
BA_DEF_DEF_ "FlexKomIsMotorola" "";
BA_DEF_DEF_ "FlexKomSID" 0;
BA_DEF_DEF_ "FlexKomSigLaenge" 0;
BA_DEF_DEF_ "FlexKomSigName" "";
BA_DEF_DEF_ "FlexKomSigStartPos" 0;
BA_DEF_DEF_ "FlexKomSigStartValue" "";
BA_DEF_DEF_ "GatewayHandlerEnum" "noHandler";
BA_DEF_DEF_ "GatewayMessageAtomic" "No";
BA_DEF_DEF_ "GatewayMessageSendType" "UseGenMsgSendType";
BA_DEF_DEF_ "Gatewaysignal" 0;
BA_DEF_DEF_ "GenMsgCycleTime" 0;
BA_DEF_DEF_ "GenMsgCycleTimeFast" 0;
BA_DEF_DEF_ "GenMsgDelayTime" 0;
BA_DEF_DEF_ "GenMsgForceMiaCheck" "No";
BA_DEF_DEF_ "GenMsgGatewayNotification" "";
BA_DEF_DEF_ "GenMsgILSupport" "Yes";
BA_DEF_DEF_ "GenMsgSaltingFunction" "No";
BA_DEF_DEF_ "GenMsgSendType" "Cyclic";
BA_DEF_DEF_ "GenMsgStartValue" "";
BA_DEF_DEF_ "GenMsgTimeOut" 0;
BA_DEF_DEF_ "GenSigCycleTime" 0;
BA_DEF_DEF_ "GenSigCycleTimeActive" 0;
BA_DEF_DEF_ "GenSigPersistent" "No";
BA_DEF_DEF_ "GenSigSNA" "";
BA_DEF_DEF_ "GenSigSendType" "Cyclic";
BA_DEF_DEF_ "GenSigStartValue" 0;
BA_DEF_DEF_ "GenSigTimeout_CGW" 0;
BA_DEF_DEF_ "GenSigTimeout_DRVU" 0;
BA_DEF_DEF_ "GenSigTimeout_ECM" 0;
BA_DEF_DEF_ "GenSigTimeout_EIS" 0;
BA_DEF_DEF_ "GenSigTimeout_EPS" 0;
BA_DEF_DEF_ "GenSigTimeout_ESP_ABR" 0;
BA_DEF_DEF_ "GenSigTimeout_IC" 0;
BA_DEF_DEF_ "GenSigTimeout_MPC" 0;
BA_DEF_DEF_ "GenSigTimeout_NV" 0;
BA_DEF_DEF_ "GenSigTimeout_ORC" 0;
BA_DEF_DEF_ "GenSigTimeout_PTS" 0;
BA_DEF_DEF_ "GenSigTimeout_RBTM_FL" 0;
BA_DEF_DEF_ "GenSigTimeout_RBTM_FR" 0;
BA_DEF_DEF_ "GenSigTimeout_RDU" 0;
BA_DEF_DEF_ "GenSigTimeout_SCCM" 0;
BA_DEF_DEF_ "GenSigTimeout_SPC" 0;
BA_DEF_DEF_ "GenSigTimeout_TPM" 0;
BA_DEF_DEF_ "LogSignal" "";
BA_DEF_DEF_ "MessageIdType" "normal";
BA_DEF_DEF_ "NWMBotschaft" "nein";
BA_DEF_DEF_ "NmMessage" "No";
BA_DEF_DEF_ "PektronUpdateBitType" "Not used";
BA_DEF_DEF_ "SubSystemId" 0;
BA_DEF_DEF_ "UsesChecksum" "No";
BA_DEF_DEF_REL_ "GenSigTimeoutTime" 0;
BA_ "AlertLogSubSystemId" BO_ 1463 88;
BA_ "GatewayHandlerEnum" BO_ 1463 2;
BA_ "GenMsgSendType" BO_ 1463 8;
BA_ "GenMsgCycleTime" BO_ 775 1000;
BA_ "GenMsgCycleTime" BO_ 823 1000;
BA_ "GenMsgCycleTime" BO_ 791 1000;
BA_ "GenMsgCycleTime" BO_ 807 1000;
BA_ "GenMsgSendType" BO_ 1527 8;
BA_ "MessageIdType" BO_ 1527 6;
BA_ "GenMsgCycleTime" BO_ 1047 100;
BA_ "GenMsgCycleTime" BO_ 1815 100;
BA_ "GenMsgCycleTime" BO_ 1831 100;
BA_ "GenMsgCycleTime" BO_ 1335 1000;
BA_ "GenMsgTimeOut" BO_ 1335 1000;
BA_ "GenMsgCycleTime" BO_ 551 100;
BA_ "DiagResponse" BO_ 1623 1;
BA_ "GatewayHandlerEnum" BO_ 1623 4;
BA_ "GenMsgSendType" BO_ 1623 8;
BA_ "MessageIdType" BO_ 1623 2;
BA_ "AlertLogSubSystemId" BO_ 1476 13;
BA_ "GatewayHandlerEnum" BO_ 1476 2;
BA_ "GenMsgSendType" BO_ 1476 8;
BA_ "GenMsgCycleTime" BO_ 772 1000;
BA_ "GenMsgCycleTime" BO_ 820 1000;
BA_ "GenMsgCycleTime" BO_ 788 1000;
BA_ "GenMsgCycleTime" BO_ 804 1000;
BA_ "GenMsgCycleTime" BO_ 836 1000;
BA_ "GenMsgCycleTime" BO_ 852 1000;
BA_ "GenMsgCycleTime" BO_ 884 1000;
BA_ "GenMsgSendType" BO_ 1524 8;
BA_ "MessageIdType" BO_ 1524 6;
BA_ "GenMsgCycleTime" BO_ 1044 100;
BA_ "GenMsgCycleTime" BO_ 1812 100;
BA_ "GenMsgCycleTime" BO_ 1892 100;
BA_ "GenMsgCycleTime" BO_ 532 100;
BA_ "GenMsgCycleTime" BO_ 1332 1000;
BA_ "GenMsgTimeOut" BO_ 1332 1000;
BA_ "GenMsgCycleTime" BO_ 516 100;
BA_ "DiagResponse" BO_ 1620 1;
BA_ "GatewayHandlerEnum" BO_ 1620 4;
BA_ "GenMsgSendType" BO_ 1620 8;
BA_ "MessageIdType" BO_ 1620 2;
BA_ "GenMsgCycleTime" BO_ 277 20;
BA_ "GenMsgCycleTime" BO_ 293 100;
BA_ "GenMsgTimeOut" BO_ 293 500;
BA_ "GenMsgCycleTime" BO_ 309 100;
BA_ "FieldType" SG_ 1463 EPBM_alertID "EPBM_alerts";
BA_ "FieldType" SG_ 1463 EPBM_a013_reqState "EPB_state";
BA_ "GenSigSNA" SG_ 1463 EPBM_a013_reqState "7";
BA_ "FieldType" SG_ 1463 EPBM_a013_substate "EPB_substate";
BA_ "FieldType" SG_ 1463 EPBM_a014_reqState "EPB_state";
BA_ "GenSigSNA" SG_ 1463 EPBM_a014_reqState "7";
BA_ "FieldType" SG_ 1463 EPBM_a014_substate "EPB_substate";
BA_ "FieldType" SG_ 1463 EPBM_a015_state "EPB_state";
BA_ "GenSigSNA" SG_ 1463 EPBM_a015_state "7";
BA_ "FieldType" SG_ 1463 EPBM_a015_reqState "EPB_state";
BA_ "GenSigSNA" SG_ 1463 EPBM_a015_reqState "7";
BA_ "FieldType" SG_ 1463 EPBM_a015_EPB_substate "EPB_substate";
BA_ "FieldType" SG_ 1463 EPBM_a022_substateEPB "EPB_substate";
BA_ "FieldType" SG_ 1463 EPBM_a022_substateEPBM "EPBM_substate";
BA_ "FieldType" SG_ 1463 EPBM_a031_stateEPB "EPB_state";
BA_ "GenSigSNA" SG_ 1463 EPBM_a031_stateEPB "7";
BA_ "FieldType" SG_ 1463 EPBM_a031_stateEPBM "EPB_state";
BA_ "GenSigSNA" SG_ 1463 EPBM_a031_stateEPBM "7";
BA_ "FieldType" SG_ 1463 EPBM_a032_reqStateEPB "EPB_state";
BA_ "GenSigSNA" SG_ 1463 EPBM_a032_reqStateEPB "7";
BA_ "FieldType" SG_ 1463 EPBM_a032_reqStateEPBM "EPB_state";
BA_ "GenSigSNA" SG_ 1463 EPBM_a032_reqStateEPBM "7";
BA_ "FieldType" SG_ 1463 EPBM_canErrorType "EPB_CAN_error";
BA_ "FieldType" SG_ 1463 EPBM_a062_state "EPB_state";
BA_ "GenSigSNA" SG_ 1463 EPBM_a062_state "7";
BA_ "FieldType" SG_ 1463 EPBM_a077_reqState "EPB_state";
BA_ "GenSigSNA" SG_ 1463 EPBM_a077_reqState "7";
BA_ "FieldType" SG_ 1463 EPBM_a077_substate "EPB_substate";
BA_ "FieldType" SG_ 1463 EPBM_a078_reqState "EPB_state";
BA_ "GenSigSNA" SG_ 1463 EPBM_a078_reqState "7";
BA_ "FieldType" SG_ 1463 EPBM_a078_substate "EPB_substate";
BA_ "FieldType" SG_ 1463 EPBM_a079_state "EPB_state";
BA_ "GenSigSNA" SG_ 1463 EPBM_a079_state "7";
BA_ "FieldType" SG_ 1463 EPBM_a079_reqState "EPB_state";
BA_ "GenSigSNA" SG_ 1463 EPBM_a079_reqState "7";
BA_ "FieldType" SG_ 1463 EPBM_a079_EPB_substate "EPB_substate";
BA_ "FieldType" SG_ 1463 EPBM_a086_substateEPB "EPB_substate";
BA_ "FieldType" SG_ 1463 EPBM_a086_substateEPBM "EPB_substate";
BA_ "FieldType" SG_ 1463 EPBM_a096_selfParkAbortReason "EPBM_selfParkFaultReason";
BA_ "FieldType" SG_ 1463 EPBM_a106_alertID "EPBM_alerts";
BA_ "FieldType" SG_ 1463 EPBM_a106_motorSel "EPB_motorSel";
BA_ "FieldType" SG_ 1463 EPBM_a107_alertID "EPBM_alerts";
BA_ "FieldType" SG_ 1463 EPBM_a107_motorSel "EPB_motorSel";
BA_ "FieldType" SG_ 1463 EPBM_a110_offsetApplied "EPB_offsetApplied";
BA_ "FieldType" SG_ 1463 EPBM_a111_offsetApplied "EPB_offsetApplied";
BA_ "FieldType" SG_ 1463 EPBM_a112_offsetApplied "EPB_offsetApplied";
BA_ "FieldType" SG_ 1463 EPBM_a113_offsetApplied "EPB_offsetApplied";
BA_ "FieldType" SG_ 1463 EPBM_a114_pendingState "EPB_state";
BA_ "GenSigSNA" SG_ 1463 EPBM_a114_pendingState "7";
BA_ "FieldType" SG_ 1463 EPBM_a117_brakeHwType_CAN "EPB_CAN_brakeHwType";
BA_ "FieldType" SG_ 1463 EPBM_a117_brakeHwType_EPB "EPB_CAN_brakeHwType";
BA_ "FieldType" SG_ 1047 EPBM_nmKeepAwakeReason "EPBM_NM_keepAwakeReason";
BA_ "GenSigSNA" SG_ 1047 EPBM_nmKeepAwakeReason "0";
BA_ "LogSignal" SG_ 1047 EPBM_nmKeepAwakeReason "onChange";
BA_ "FieldType" SG_ 1815 EPBM_debugOutput "EPB_debugDataSelect";
BA_ "FieldType" SG_ 1815 EPBM_CAN_brakeHwType "EPB_CAN_brakeHwType";
BA_ "FieldType" SG_ 1815 EPBM_EPB_brakeHwType "EPB_CAN_brakeHwType";
BA_ "FieldType" SG_ 1815 EPBM_CAN_chassisType "EPB_chassisType";
BA_ "GenSigStartValue" SG_ 1815 EPBM_CAN_chassisType 3;
BA_ "FieldType" SG_ 1815 EPBM_EPB_chassisType "EPB_chassisType";
BA_ "GenSigStartValue" SG_ 1815 EPBM_EPB_chassisType 3;
BA_ "FieldType" SG_ 1815 EPBM_selfParkFaultReason "EPBM_selfParkFaultReason";
BA_ "FieldType" SG_ 1815 EPBM_nmState "EPB_nmState";
BA_ "FieldType" SG_ 1815 EPBM_offsetApplied "EPB_offsetApplied";
BA_ "FieldType" SG_ 1831 EPBM_debugOutput2 "EPB_debugDataSelect";
BA_ "FieldType" SG_ 1335 EPBM_infoIndex "infoIndex";
BA_ "GenSigCycleTime" SG_ 1335 EPBM_infoIndex 1000;
BA_ "GenSigStartValue" SG_ 1335 EPBM_infoApplicationCRC 4294967295;
BA_ "GenSigStartValue" SG_ 1335 EPBM_infoPlatformType 255;
BA_ "FieldType" SG_ 551 EPBM_state "EPB_state";
BA_ "GenSigSNA" SG_ 551 EPBM_state "7";
BA_ "GenSigStartValue" SG_ 551 EPBM_state 7;
BA_ "LogSignal" SG_ 551 EPBM_state "onChange";
BA_ "FieldType" SG_ 551 EPBM_stateRequest "EPB_state";
BA_ "GenSigSNA" SG_ 551 EPBM_stateRequest "7";
BA_ "GenSigStartValue" SG_ 551 EPBM_stateRequest 7;
BA_ "LogSignal" SG_ 551 EPBM_stateRequest "onChange";
BA_ "FieldType" SG_ 551 EPBM_substateL "EPBM_substate";
BA_ "LogSignal" SG_ 551 EPBM_substateL "onChange";
BA_ "FieldType" SG_ 551 EPBM_substateR "EPBM_substate";
BA_ "LogSignal" SG_ 551 EPBM_substateR "onChange";
BA_ "FieldType" SG_ 551 EPBM_statePending "EPB_state";
BA_ "GenSigSNA" SG_ 551 EPBM_statePending "7";
BA_ "GenSigStartValue" SG_ 551 EPBM_statePending 7;
BA_ "FieldType" SG_ 551 EPBM_selfParkState "EPB_selfParkState";
BA_ "LogSignal" SG_ 551 EPBM_selfParkState "onChange";
BA_ "FieldType" SG_ 551 EPBM_syncState "EPB_syncState";
BA_ "LogSignal" SG_ 551 EPBM_syncState "onChange";
BA_ "FieldType" SG_ 551 EPBM_calibrationStateLeft "EPB_calibrationState";
BA_ "FieldType" SG_ 551 EPBM_calibrationStateRight "EPB_calibrationState";
BA_ "FieldType" SG_ 551 EPBM_clampCurrentMonitor "EPBM_clampCurrentMonitor";
BA_ "FieldType" SG_ 551 EPBM_freeRollingModeStatus "EPB_freeRollingModeStatus";
BA_ "FieldType" SG_ 1476 EPB_alertID "EPB_alerts";
BA_ "FieldType" SG_ 1476 EPB_a013_reqState "EPB_state";
BA_ "GenSigSNA" SG_ 1476 EPB_a013_reqState "7";
BA_ "FieldType" SG_ 1476 EPB_a013_substate "EPB_substate";
BA_ "FieldType" SG_ 1476 EPB_a014_reqState "EPB_state";
BA_ "GenSigSNA" SG_ 1476 EPB_a014_reqState "7";
BA_ "FieldType" SG_ 1476 EPB_a014_substate "EPB_substate";
BA_ "FieldType" SG_ 1476 EPB_a015_state "EPB_state";
BA_ "GenSigSNA" SG_ 1476 EPB_a015_state "7";
BA_ "FieldType" SG_ 1476 EPB_a015_reqState "EPB_state";
BA_ "GenSigSNA" SG_ 1476 EPB_a015_reqState "7";
BA_ "FieldType" SG_ 1476 EPB_a022_EPBsubstate "EPB_substate";
BA_ "FieldType" SG_ 1476 EPB_a022_EPBMsubstate "EPBM_substate";
BA_ "FieldType" SG_ 1476 EPB_a028_EPBreqState "EPB_state";
BA_ "GenSigSNA" SG_ 1476 EPB_a028_EPBreqState "7";
BA_ "FieldType" SG_ 1476 EPB_a028_EPBMreqState "EPB_state";
BA_ "GenSigSNA" SG_ 1476 EPB_a028_EPBMreqState "7";
BA_ "FieldType" SG_ 1476 EPB_a029_EPBstate "EPB_state";
BA_ "GenSigSNA" SG_ 1476 EPB_a029_EPBstate "7";
BA_ "FieldType" SG_ 1476 EPB_a029_EPBMstate "EPB_state";
BA_ "GenSigSNA" SG_ 1476 EPB_a029_EPBMstate "7";
BA_ "FieldType" SG_ 1476 EPB_canErrorType "EPB_CAN_error";
BA_ "FieldType" SG_ 1476 EPB_a062_state "EPB_state";
BA_ "GenSigSNA" SG_ 1476 EPB_a062_state "7";
BA_ "FieldType" SG_ 1476 EPB_a077_reqState "EPB_state";
BA_ "GenSigSNA" SG_ 1476 EPB_a077_reqState "7";
BA_ "FieldType" SG_ 1476 EPB_a077_substate "EPB_substate";
BA_ "FieldType" SG_ 1476 EPB_a078_reqState "EPB_state";
BA_ "GenSigSNA" SG_ 1476 EPB_a078_reqState "7";
BA_ "FieldType" SG_ 1476 EPB_a078_substate "EPB_substate";
BA_ "FieldType" SG_ 1476 EPB_a079_state "EPB_state";
BA_ "GenSigSNA" SG_ 1476 EPB_a079_state "7";
BA_ "FieldType" SG_ 1476 EPB_a079_reqState "EPB_state";
BA_ "GenSigSNA" SG_ 1476 EPB_a079_reqState "7";
BA_ "FieldType" SG_ 1476 EPB_a086_EPBsubstate "EPB_substate";
BA_ "FieldType" SG_ 1476 EPB_a086_EPBMsubstate "EPBM_substate";
BA_ "FieldType" SG_ 1476 EPB_a094_inhibitEacReason "EPB_inhibitEacReason";
BA_ "FieldType" SG_ 1476 EPB_a097_selfParkAbortReason "EPB_selfParkFaultReason";
BA_ "FieldType" SG_ 1476 EPB_a103_datatype "EPB_EEP_datatype";
BA_ "FieldType" SG_ 1476 EPB_a110_offsetApplied "EPB_offsetApplied";
BA_ "FieldType" SG_ 1476 EPB_a111_offsetApplied "EPB_offsetApplied";
BA_ "FieldType" SG_ 1476 EPB_a112_offsetApplied "EPB_offsetApplied";
BA_ "FieldType" SG_ 1476 EPB_a113_offsetApplied "EPB_offsetApplied";
BA_ "FieldType" SG_ 1476 EPB_a114_alertID "EPB_alerts";
BA_ "FieldType" SG_ 1476 EPB_a114_motorSel "EPB_motorSel";
BA_ "FieldType" SG_ 1476 EPB_a115_alertID "EPB_alerts";
BA_ "FieldType" SG_ 1476 EPB_a115_motorSel "EPB_motorSel";
BA_ "FieldType" SG_ 1476 EPB_a117_brakeHwTypeLearnState "EPB_hwLearnState";
BA_ "FieldType" SG_ 1476 EPB_a117_learnedBrakeHwType "GTW_brakeHwType";
BA_ "GenSigSNA" SG_ 1476 EPB_a119_DIgear "7";
BA_ "FieldType" SG_ 1476 EPB_a119_EPBstate "EPB_state";
BA_ "GenSigSNA" SG_ 1476 EPB_a119_EPBstate "7";
BA_ "FieldType" SG_ 1476 EPB_a119_EPBreqState "EPB_state";
BA_ "GenSigSNA" SG_ 1476 EPB_a119_EPBreqState "7";
BA_ "FieldType" SG_ 1476 EPB_a120_state "EPB_state";
BA_ "GenSigSNA" SG_ 1476 EPB_a120_state "7";
BA_ "FieldType" SG_ 1476 EPB_a120_intReqState "EPB_internalState";
BA_ "GenSigSNA" SG_ 1476 EPB_a120_intReqState "7";
BA_ "FieldType" SG_ 1476 EPB_a121_state "EPB_state";
BA_ "GenSigSNA" SG_ 1476 EPB_a121_state "7";
BA_ "FieldType" SG_ 1476 EPB_a121_intReqState "EPB_internalState";
BA_ "GenSigSNA" SG_ 1476 EPB_a121_intReqState "7";
BA_ "GenSigSNA" SG_ 1476 EPB_a128_DIgear "7";
BA_ "FieldType" SG_ 1476 EPB_a128_EPBstate "EPB_state";
BA_ "GenSigSNA" SG_ 1476 EPB_a128_EPBstate "7";
BA_ "FieldType" SG_ 1476 EPB_a128_EPBreqState "EPB_state";
BA_ "GenSigSNA" SG_ 1476 EPB_a128_EPBreqState "7";
BA_ "FieldType" SG_ 1476 EPB_a128_EPBpendingState "EPB_state";
BA_ "GenSigSNA" SG_ 1476 EPB_a128_EPBpendingState "7";
BA_ "FieldType" SG_ 1476 EPB_a128_EPBsubstateL "EPB_substate";
BA_ "FieldType" SG_ 1476 EPB_a128_EPBsubstateR "EPB_substate";
BA_ "GenSigSNA" SG_ 1476 EPB_a129_diGear "7";
BA_ "FieldType" SG_ 1476 EPB_a129_internalPendingState "EPB_internalState";
BA_ "GenSigSNA" SG_ 1476 EPB_a129_internalPendingState "7";
BA_ "FieldType" SG_ 1044 EPB_nmKeepAwakeReason "EPB_NM_keepAwakeReason";
BA_ "GenSigSNA" SG_ 1044 EPB_nmKeepAwakeReason "0";
BA_ "LogSignal" SG_ 1044 EPB_nmKeepAwakeReason "onChange";
BA_ "FieldType" SG_ 1812 EPB_debugOutput "EPB_debugDataSelect";
BA_ "FieldType" SG_ 1812 EPB_learnedBrakeHwType "GTW_brakeHwType";
BA_ "FieldType" SG_ 1812 EPB_brakeHwTypeLearnState "EPB_hwLearnState";
BA_ "FieldType" SG_ 1812 EPB_learnedEpasType "GTW_epasType";
BA_ "FieldType" SG_ 1812 EPB_epasTypeLearnState "EPB_hwLearnState";
BA_ "FieldType" SG_ 1812 EPB_CAN_brakeHwType "EPB_CAN_brakeHwType";
BA_ "FieldType" SG_ 1812 EPB_learnedChassisType "EPB_chassisType";
BA_ "GenSigStartValue" SG_ 1812 EPB_learnedChassisType 3;
BA_ "FieldType" SG_ 1812 EPB_chassisTypeLearnState "EPB_hwLearnState";
BA_ "FieldType" SG_ 1812 EPB_epasEacState "EPB_eacState";
BA_ "FieldType" SG_ 1812 EPB_internalState "EPB_internalState";
BA_ "GenSigSNA" SG_ 1812 EPB_internalState "7";
BA_ "FieldType" SG_ 1812 EPB_internalReqState "EPB_internalState";
BA_ "GenSigSNA" SG_ 1812 EPB_internalReqState "7";
BA_ "FieldType" SG_ 1812 EPB_internalPendingState "EPB_internalState";
BA_ "GenSigSNA" SG_ 1812 EPB_internalPendingState "7";
BA_ "FieldType" SG_ 1812 EPB_selfParkFaultReason "EPB_selfParkFaultReason";
BA_ "LogSignal" SG_ 1812 EPB_currentPeakLeft "onChange";
BA_ "LogSignal" SG_ 1812 EPB_currentPeakRight "onChange";
BA_ "LogSignal" SG_ 1812 EPB_currentOffsetMaxLeft "periodic TEN_SECONDS accRailOn ";
BA_ "LogSignal" SG_ 1812 EPB_currentOffsetMinLeft "periodic TEN_SECONDS accRailOn ";
BA_ "LogSignal" SG_ 1812 EPB_currentOffsetMaxRight "periodic TEN_SECONDS accRailOn ";
BA_ "LogSignal" SG_ 1812 EPB_currentOffsetMinRight "periodic TEN_SECONDS accRailOn ";
BA_ "FieldType" SG_ 1812 EPB_nmState "EPB_nmState";
BA_ "FieldType" SG_ 1812 EPB_offsetApplied "EPB_offsetApplied";
BA_ "FieldType" SG_ 1892 EPB_debugOutput2 "EPB_debugDataSelect";
BA_ "FieldType" SG_ 532 EPB_epasEACAllow "EPB_epasEACAllow";
BA_ "GenSigSNA" SG_ 532 EPB_epasEACAllow "3";
BA_ "LogSignal" SG_ 532 EPB_epasEACAllow "onChange";
BA_ "FieldType" SG_ 1332 EPB_infoIndex "infoIndex";
BA_ "GenSigCycleTime" SG_ 1332 EPB_infoIndex 1000;
BA_ "GenSigStartValue" SG_ 1332 EPB_infoApplicationCRC 4294967295;
BA_ "GenSigStartValue" SG_ 1332 EPB_infoPlatformType 255;
BA_ "FieldType" SG_ 1828 EPB_statsOutput "EPB_statsSelect";
BA_ "LogSignal" SG_ 1828 EPB_staticApply0Counts "periodic ONE_DAY Any";
BA_ "LogSignal" SG_ 1828 EPB_staticApply1Counts "periodic ONE_DAY Any";
BA_ "LogSignal" SG_ 1828 EPB_staticApply2Counts "periodic ONE_DAY Any";
BA_ "LogSignal" SG_ 1828 EPB_staticApply3Counts "periodic ONE_DAY Any";
BA_ "LogSignal" SG_ 1828 EPB_dynamicApplyCounts "periodic ONE_DAY Any";
BA_ "FieldType" SG_ 516 EPB_state "EPB_state";
BA_ "GenSigSNA" SG_ 516 EPB_state "7";
BA_ "LogSignal" SG_ 516 EPB_state "onChange";
BA_ "FieldType" SG_ 516 EPB_stateRequest "EPB_state";
BA_ "GenSigSNA" SG_ 516 EPB_stateRequest "7";
BA_ "LogSignal" SG_ 516 EPB_stateRequest "onChange";
BA_ "FieldType" SG_ 516 EPB_substateL "EPB_substate";
BA_ "LogSignal" SG_ 516 EPB_substateL "onChange";
BA_ "FieldType" SG_ 516 EPB_substateR "EPB_substate";
BA_ "LogSignal" SG_ 516 EPB_substateR "onChange";
BA_ "FieldType" SG_ 516 EPB_freeRollingModeStatus "EPB_freeRollingModeStatus";
BA_ "GenSigSNA" SG_ 516 EPB_brakeApplied "3";
BA_ "GenSigStartValue" SG_ 516 EPB_brakeApplied 3;
BA_ "FieldType" SG_ 516 EPB_statePending "EPB_state";
BA_ "GenSigSNA" SG_ 516 EPB_statePending "7";
BA_ "GenSigStartValue" SG_ 516 EPB_statePending 7;
BA_ "FieldType" SG_ 516 EPB_calibrationStateLeft "EPB_calibrationState";
BA_ "LogSignal" SG_ 516 EPB_towModeEnabled "onChange";
BA_ "FieldType" SG_ 516 EPB_ignoreCan "EPB_ignoreCan";
BA_ "GenSigSNA" SG_ 516 EPB_ignoreCan "3";
BA_ "FieldType" SG_ 516 EPB_selfParkState "EPB_selfParkState";
BA_ "LogSignal" SG_ 516 EPB_selfParkState "onChange";
BA_ "FieldType" SG_ 516 EPB_telltale "EPB_telltale";
BA_ "GenSigSNA" SG_ 516 EPB_telltale "7";
BA_ "GenSigStartValue" SG_ 516 EPB_telltale 7;
BA_ "FieldType" SG_ 516 EPB_syncState "EPB_syncState";
BA_ "LogSignal" SG_ 516 EPB_syncState "onChange";
BA_ "FieldType" SG_ 516 EPB_calibrationStateRight "EPB_calibrationState";
BA_ "FlexKomComment" SG_ 277 ESP_rearTorqueRequest "Momentenanforderung ESP";
BA_ "FlexKomIsMotorola" SG_ 277 ESP_rearTorqueRequest 1;
BA_ "FlexKomSID" SG_ 277 ESP_rearTorqueRequest 33554835;
BA_ "FlexKomSigLaenge" SG_ 277 ESP_rearTorqueRequest 40;
BA_ "FlexKomSigStartPos" SG_ 277 ESP_rearTorqueRequest 15;
BA_ "FlexKomSigStartValue" SG_ 277 ESP_rearTorqueRequest "8000001FFFh";
BA_ "GenSigCycleTime" SG_ 277 ESP_rearTorqueRequest 10;
BA_ "FlexKomComment" SG_ 277 ESP_frontNegTorqueLimit "Momentenanforderung ESP";
BA_ "FlexKomIsMotorola" SG_ 277 ESP_frontNegTorqueLimit 1;
BA_ "FlexKomSID" SG_ 277 ESP_frontNegTorqueLimit 33554835;
BA_ "FlexKomSigLaenge" SG_ 277 ESP_frontNegTorqueLimit 40;
BA_ "FlexKomSigStartPos" SG_ 277 ESP_frontNegTorqueLimit 15;
BA_ "FlexKomSigStartValue" SG_ 277 ESP_frontNegTorqueLimit "8000001FFFh";
BA_ "GenSigCycleTime" SG_ 277 ESP_frontNegTorqueLimit 10;
BA_ "LogSignal" SG_ 277 ESP_frontNegTorqueLimit "onChange";
BA_ "FlexKomComment" SG_ 277 ESP_frontTorqueRequest "Momentenanforderung ESP";
BA_ "FlexKomIsMotorola" SG_ 277 ESP_frontTorqueRequest 1;
BA_ "FlexKomSID" SG_ 277 ESP_frontTorqueRequest 33554835;
BA_ "FlexKomSigLaenge" SG_ 277 ESP_frontTorqueRequest 40;
BA_ "FlexKomSigStartPos" SG_ 277 ESP_frontTorqueRequest 15;
BA_ "FlexKomSigStartValue" SG_ 277 ESP_frontTorqueRequest "8000001FFFh";
BA_ "GenSigCycleTime" SG_ 277 ESP_frontTorqueRequest 10;
BA_ "GenSigSNA" SG_ 277 ESP_ebrStatus "7";
BA_ "LogSignal" SG_ 277 ESP_ebrStatus "onChange";
BA_ "GenSigSendType" SG_ 277 ESP_regenTcOff 7;
BA_ "LogSignal" SG_ 277 ESP_regenTcOff "onChange";
BA_ "FlexKomComment" SG_ 277 ESP_rearNegTorqueLimit "Momentenanforderung ESP";
BA_ "FlexKomIsMotorola" SG_ 277 ESP_rearNegTorqueLimit 1;
BA_ "FlexKomSID" SG_ 277 ESP_rearNegTorqueLimit 33554835;
BA_ "FlexKomSigLaenge" SG_ 277 ESP_rearNegTorqueLimit 40;
BA_ "FlexKomSigStartPos" SG_ 277 ESP_rearNegTorqueLimit 15;
BA_ "FlexKomSigStartValue" SG_ 277 ESP_rearNegTorqueLimit "8000001FFFh";
BA_ "GenSigCycleTime" SG_ 277 ESP_rearNegTorqueLimit 10;
BA_ "LogSignal" SG_ 277 ESP_rearNegTorqueLimit "onChange";
BA_ "FlexKomComment" SG_ 277 ESP_rearPosTorqueLimit "Momentenanforderung ESP";
BA_ "FlexKomIsMotorola" SG_ 277 ESP_rearPosTorqueLimit 1;
BA_ "FlexKomSID" SG_ 277 ESP_rearPosTorqueLimit 33554835;
BA_ "FlexKomSigLaenge" SG_ 277 ESP_rearPosTorqueLimit 40;
BA_ "FlexKomSigStartPos" SG_ 277 ESP_rearPosTorqueLimit 15;
BA_ "FlexKomSigStartValue" SG_ 277 ESP_rearPosTorqueLimit "8000001FFFh";
BA_ "GenSigCycleTime" SG_ 277 ESP_rearPosTorqueLimit 10;
BA_ "LogSignal" SG_ 277 ESP_rearPosTorqueLimit "onChange";
BA_ "FlexKomComment" SG_ 277 ESP_frontPosTorqueLimit "Momentenanforderung ESP";
BA_ "FlexKomIsMotorola" SG_ 277 ESP_frontPosTorqueLimit 1;
BA_ "FlexKomSID" SG_ 277 ESP_frontPosTorqueLimit 33554835;
BA_ "FlexKomSigLaenge" SG_ 277 ESP_frontPosTorqueLimit 40;
BA_ "FlexKomSigStartPos" SG_ 277 ESP_frontPosTorqueLimit 15;
BA_ "FlexKomSigStartValue" SG_ 277 ESP_frontPosTorqueLimit "8000001FFFh";
BA_ "GenSigCycleTime" SG_ 277 ESP_frontPosTorqueLimit 10;
BA_ "LogSignal" SG_ 277 ESP_frontPosTorqueLimit "onChange";
BA_ "FlexKomComment" SG_ 277 ESP_115hCounter "Momentenanforderung ESP";
BA_ "FlexKomIsMotorola" SG_ 277 ESP_115hCounter 1;
BA_ "FlexKomSID" SG_ 277 ESP_115hCounter 33554835;
BA_ "FlexKomSigLaenge" SG_ 277 ESP_115hCounter 40;
BA_ "FlexKomSigStartPos" SG_ 277 ESP_115hCounter 15;
BA_ "FlexKomSigStartValue" SG_ 277 ESP_115hCounter "8000001FFFh";
BA_ "GenSigCycleTime" SG_ 277 ESP_115hCounter 10;
BA_ "GenSigCycleTime" SG_ 277 ESP_115hChecksum 10;
BA_ "GenSigSNA" SG_ 293 Long_Acceleration "127";
BA_ "GenSigSNA" SG_ 293 Lat_Acceleration "127";
BA_ "GenSigSNA" SG_ 309 ESP_hillStartAssistActive "3";
BA_ "LogSignal" SG_ 309 ESP_hillStartAssistActive "onChange";
BA_ "FlexKomIsMotorola" SG_ 309 ESP_absBrakeEvent 1;
BA_ "LogSignal" SG_ 309 ESP_absBrakeEvent "onChange";
BA_ "FlexKomIsMotorola" SG_ 309 ESP_espFaultLamp 1;
BA_ "FlexKomIsMotorola" SG_ 309 ESP_espLampFlash 1;
BA_ "LogSignal" SG_ 309 ESP_stabilityControlSts "onChange";
BA_ "LogSignal" SG_ 309 ESP_tcOffLamp "onChange";
VAL_ 1463 EPBM_alertID 128 "EPBM_a128_unused" 127 "EPBM_a127_unused" 126 "EPBM_a126_unused" 125 "EPBM_a125_unused" 124 "EPBM_a124_unused" 123 "EPBM_a123_unused" 122 "EPBM_a122_unused" 121 "EPBM_a121_unused" 120 "EPBM_a120_unused" 119 "EPBM_a119_unused" 118 "EPBM_a118_unused" 117 "EPBM_a117_usedFallbackValues" 116 "EPBM_a116_rightPVoltageHigh" 115 "EPBM_a115_rightNVoltageLow" 114 "EPBM_a114_unparkNotAllowed" 113 "EPBM_a113_calFaultRight" 112 "EPBM_a112_calFaultLeft" 111 "EPBM_a111_calWarningRight" 110 "EPBM_a110_calWarningLeft" 109 "EPBM_a109_unused" 108 "EPBM_a108_unused" 107 "EPBM_a107_currentWarning" 106 "EPBM_a106_voltageWarning" 105 "EPBM_a105_epbWentToSleep" 104 "EPBM_a104_epbStillAsleep" 103 "EPBM_a103_targetNotReachedR" 102 "EPBM_a102_targetNotReachedL" 101 "EPBM_a101_calibrationFault" 100 "EPBM_a100_calibrationWarning" 99 "EPBM_a099_unused" 98 "EPBM_a098_pmMia" 97 "EPBM_a097_parkMia" 96 "EPBM_a096_selfParkAborted" 95 "EPBM_a095_invalidConfig" 94 "EPBM_a094_unused" 93 "EPBM_a093_dasMIA" 92 "EPBM_a092_noCurrentCalR" 91 "EPBM_a091_spuriousEncIntR" 90 "EPBM_a090_rightUnderRelease" 89 "EPBM_a089_rightOverRelease" 88 "EPBM_a088_rightUnderApply" 87 "EPBM_a087_rightOverApply" 86 "EPBM_a086_rightSubstateErr" 85 "EPBM_a085_rightPvUv" 84 "EPBM_a084_rightPvOv" 83 "EPBM_a083_rightNvUv" 82 "EPBM_a082_rightNvOv" 81 "EPBM_a081_rightNHalfBridge" 80 "EPBM_a080_rightPHalfBridge" 79 "EPBM_a079_rightDriveDuration" 78 "EPBM_a078_rightEnaStuckLow" 77 "EPBM_a077_rightEnaStuckHigh" 76 "EPBM_a076_rightPOpen" 75 "EPBM_a075_rightNOpen" 74 "EPBM_a074_rightPShort" 73 "EPBM_a073_rightNShort" 72 "EPBM_a072_rightShortApply" 71 "EPBM_a071_rightEndStop" 70 "EPBM_a070_rightUc" 69 "EPBM_a069_rightOc" 68 "EPBM_a068_rightEncoderSna" 67 "EPBM_a067_rightEncIrrational" 66 "EPBM_a066_rightIdleOc" 65 "EPBM_a065_rightEncIntrpt" 64 "EPBM_a064_unused" 63 "EPBM_a063_unused" 62 "EPBM_a062_diGearInvld" 61 "EPBM_a061_maxCycles2" 60 "EPBM_a060_maxCycles1" 59 "EPBM_a059_battMismatch" 58 "EPBM_a058_5vLost" 57 "EPBM_a057_12vUv" 56 "EPBM_a056_12vOv" 55 "EPBM_a055_stackOverflow" 54 "EPBM_a054_unused" 53 "EPBM_a053_unused" 52 "EPBM_a052_leftPVoltageHigh" 51 "EPBM_a051_leftNVoltageLow" 50 "EPBM_a050_mcuMIA" 49 "EPBM_a049_espMIA" 48 "EPBM_a048_chgMIA" 47 "EPBM_a047_epbMIA" 46 "EPBM_a046_sccmMIA" 45 "EPBM_a045_gtwMIA" 44 "EPBM_a044_diMIA" 43 "EPBM_a043_absMIA" 42 "EPBM_a042_spiRead" 41 "EPBM_a041_spiOpen" 40 "EPBM_a040_memoryError" 39 "EPBM_a039_watchdogReset" 38 "EPBM_a038_eeprom" 37 "EPBM_a037_firmware" 36 "EPBM_a036_canOverrun" 35 "EPBM_a035_canErr" 34 "EPBM_a034_canData" 33 "EPBM_a033_canHardware" 32 "EPBM_a032_reqStateErr" 31 "EPBM_a031_stateErr" 30 "EPBM_a030_interProcSpi" 29 "EPBM_a029_canDisabled" 28 "EPBM_a028_noCurrentCalL" 27 "EPBM_a027_spuriousEncIntL" 26 "EPBM_a026_leftUnderRelease" 25 "EPBM_a025_leftOverRelease" 24 "EPBM_a024_leftUnderApply" 23 "EPBM_a023_leftOverApply" 22 "EPBM_a022_leftSubstateErr" 21 "EPBM_a021_leftPvUv" 20 "EPBM_a020_leftPvOv" 19 "EPBM_a019_leftNvUv" 18 "EPBM_a018_leftNvOv" 17 "EPBM_a017_leftNHalfBridge" 16 "EPBM_a016_leftPHalfBridge" 15 "EPBM_a015_leftDriveDuration" 14 "EPBM_a014_leftEnaStuckLow" 13 "EPBM_a013_leftEnaStuckHigh" 12 "EPBM_a012_leftPOpen" 11 "EPBM_a011_leftNOpen" 10 "EPBM_a010_leftPShort" 9 "EPBM_a009_leftNShort" 8 "EPBM_a008_leftShortApply" 7 "EPBM_a007_leftEndStop" 6 "EPBM_a006_leftUc" 5 "EPBM_a005_leftOc" 4 "EPBM_a004_leftEncoderSna" 3 "EPBM_a003_leftEncIrrational" 2 "EPBM_a002_leftIdleOc" 1 "EPBM_a001_leftEncIntrpt" ;
VAL_ 1463 EPBM_alertType 1 "ALERT_USER" 0 "ALERT_WARNING" ;
VAL_ 1463 EPBM_a013_reqState 7 "EPB_STATE_SNA" 6 "EPB_STATE_SELFPARK" 5 "EPB_STATE_SERVICE" 4 "EPB_STATE_START" 3 "EPB_STATE_HANDBRAKE" 2 "EPB_STATE_PARK" 1 "EPB_STATE_DYNAMIC" 0 "EPB_STATE_OPEN" ;
VAL_ 1463 EPBM_a013_substate 4 "EPB_SUBSTATE_CLR_FAULT" 3 "EPB_SUBSTATE_FAULT" 2 "EPB_SUBSTATE_RELEASING" 1 "EPB_SUBSTATE_APPLYING" 0 "EPB_SUBSTATE_STATIONARY" ;
VAL_ 1463 EPBM_a014_reqState 7 "EPB_STATE_SNA" 6 "EPB_STATE_SELFPARK" 5 "EPB_STATE_SERVICE" 4 "EPB_STATE_START" 3 "EPB_STATE_HANDBRAKE" 2 "EPB_STATE_PARK" 1 "EPB_STATE_DYNAMIC" 0 "EPB_STATE_OPEN" ;
VAL_ 1463 EPBM_a014_substate 4 "EPB_SUBSTATE_CLR_FAULT" 3 "EPB_SUBSTATE_FAULT" 2 "EPB_SUBSTATE_RELEASING" 1 "EPB_SUBSTATE_APPLYING" 0 "EPB_SUBSTATE_STATIONARY" ;
VAL_ 1463 EPBM_a015_state 7 "EPB_STATE_SNA" 6 "EPB_STATE_SELFPARK" 5 "EPB_STATE_SERVICE" 4 "EPB_STATE_START" 3 "EPB_STATE_HANDBRAKE" 2 "EPB_STATE_PARK" 1 "EPB_STATE_DYNAMIC" 0 "EPB_STATE_OPEN" ;
VAL_ 1463 EPBM_a015_reqState 7 "EPB_STATE_SNA" 6 "EPB_STATE_SELFPARK" 5 "EPB_STATE_SERVICE" 4 "EPB_STATE_START" 3 "EPB_STATE_HANDBRAKE" 2 "EPB_STATE_PARK" 1 "EPB_STATE_DYNAMIC" 0 "EPB_STATE_OPEN" ;
VAL_ 1463 EPBM_a015_EPB_substate 4 "EPB_SUBSTATE_CLR_FAULT" 3 "EPB_SUBSTATE_FAULT" 2 "EPB_SUBSTATE_RELEASING" 1 "EPB_SUBSTATE_APPLYING" 0 "EPB_SUBSTATE_STATIONARY" ;
VAL_ 1463 EPBM_a022_substateEPB 4 "EPB_SUBSTATE_CLR_FAULT" 3 "EPB_SUBSTATE_FAULT" 2 "EPB_SUBSTATE_RELEASING" 1 "EPB_SUBSTATE_APPLYING" 0 "EPB_SUBSTATE_STATIONARY" ;
VAL_ 1463 EPBM_a022_substateEPBM 4 "EPBM_SUBSTATE_CTRL_FAULT" 3 "EPBM_SUBSTATE_FAULT" 2 "EPBM_SUBSTATE_RELEASING" 1 "EPBM_SUBSTATE_APPLYING" 0 "EPBM_SUBSTATE_STATIONARY" ;
VAL_ 1463 EPBM_a031_stateEPB 7 "EPB_STATE_SNA" 6 "EPB_STATE_SELFPARK" 5 "EPB_STATE_SERVICE" 4 "EPB_STATE_START" 3 "EPB_STATE_HANDBRAKE" 2 "EPB_STATE_PARK" 1 "EPB_STATE_DYNAMIC" 0 "EPB_STATE_OPEN" ;
VAL_ 1463 EPBM_a031_stateEPBM 7 "EPB_STATE_SNA" 6 "EPB_STATE_SELFPARK" 5 "EPB_STATE_SERVICE" 4 "EPB_STATE_START" 3 "EPB_STATE_HANDBRAKE" 2 "EPB_STATE_PARK" 1 "EPB_STATE_DYNAMIC" 0 "EPB_STATE_OPEN" ;
VAL_ 1463 EPBM_a032_reqStateEPB 7 "EPB_STATE_SNA" 6 "EPB_STATE_SELFPARK" 5 "EPB_STATE_SERVICE" 4 "EPB_STATE_START" 3 "EPB_STATE_HANDBRAKE" 2 "EPB_STATE_PARK" 1 "EPB_STATE_DYNAMIC" 0 "EPB_STATE_OPEN" ;
VAL_ 1463 EPBM_a032_reqStateEPBM 7 "EPB_STATE_SNA" 6 "EPB_STATE_SELFPARK" 5 "EPB_STATE_SERVICE" 4 "EPB_STATE_START" 3 "EPB_STATE_HANDBRAKE" 2 "EPB_STATE_PARK" 1 "EPB_STATE_DYNAMIC" 0 "EPB_STATE_OPEN" ;
VAL_ 1463 EPBM_a034_errorType 8 "DENIED" 7 "BUSY" 6 "NODEBUG" 5 "INVALID" 4 "SEQUENCE" 3 "CHECKSUM" 2 "LENGTH_LONG" 1 "LENGTH_SHORT" 0 "NO_ERROR" ;
VAL_ 1463 EPBM_canErrorType 8 "DENIED" 7 "BUSY" 6 "NODEBUG" 5 "INVALID" 4 "SEQUENCE" 3 "CHECKSUM" 2 "LENGTH_LONG" 1 "LENGTH_SHORT" 0 "NO_ERROR" ;
VAL_ 1463 EPBM_a062_state 7 "EPB_STATE_SNA" 6 "EPB_STATE_SELFPARK" 5 "EPB_STATE_SERVICE" 4 "EPB_STATE_START" 3 "EPB_STATE_HANDBRAKE" 2 "EPB_STATE_PARK" 1 "EPB_STATE_DYNAMIC" 0 "EPB_STATE_OPEN" ;
VAL_ 1463 EPBM_a077_reqState 7 "EPB_STATE_SNA" 6 "EPB_STATE_SELFPARK" 5 "EPB_STATE_SERVICE" 4 "EPB_STATE_START" 3 "EPB_STATE_HANDBRAKE" 2 "EPB_STATE_PARK" 1 "EPB_STATE_DYNAMIC" 0 "EPB_STATE_OPEN" ;
VAL_ 1463 EPBM_a077_substate 4 "EPB_SUBSTATE_CLR_FAULT" 3 "EPB_SUBSTATE_FAULT" 2 "EPB_SUBSTATE_RELEASING" 1 "EPB_SUBSTATE_APPLYING" 0 "EPB_SUBSTATE_STATIONARY" ;
VAL_ 1463 EPBM_a078_reqState 7 "EPB_STATE_SNA" 6 "EPB_STATE_SELFPARK" 5 "EPB_STATE_SERVICE" 4 "EPB_STATE_START" 3 "EPB_STATE_HANDBRAKE" 2 "EPB_STATE_PARK" 1 "EPB_STATE_DYNAMIC" 0 "EPB_STATE_OPEN" ;
VAL_ 1463 EPBM_a078_substate 4 "EPB_SUBSTATE_CLR_FAULT" 3 "EPB_SUBSTATE_FAULT" 2 "EPB_SUBSTATE_RELEASING" 1 "EPB_SUBSTATE_APPLYING" 0 "EPB_SUBSTATE_STATIONARY" ;
VAL_ 1463 EPBM_a079_state 7 "EPB_STATE_SNA" 6 "EPB_STATE_SELFPARK" 5 "EPB_STATE_SERVICE" 4 "EPB_STATE_START" 3 "EPB_STATE_HANDBRAKE" 2 "EPB_STATE_PARK" 1 "EPB_STATE_DYNAMIC" 0 "EPB_STATE_OPEN" ;
VAL_ 1463 EPBM_a079_reqState 7 "EPB_STATE_SNA" 6 "EPB_STATE_SELFPARK" 5 "EPB_STATE_SERVICE" 4 "EPB_STATE_START" 3 "EPB_STATE_HANDBRAKE" 2 "EPB_STATE_PARK" 1 "EPB_STATE_DYNAMIC" 0 "EPB_STATE_OPEN" ;
VAL_ 1463 EPBM_a079_EPB_substate 4 "EPB_SUBSTATE_CLR_FAULT" 3 "EPB_SUBSTATE_FAULT" 2 "EPB_SUBSTATE_RELEASING" 1 "EPB_SUBSTATE_APPLYING" 0 "EPB_SUBSTATE_STATIONARY" ;
VAL_ 1463 EPBM_a086_substateEPB 4 "EPB_SUBSTATE_CLR_FAULT" 3 "EPB_SUBSTATE_FAULT" 2 "EPB_SUBSTATE_RELEASING" 1 "EPB_SUBSTATE_APPLYING" 0 "EPB_SUBSTATE_STATIONARY" ;
VAL_ 1463 EPBM_a086_substateEPBM 4 "EPB_SUBSTATE_CLR_FAULT" 3 "EPB_SUBSTATE_FAULT" 2 "EPB_SUBSTATE_RELEASING" 1 "EPB_SUBSTATE_APPLYING" 0 "EPB_SUBSTATE_STATIONARY" ;
VAL_ 1463 EPBM_a096_selfParkAbortReason 22 "EPBM_SELFPARKFAULT_PM_MISMATCH" 21 "EPBM_SELFPARKFAULT_CALIBRATION" 20 "EPBM_SELFPARKFAULT_DI_STATE_INVALID" 19 "EPBM_SELFPARKFAULT_EPB_FAULT" 18 "EPBM_SELFPARKFAULT_MISMATCH" 17 "EPBM_SELFPARKFAULT_OOC" 16 "EPBM_SELFPARKFAULT_PM_REQUEST" 15 "EPBM_SELFPARKFAULT_PM_MIA" 14 "EPBM_SELFPARKFAULT_PARK_MIA" 13 "EPBM_SELFPARKFAULT_EXTERNAL" 12 "EPBM_SELFPARKFAULT_SPEED" 11 "EPBM_SELFPARKFAULT_EPBM_REQUEST" 10 "EPBM_SELFPARKFAULT_EAC_NOT_ALLOWED" 9 "EPBM_SELFPARKFAULT_CH_CAN_FAULT" 8 "EPBM_SELFPARKFAULT_ESP_FAULT" 7 "EPBM_SELFPARKFAULT_DAS_FAULT" 6 "EPBM_SELFPARKFAULT_DI_APC_FAULT" 5 "EPBM_SELFPARKFAULT_DI_FAULT" 4 "EPBM_SELFPARKFAULT_EPB_MIA" 3 "EPBM_SELFPARKFAULT_ESP_MIA" 2 "EPBM_SELFPARKFAULT_DAS_MIA" 1 "EPBM_SELFPARKFAULT_DI_MIA" 0 "EPBM_SELFPARKFAULT_NONE" ;
VAL_ 1463 EPBM_a106_alertID 128 "EPBM_a128_unused" 127 "EPBM_a127_unused" 126 "EPBM_a126_unused" 125 "EPBM_a125_unused" 124 "EPBM_a124_unused" 123 "EPBM_a123_unused" 122 "EPBM_a122_unused" 121 "EPBM_a121_unused" 120 "EPBM_a120_unused" 119 "EPBM_a119_unused" 118 "EPBM_a118_unused" 117 "EPBM_a117_usedFallbackValues" 116 "EPBM_a116_rightPVoltageHigh" 115 "EPBM_a115_rightNVoltageLow" 114 "EPBM_a114_unparkNotAllowed" 113 "EPBM_a113_calFaultRight" 112 "EPBM_a112_calFaultLeft" 111 "EPBM_a111_calWarningRight" 110 "EPBM_a110_calWarningLeft" 109 "EPBM_a109_unused" 108 "EPBM_a108_unused" 107 "EPBM_a107_currentWarning" 106 "EPBM_a106_voltageWarning" 105 "EPBM_a105_epbWentToSleep" 104 "EPBM_a104_epbStillAsleep" 103 "EPBM_a103_targetNotReachedR" 102 "EPBM_a102_targetNotReachedL" 101 "EPBM_a101_calibrationFault" 100 "EPBM_a100_calibrationWarning" 99 "EPBM_a099_unused" 98 "EPBM_a098_pmMia" 97 "EPBM_a097_parkMia" 96 "EPBM_a096_selfParkAborted" 95 "EPBM_a095_invalidConfig" 94 "EPBM_a094_unused" 93 "EPBM_a093_dasMIA" 92 "EPBM_a092_noCurrentCalR" 91 "EPBM_a091_spuriousEncIntR" 90 "EPBM_a090_rightUnderRelease" 89 "EPBM_a089_rightOverRelease" 88 "EPBM_a088_rightUnderApply" 87 "EPBM_a087_rightOverApply" 86 "EPBM_a086_rightSubstateErr" 85 "EPBM_a085_rightPvUv" 84 "EPBM_a084_rightPvOv" 83 "EPBM_a083_rightNvUv" 82 "EPBM_a082_rightNvOv" 81 "EPBM_a081_rightNHalfBridge" 80 "EPBM_a080_rightPHalfBridge" 79 "EPBM_a079_rightDriveDuration" 78 "EPBM_a078_rightEnaStuckLow" 77 "EPBM_a077_rightEnaStuckHigh" 76 "EPBM_a076_rightPOpen" 75 "EPBM_a075_rightNOpen" 74 "EPBM_a074_rightPShort" 73 "EPBM_a073_rightNShort" 72 "EPBM_a072_rightShortApply" 71 "EPBM_a071_rightEndStop" 70 "EPBM_a070_rightUc" 69 "EPBM_a069_rightOc" 68 "EPBM_a068_rightEncoderSna" 67 "EPBM_a067_rightEncIrrational" 66 "EPBM_a066_rightIdleOc" 65 "EPBM_a065_rightEncIntrpt" 64 "EPBM_a064_unused" 63 "EPBM_a063_unused" 62 "EPBM_a062_diGearInvld" 61 "EPBM_a061_maxCycles2" 60 "EPBM_a060_maxCycles1" 59 "EPBM_a059_battMismatch" 58 "EPBM_a058_5vLost" 57 "EPBM_a057_12vUv" 56 "EPBM_a056_12vOv" 55 "EPBM_a055_stackOverflow" 54 "EPBM_a054_unused" 53 "EPBM_a053_unused" 52 "EPBM_a052_leftPVoltageHigh" 51 "EPBM_a051_leftNVoltageLow" 50 "EPBM_a050_mcuMIA" 49 "EPBM_a049_espMIA" 48 "EPBM_a048_chgMIA" 47 "EPBM_a047_epbMIA" 46 "EPBM_a046_sccmMIA" 45 "EPBM_a045_gtwMIA" 44 "EPBM_a044_diMIA" 43 "EPBM_a043_absMIA" 42 "EPBM_a042_spiRead" 41 "EPBM_a041_spiOpen" 40 "EPBM_a040_memoryError" 39 "EPBM_a039_watchdogReset" 38 "EPBM_a038_eeprom" 37 "EPBM_a037_firmware" 36 "EPBM_a036_canOverrun" 35 "EPBM_a035_canErr" 34 "EPBM_a034_canData" 33 "EPBM_a033_canHardware" 32 "EPBM_a032_reqStateErr" 31 "EPBM_a031_stateErr" 30 "EPBM_a030_interProcSpi" 29 "EPBM_a029_canDisabled" 28 "EPBM_a028_noCurrentCalL" 27 "EPBM_a027_spuriousEncIntL" 26 "EPBM_a026_leftUnderRelease" 25 "EPBM_a025_leftOverRelease" 24 "EPBM_a024_leftUnderApply" 23 "EPBM_a023_leftOverApply" 22 "EPBM_a022_leftSubstateErr" 21 "EPBM_a021_leftPvUv" 20 "EPBM_a020_leftPvOv" 19 "EPBM_a019_leftNvUv" 18 "EPBM_a018_leftNvOv" 17 "EPBM_a017_leftNHalfBridge" 16 "EPBM_a016_leftPHalfBridge" 15 "EPBM_a015_leftDriveDuration" 14 "EPBM_a014_leftEnaStuckLow" 13 "EPBM_a013_leftEnaStuckHigh" 12 "EPBM_a012_leftPOpen" 11 "EPBM_a011_leftNOpen" 10 "EPBM_a010_leftPShort" 9 "EPBM_a009_leftNShort" 8 "EPBM_a008_leftShortApply" 7 "EPBM_a007_leftEndStop" 6 "EPBM_a006_leftUc" 5 "EPBM_a005_leftOc" 4 "EPBM_a004_leftEncoderSna" 3 "EPBM_a003_leftEncIrrational" 2 "EPBM_a002_leftIdleOc" 1 "EPBM_a001_leftEncIntrpt" ;
VAL_ 1463 EPBM_a106_motorSel 1 "RIGHT" 0 "LEFT" ;
VAL_ 1463 EPBM_a107_alertID 128 "EPBM_a128_unused" 127 "EPBM_a127_unused" 126 "EPBM_a126_unused" 125 "EPBM_a125_unused" 124 "EPBM_a124_unused" 123 "EPBM_a123_unused" 122 "EPBM_a122_unused" 121 "EPBM_a121_unused" 120 "EPBM_a120_unused" 119 "EPBM_a119_unused" 118 "EPBM_a118_unused" 117 "EPBM_a117_usedFallbackValues" 116 "EPBM_a116_rightPVoltageHigh" 115 "EPBM_a115_rightNVoltageLow" 114 "EPBM_a114_unparkNotAllowed" 113 "EPBM_a113_calFaultRight" 112 "EPBM_a112_calFaultLeft" 111 "EPBM_a111_calWarningRight" 110 "EPBM_a110_calWarningLeft" 109 "EPBM_a109_unused" 108 "EPBM_a108_unused" 107 "EPBM_a107_currentWarning" 106 "EPBM_a106_voltageWarning" 105 "EPBM_a105_epbWentToSleep" 104 "EPBM_a104_epbStillAsleep" 103 "EPBM_a103_targetNotReachedR" 102 "EPBM_a102_targetNotReachedL" 101 "EPBM_a101_calibrationFault" 100 "EPBM_a100_calibrationWarning" 99 "EPBM_a099_unused" 98 "EPBM_a098_pmMia" 97 "EPBM_a097_parkMia" 96 "EPBM_a096_selfParkAborted" 95 "EPBM_a095_invalidConfig" 94 "EPBM_a094_unused" 93 "EPBM_a093_dasMIA" 92 "EPBM_a092_noCurrentCalR" 91 "EPBM_a091_spuriousEncIntR" 90 "EPBM_a090_rightUnderRelease" 89 "EPBM_a089_rightOverRelease" 88 "EPBM_a088_rightUnderApply" 87 "EPBM_a087_rightOverApply" 86 "EPBM_a086_rightSubstateErr" 85 "EPBM_a085_rightPvUv" 84 "EPBM_a084_rightPvOv" 83 "EPBM_a083_rightNvUv" 82 "EPBM_a082_rightNvOv" 81 "EPBM_a081_rightNHalfBridge" 80 "EPBM_a080_rightPHalfBridge" 79 "EPBM_a079_rightDriveDuration" 78 "EPBM_a078_rightEnaStuckLow" 77 "EPBM_a077_rightEnaStuckHigh" 76 "EPBM_a076_rightPOpen" 75 "EPBM_a075_rightNOpen" 74 "EPBM_a074_rightPShort" 73 "EPBM_a073_rightNShort" 72 "EPBM_a072_rightShortApply" 71 "EPBM_a071_rightEndStop" 70 "EPBM_a070_rightUc" 69 "EPBM_a069_rightOc" 68 "EPBM_a068_rightEncoderSna" 67 "EPBM_a067_rightEncIrrational" 66 "EPBM_a066_rightIdleOc" 65 "EPBM_a065_rightEncIntrpt" 64 "EPBM_a064_unused" 63 "EPBM_a063_unused" 62 "EPBM_a062_diGearInvld" 61 "EPBM_a061_maxCycles2" 60 "EPBM_a060_maxCycles1" 59 "EPBM_a059_battMismatch" 58 "EPBM_a058_5vLost" 57 "EPBM_a057_12vUv" 56 "EPBM_a056_12vOv" 55 "EPBM_a055_stackOverflow" 54 "EPBM_a054_unused" 53 "EPBM_a053_unused" 52 "EPBM_a052_leftPVoltageHigh" 51 "EPBM_a051_leftNVoltageLow" 50 "EPBM_a050_mcuMIA" 49 "EPBM_a049_espMIA" 48 "EPBM_a048_chgMIA" 47 "EPBM_a047_epbMIA" 46 "EPBM_a046_sccmMIA" 45 "EPBM_a045_gtwMIA" 44 "EPBM_a044_diMIA" 43 "EPBM_a043_absMIA" 42 "EPBM_a042_spiRead" 41 "EPBM_a041_spiOpen" 40 "EPBM_a040_memoryError" 39 "EPBM_a039_watchdogReset" 38 "EPBM_a038_eeprom" 37 "EPBM_a037_firmware" 36 "EPBM_a036_canOverrun" 35 "EPBM_a035_canErr" 34 "EPBM_a034_canData" 33 "EPBM_a033_canHardware" 32 "EPBM_a032_reqStateErr" 31 "EPBM_a031_stateErr" 30 "EPBM_a030_interProcSpi" 29 "EPBM_a029_canDisabled" 28 "EPBM_a028_noCurrentCalL" 27 "EPBM_a027_spuriousEncIntL" 26 "EPBM_a026_leftUnderRelease" 25 "EPBM_a025_leftOverRelease" 24 "EPBM_a024_leftUnderApply" 23 "EPBM_a023_leftOverApply" 22 "EPBM_a022_leftSubstateErr" 21 "EPBM_a021_leftPvUv" 20 "EPBM_a020_leftPvOv" 19 "EPBM_a019_leftNvUv" 18 "EPBM_a018_leftNvOv" 17 "EPBM_a017_leftNHalfBridge" 16 "EPBM_a016_leftPHalfBridge" 15 "EPBM_a015_leftDriveDuration" 14 "EPBM_a014_leftEnaStuckLow" 13 "EPBM_a013_leftEnaStuckHigh" 12 "EPBM_a012_leftPOpen" 11 "EPBM_a011_leftNOpen" 10 "EPBM_a010_leftPShort" 9 "EPBM_a009_leftNShort" 8 "EPBM_a008_leftShortApply" 7 "EPBM_a007_leftEndStop" 6 "EPBM_a006_leftUc" 5 "EPBM_a005_leftOc" 4 "EPBM_a004_leftEncoderSna" 3 "EPBM_a003_leftEncIrrational" 2 "EPBM_a002_leftIdleOc" 1 "EPBM_a001_leftEncIntrpt" ;
VAL_ 1463 EPBM_a107_motorSel 1 "RIGHT" 0 "LEFT" ;
VAL_ 1463 EPBM_a110_offsetApplied 2 "EPB_OFFSET_RELEASE" 1 "EPB_OFFSET_DYNAMIC" 0 "EPB_OFFSET_STATIC" ;
VAL_ 1463 EPBM_a111_offsetApplied 2 "EPB_OFFSET_RELEASE" 1 "EPB_OFFSET_DYNAMIC" 0 "EPB_OFFSET_STATIC" ;
VAL_ 1463 EPBM_a112_offsetApplied 2 "EPB_OFFSET_RELEASE" 1 "EPB_OFFSET_DYNAMIC" 0 "EPB_OFFSET_STATIC" ;
VAL_ 1463 EPBM_a113_offsetApplied 2 "EPB_OFFSET_RELEASE" 1 "EPB_OFFSET_DYNAMIC" 0 "EPB_OFFSET_STATIC" ;
VAL_ 1463 EPBM_a114_pendingState 7 "EPB_STATE_SNA" 6 "EPB_STATE_SELFPARK" 5 "EPB_STATE_SERVICE" 4 "EPB_STATE_START" 3 "EPB_STATE_HANDBRAKE" 2 "EPB_STATE_PARK" 1 "EPB_STATE_DYNAMIC" 0 "EPB_STATE_OPEN" ;
VAL_ 1463 EPBM_a117_brakeHwType_CAN 2 "BRAKE_HW_TYPE_MANDO" 1 "BRAKE_HW_TYPE_BREMBO_STANDALONE" 0 "BRAKE_HW_TYPE_NONE" ;
VAL_ 1463 EPBM_a117_brakeHwType_EPB 2 "BRAKE_HW_TYPE_MANDO" 1 "BRAKE_HW_TYPE_BREMBO_STANDALONE" 0 "BRAKE_HW_TYPE_NONE" ;
VAL_ 1047 EPBM_nmKeepAwakeReason 1 "EPBM_KEEPAWAKE_REASON_NOT_SECURE" 0 "EPBM_KEEPAWAKE_REASON_NONE_SNA" ;
VAL_ 1815 EPBM_debugOutput 9 "EPB_DEBUG_9" 8 "EPB_DEBUG_8" 7 "EPB_DEBUG_7" 6 "EPB_DEBUG_6" 5 "EPB_DEBUG_5" 4 "EPB_DEBUG_4" 3 "EPB_DEBUG_3" 2 "EPB_DEBUG_2" 1 "EPB_DEBUG_1" 0 "EPB_DEBUG_0" ;
VAL_ 1815 EPBM_CAN_brakeHwType 2 "BRAKE_HW_TYPE_MANDO" 1 "BRAKE_HW_TYPE_BREMBO_STANDALONE" 0 "BRAKE_HW_TYPE_NONE" ;
VAL_ 1815 EPBM_EPB_brakeHwType 2 "BRAKE_HW_TYPE_MANDO" 1 "BRAKE_HW_TYPE_BREMBO_STANDALONE" 0 "BRAKE_HW_TYPE_NONE" ;
VAL_ 1815 EPBM_CAN_chassisType 3 "EPB_CHASSIS_TYPE_NONE" 1 "EPB_CHASSIS_TYPE_X" 0 "EPB_CHASSIS_TYPE_S" ;
VAL_ 1815 EPBM_EPB_chassisType 3 "EPB_CHASSIS_TYPE_NONE" 1 "EPB_CHASSIS_TYPE_X" 0 "EPB_CHASSIS_TYPE_S" ;
VAL_ 1815 EPBM_selfParkFaultReason 22 "EPBM_SELFPARKFAULT_PM_MISMATCH" 21 "EPBM_SELFPARKFAULT_CALIBRATION" 20 "EPBM_SELFPARKFAULT_DI_STATE_INVALID" 19 "EPBM_SELFPARKFAULT_EPB_FAULT" 18 "EPBM_SELFPARKFAULT_MISMATCH" 17 "EPBM_SELFPARKFAULT_OOC" 16 "EPBM_SELFPARKFAULT_PM_REQUEST" 15 "EPBM_SELFPARKFAULT_PM_MIA" 14 "EPBM_SELFPARKFAULT_PARK_MIA" 13 "EPBM_SELFPARKFAULT_EXTERNAL" 12 "EPBM_SELFPARKFAULT_SPEED" 11 "EPBM_SELFPARKFAULT_EPBM_REQUEST" 10 "EPBM_SELFPARKFAULT_EAC_NOT_ALLOWED" 9 "EPBM_SELFPARKFAULT_CH_CAN_FAULT" 8 "EPBM_SELFPARKFAULT_ESP_FAULT" 7 "EPBM_SELFPARKFAULT_DAS_FAULT" 6 "EPBM_SELFPARKFAULT_DI_APC_FAULT" 5 "EPBM_SELFPARKFAULT_DI_FAULT" 4 "EPBM_SELFPARKFAULT_EPB_MIA" 3 "EPBM_SELFPARKFAULT_ESP_MIA" 2 "EPBM_SELFPARKFAULT_DAS_MIA" 1 "EPBM_SELFPARKFAULT_DI_MIA" 0 "EPBM_SELFPARKFAULT_NONE" ;
VAL_ 1815 EPBM_nmState 6 "EPB_NM_STATE_NUM" 5 "EPB_NM_STATE_WAKEUP" 4 "EPB_NM_STATE_SLEEP" 3 "EPB_NM_STATE_QUIESCE" 2 "EPB_NM_STATE_GOING_TO_SLEEP" 1 "EPB_NM_STATE_AWAKE" 0 "EPB_NM_STATE_INIT" ;
VAL_ 1815 EPBM_offsetApplied 2 "EPB_OFFSET_RELEASE" 1 "EPB_OFFSET_DYNAMIC" 0 "EPB_OFFSET_STATIC" ;
VAL_ 1831 EPBM_debugOutput2 9 "EPB_DEBUG_9" 8 "EPB_DEBUG_8" 7 "EPB_DEBUG_7" 6 "EPB_DEBUG_6" 5 "EPB_DEBUG_5" 4 "EPB_DEBUG_4" 3 "EPB_DEBUG_3" 2 "EPB_DEBUG_2" 1 "EPB_DEBUG_1" 0 "EPB_DEBUG_0" ;
VAL_ 1335 EPBM_infoIndex 255 "INFO_END" 20 "INFO_UDS_PROTOCOL_BOOTCRC" 19 "INFO_VERSION_DEPRECATED" 18 "INFO_BOOTLOADER_GITHASH" 17 "INFO_APP_GITHASH" 16 "INFO_SUBCOMPONENT" 15 "INFO_BOOTLOADER_CRC" 14 "INFO_BOOTLOADER_SVN" 13 "INFO_APP_CRC" 11 "INFO_PCBAID_ASSYID_USAGEID" 10 "INFO_BUILD_HWID_COMPONENTID" 9 "INFO_DEPRECATED_9" 8 "INFO_DEPRECATED_8" 7 "INFO_DEPRECATED_7" 6 "INFO_DEPRECATED_6" 5 "INFO_DEPRECATED_5" 4 "INFO_DEPRECATED_4" 3 "INFO_DEPRECATED_3" 2 "INFO_DEPRECATED_2" 1 "INFO_DEPRECATED_1" 0 "INFO_DEPRECATED_0" ;
VAL_ 1335 EPBM_infoHardwareRevision 252 "CONFIGURABLE_HWID_PLACEHOLDER" ;
VAL_ 551 EPBM_state 7 "EPB_STATE_SNA" 6 "EPB_STATE_SELFPARK" 5 "EPB_STATE_SERVICE" 4 "EPB_STATE_START" 3 "EPB_STATE_HANDBRAKE" 2 "EPB_STATE_PARK" 1 "EPB_STATE_DYNAMIC" 0 "EPB_STATE_OPEN" ;
VAL_ 551 EPBM_stateRequest 7 "EPB_STATE_SNA" 6 "EPB_STATE_SELFPARK" 5 "EPB_STATE_SERVICE" 4 "EPB_STATE_START" 3 "EPB_STATE_HANDBRAKE" 2 "EPB_STATE_PARK" 1 "EPB_STATE_DYNAMIC" 0 "EPB_STATE_OPEN" ;
VAL_ 551 EPBM_substateL 4 "EPBM_SUBSTATE_CTRL_FAULT" 3 "EPBM_SUBSTATE_FAULT" 2 "EPBM_SUBSTATE_RELEASING" 1 "EPBM_SUBSTATE_APPLYING" 0 "EPBM_SUBSTATE_STATIONARY" ;
VAL_ 551 EPBM_substateR 4 "EPBM_SUBSTATE_CTRL_FAULT" 3 "EPBM_SUBSTATE_FAULT" 2 "EPBM_SUBSTATE_RELEASING" 1 "EPBM_SUBSTATE_APPLYING" 0 "EPBM_SUBSTATE_STATIONARY" ;
VAL_ 551 EPBM_statePending 7 "EPB_STATE_SNA" 6 "EPB_STATE_SELFPARK" 5 "EPB_STATE_SERVICE" 4 "EPB_STATE_START" 3 "EPB_STATE_HANDBRAKE" 2 "EPB_STATE_PARK" 1 "EPB_STATE_DYNAMIC" 0 "EPB_STATE_OPEN" ;
VAL_ 551 EPBM_selfParkState 5 "SELFPARK_FAULT" 4 "SELFPARK_COMPLETE" 3 "SELFPARK_ACTIVE" 2 "SELFPARK_ARMED" 1 "SELFPARK_IDLE" 0 "SELFPARK_INIT" ;
VAL_ 551 EPBM_syncState 3 "EPB_SYNCSTATE_READY" 2 "EPB_SYNCSTATE_SYNCING" 1 "EPB_SYNCSTATE_LOSTSYNC" 0 "EPB_SYNCSTATE_INIT" ;
VAL_ 551 EPBM_calibrationStateLeft 4 "CAL_BUSY" 3 "CAL_FAULT" 2 "CAL_WARN" 1 "CAL_NORMAL" 0 "CAL_UNAVAILABLE" ;
VAL_ 551 EPBM_calibrationStateRight 4 "CAL_BUSY" 3 "CAL_FAULT" 2 "CAL_WARN" 1 "CAL_NORMAL" 0 "CAL_UNAVAILABLE" ;
VAL_ 551 EPBM_clampCurrentMonitor 3 "CURRENT_TARGET_NOT_REACHED" 2 "CURRENT_TARGET_REACHED" 0 "CURRENT_MONITOR_IDLE" ;
VAL_ 551 EPBM_freeRollingModeStatus 2 "EPB_FREE_ROLLING_MODE_ENABLED" 1 "EPB_FREE_ROLLING_MODE_AVAILABLE" 0 "EPB_FREE_ROLLING_MODE_UNAVAILABLE" ;
VAL_ 1476 EPB_alertID 8204 "EPB_u012_mcuParkUnavailable" 8203 "EPB_u011_parkSlope" 8202 "EPB_u010_serviceModeEnabled" 8201 "EPB_u009_towModeEnabled" 8200 "EPB_u008_turnOnCarToPark" 8199 "EPB_u007_dynNotApplied" 8198 "EPB_u006_epbNotReleased" 8197 "EPB_u005_epbProblem" 8196 "EPB_u004_pressFootBrake" 8195 "EPB_u003_dynamicBrakeApplied" 8194 "EPB_u002_carMayRoll" 8193 "EPB_u001_calibrationRequired" 192 "EPB_a192_unused" 191 "EPB_a191_unused" 190 "EPB_a190_unused" 189 "EPB_a189_unused" 188 "EPB_a188_unused" 187 "EPB_a187_unused" 186 "EPB_a186_unused" 185 "EPB_a185_unused" 184 "EPB_a184_unused" 183 "EPB_a183_unused" 182 "EPB_a182_unused" 181 "EPB_a181_unused" 180 "EPB_a180_unused" 179 "EPB_a179_unused" 178 "EPB_a178_unused" 177 "EPB_a177_unused" 176 "EPB_a176_unused" 175 "EPB_a175_unused" 174 "EPB_a174_unused" 173 "EPB_a173_unused" 172 "EPB_a172_unused" 171 "EPB_a171_unused" 170 "EPB_a170_unused" 169 "EPB_a169_unused" 168 "EPB_a168_unused" 167 "EPB_a167_unused" 166 "EPB_a166_unused" 165 "EPB_a165_unused" 164 "EPB_a164_unused" 163 "EPB_a163_unused" 162 "EPB_a162_unused" 161 "EPB_a161_unused" 160 "EPB_a160_unused" 159 "EPB_a159_unused" 158 "EPB_a158_unused" 157 "EPB_a157_unused" 156 "EPB_a156_unused" 155 "EPB_a155_unused" 154 "EPB_a154_unused" 153 "EPB_a153_unused" 152 "EPB_a152_unused" 151 "EPB_a151_unused" 150 "EPB_a150_unused" 149 "EPB_a149_unused" 148 "EPB_a148_unused" 147 "EPB_a147_unused" 146 "EPB_a146_unused" 145 "EPB_a145_unused" 144 "EPB_a144_unused" 143 "EPB_a143_unused" 142 "EPB_a142_unused" 141 "EPB_a141_unused" 140 "EPB_a140_unused" 139 "EPB_a139_unused" 138 "EPB_a138_unused" 137 "EPB_a137_unused" 136 "EPB_a136_unused" 135 "EPB_a135_unused" 134 "EPB_a134_unused" 133 "EPB_a133_unused" 132 "EPB_a132_unused" 131 "EPB_a131_unused" 130 "EPB_a130_unused" 129 "EPB_a129_unparkNotAllowed" 128 "EPB_a128_followedDiToPark" 127 "EPB_a127_oocSpeedViolation" 126 "EPB_a126_ShortApplyUF" 125 "EPB_a125_gradeTooSteep" 124 "EPB_a124_releaseDistanceR" 123 "EPB_a123_releaseDistanceL" 122 "EPB_a122_freeRollMdEpbmMismatch" 121 "EPB_a121_releaseLogR" 120 "EPB_a120_releaseLogL" 119 "EPB_a119_freeRollingModeAborted" 118 "EPB_a118_freeRollingModeActive" 117 "EPB_a117_usedFallbackValues" 116 "EPB_a116_unableToCalcGrade" 115 "EPB_a115_currentWarning" 114 "EPB_a114_voltageWarning" 113 "EPB_a113_calFaultRight" 112 "EPB_a112_calFaultLeft" 111 "EPB_a111_calWarningRight" 110 "EPB_a110_calWarningLeft" 109 "EPB_a109_rightPVoltageHigh" 108 "EPB_a108_rightNVoltageLow" 107 "EPB_a107_leftPVoltageHigh" 106 "EPB_a106_leftNVoltageLow" 105 "EPB_a105_epbmWentToSleep" 104 "EPB_a104_epbmStillAsleep" 103 "EPB_a103_eepromUpdated" 102 "EPB_a102_eepromCorrupt" 101 "EPB_a101_calibrationFault" 100 "EPB_a100_calibrationWarning" 99 "EPB_a099_pmMia" 98 "EPB_a098_parkMia" 97 "EPB_a097_selfParkAborted" 96 "EPB_a096_epasMia" 95 "EPB_a095_invalidConfig" 94 "EPB_a094_inhibitEac" 93 "EPB_a093_dasMIA" 92 "EPB_a092_obsolete" 91 "EPB_a091_spuriousEncIntR" 90 "EPB_a090_noCurrentCalR" 89 "EPB_a089_motorShortedApplyR" 88 "EPB_a088_motorShortedReleaseR" 87 "EPB_a087_rightFirstShortApply" 86 "EPB_a086_rightSubstateErr" 85 "EPB_a085_rightPvUv" 84 "EPB_a084_rightPvOv" 83 "EPB_a083_rightNvUv" 82 "EPB_a082_rightNvOv" 81 "EPB_a081_rightNHalfBridge" 80 "EPB_a080_rightPHalfBridge" 79 "EPB_a079_rightDriveDuration" 78 "EPB_a078_rightEnaStuckLow" 77 "EPB_a077_rightEnaStuckHigh" 76 "EPB_a076_rightPOpen" 75 "EPB_a075_rightNOpen" 74 "EPB_a074_rightPShort" 73 "EPB_a073_rightNShort" 72 "EPB_a072_rightShortApply" 71 "EPB_a071_rightEndStop" 70 "EPB_a070_rightUc" 69 "EPB_a069_rightOc" 68 "EPB_a068_rightEncoderSna" 67 "EPB_a067_rightEncIrrational" 66 "EPB_a066_rightIdleOc" 65 "EPB_a065_rightEncIntrpt" 64 "EPB_a064_EPBMTimeout" 63 "EPB_a063_parkWhlSpeed" 62 "EPB_a062_diGearInvld" 61 "EPB_a061_maxCycles2" 60 "EPB_a060_maxCycles1" 59 "EPB_a059_battMismatch" 58 "EPB_a058_5vLost" 57 "EPB_a057_12vUv" 56 "EPB_a056_12vOv" 55 "EPB_a055_stackOverflow" 54 "EPB_a054_severeShortApply" 53 "EPB_a053_epbNotReleased" 52 "EPB_a052_epbProblem" 51 "EPB_a051_epbNotApplied" 50 "EPB_a050_resetRequired" 49 "EPB_a049_espMIA" 48 "EPB_a048_mcuMIA" 47 "EPB_a047_epbmMIA" 46 "EPB_a046_sccmMIA" 45 "EPB_a045_gtwMIA" 44 "EPB_a044_diMIA" 43 "EPB_a043_absMIA" 42 "EPB_a042_spiRead" 41 "EPB_a041_spiOpen" 40 "EPB_a040_memoryError" 39 "EPB_a039_watchdogReset" 38 "EPB_a038_eeprom" 37 "EPB_a037_firmware" 36 "EPB_a036_canOverrun" 35 "EPB_a035_canErr" 34 "EPB_a034_canData" 33 "EPB_a033_canHardware" 32 "EPB_a032_canDisabled" 31 "EPB_a031_chgMIA" 30 "EPB_a030_interProcSpi" 29 "EPB_a029_stateErr" 28 "EPB_a028_reqStateErr" 27 "EPB_a027_spuriousEncIntL" 26 "EPB_a026_noCurrentCalL" 25 "EPB_a025_motorShortedApplyL" 24 "EPB_a024_motorShortedReleaseL" 23 "EPB_a023_leftFirstShortApply" 22 "EPB_a022_leftSubstateErr" 21 "EPB_a021_leftPvUv" 20 "EPB_a020_leftPvOv" 19 "EPB_a019_leftNvUv" 18 "EPB_a018_leftNvOv" 17 "EPB_a017_leftNHalfBridge" 16 "EPB_a016_leftPHalfBridge" 15 "EPB_a015_leftDriveDuration" 14 "EPB_a014_leftEnaStuckLow" 13 "EPB_a013_leftEnaStuckHigh" 12 "EPB_a012_leftPOpen" 11 "EPB_a011_leftNOpen" 10 "EPB_a010_leftPShort" 9 "EPB_a009_leftNShort" 8 "EPB_a008_leftShortApply" 7 "EPB_a007_leftEndStop" 6 "EPB_a006_leftUc" 5 "EPB_a005_leftOc" 4 "EPB_a004_leftEncoderSna" 3 "EPB_a003_leftEncIrrational" 2 "EPB_a002_leftIdleOc" 1 "EPB_a001_leftEncIntrpt" ;
VAL_ 1476 EPB_alertType 1 "ALERT_USER" 0 "ALERT_WARNING" ;
VAL_ 1476 EPB_a013_reqState 7 "EPB_STATE_SNA" 6 "EPB_STATE_SELFPARK" 5 "EPB_STATE_SERVICE" 4 "EPB_STATE_START" 3 "EPB_STATE_HANDBRAKE" 2 "EPB_STATE_PARK" 1 "EPB_STATE_DYNAMIC" 0 "EPB_STATE_OPEN" ;
VAL_ 1476 EPB_a013_substate 4 "EPB_SUBSTATE_CLR_FAULT" 3 "EPB_SUBSTATE_FAULT" 2 "EPB_SUBSTATE_RELEASING" 1 "EPB_SUBSTATE_APPLYING" 0 "EPB_SUBSTATE_STATIONARY" ;
VAL_ 1476 EPB_a014_reqState 7 "EPB_STATE_SNA" 6 "EPB_STATE_SELFPARK" 5 "EPB_STATE_SERVICE" 4 "EPB_STATE_START" 3 "EPB_STATE_HANDBRAKE" 2 "EPB_STATE_PARK" 1 "EPB_STATE_DYNAMIC" 0 "EPB_STATE_OPEN" ;
VAL_ 1476 EPB_a014_substate 4 "EPB_SUBSTATE_CLR_FAULT" 3 "EPB_SUBSTATE_FAULT" 2 "EPB_SUBSTATE_RELEASING" 1 "EPB_SUBSTATE_APPLYING" 0 "EPB_SUBSTATE_STATIONARY" ;
VAL_ 1476 EPB_a015_state 7 "EPB_STATE_SNA" 6 "EPB_STATE_SELFPARK" 5 "EPB_STATE_SERVICE" 4 "EPB_STATE_START" 3 "EPB_STATE_HANDBRAKE" 2 "EPB_STATE_PARK" 1 "EPB_STATE_DYNAMIC" 0 "EPB_STATE_OPEN" ;
VAL_ 1476 EPB_a015_reqState 7 "EPB_STATE_SNA" 6 "EPB_STATE_SELFPARK" 5 "EPB_STATE_SERVICE" 4 "EPB_STATE_START" 3 "EPB_STATE_HANDBRAKE" 2 "EPB_STATE_PARK" 1 "EPB_STATE_DYNAMIC" 0 "EPB_STATE_OPEN" ;
VAL_ 1476 EPB_a022_EPBsubstate 4 "EPB_SUBSTATE_CLR_FAULT" 3 "EPB_SUBSTATE_FAULT" 2 "EPB_SUBSTATE_RELEASING" 1 "EPB_SUBSTATE_APPLYING" 0 "EPB_SUBSTATE_STATIONARY" ;
VAL_ 1476 EPB_a022_EPBMsubstate 4 "EPBM_SUBSTATE_CTRL_FAULT" 3 "EPBM_SUBSTATE_FAULT" 2 "EPBM_SUBSTATE_RELEASING" 1 "EPBM_SUBSTATE_APPLYING" 0 "EPBM_SUBSTATE_STATIONARY" ;
VAL_ 1476 EPB_a028_EPBreqState 7 "EPB_STATE_SNA" 6 "EPB_STATE_SELFPARK" 5 "EPB_STATE_SERVICE" 4 "EPB_STATE_START" 3 "EPB_STATE_HANDBRAKE" 2 "EPB_STATE_PARK" 1 "EPB_STATE_DYNAMIC" 0 "EPB_STATE_OPEN" ;
VAL_ 1476 EPB_a028_EPBMreqState 7 "EPB_STATE_SNA" 6 "EPB_STATE_SELFPARK" 5 "EPB_STATE_SERVICE" 4 "EPB_STATE_START" 3 "EPB_STATE_HANDBRAKE" 2 "EPB_STATE_PARK" 1 "EPB_STATE_DYNAMIC" 0 "EPB_STATE_OPEN" ;
VAL_ 1476 EPB_a029_EPBstate 7 "EPB_STATE_SNA" 6 "EPB_STATE_SELFPARK" 5 "EPB_STATE_SERVICE" 4 "EPB_STATE_START" 3 "EPB_STATE_HANDBRAKE" 2 "EPB_STATE_PARK" 1 "EPB_STATE_DYNAMIC" 0 "EPB_STATE_OPEN" ;
VAL_ 1476 EPB_a029_EPBMstate 7 "EPB_STATE_SNA" 6 "EPB_STATE_SELFPARK" 5 "EPB_STATE_SERVICE" 4 "EPB_STATE_START" 3 "EPB_STATE_HANDBRAKE" 2 "EPB_STATE_PARK" 1 "EPB_STATE_DYNAMIC" 0 "EPB_STATE_OPEN" ;
VAL_ 1476 EPB_a034_errorType 8 "DENIED" 7 "BUSY" 6 "NODEBUG" 5 "INVALID" 4 "SEQUENCE" 3 "CHECKSUM" 2 "LENGTH_LONG" 1 "LENGTH_SHORT" 0 "NO_ERROR" ;
VAL_ 1476 EPB_canErrorType 8 "DENIED" 7 "BUSY" 6 "NODEBUG" 5 "INVALID" 4 "SEQUENCE" 3 "CHECKSUM" 2 "LENGTH_LONG" 1 "LENGTH_SHORT" 0 "NO_ERROR" ;
VAL_ 1476 EPB_eepromErrorType 4 "EEPROM_ERROR_LOST" 3 "EEPROM_ERROR_CRC" 2 "EEPROM_ERROR_WRITE" 1 "EEPROM_ERROR_READ" 0 "EEPROM_ERROR_OPEN" ;
VAL_ 1476 EPB_a062_state 7 "EPB_STATE_SNA" 6 "EPB_STATE_SELFPARK" 5 "EPB_STATE_SERVICE" 4 "EPB_STATE_START" 3 "EPB_STATE_HANDBRAKE" 2 "EPB_STATE_PARK" 1 "EPB_STATE_DYNAMIC" 0 "EPB_STATE_OPEN" ;
VAL_ 1476 EPB_a077_reqState 7 "EPB_STATE_SNA" 6 "EPB_STATE_SELFPARK" 5 "EPB_STATE_SERVICE" 4 "EPB_STATE_START" 3 "EPB_STATE_HANDBRAKE" 2 "EPB_STATE_PARK" 1 "EPB_STATE_DYNAMIC" 0 "EPB_STATE_OPEN" ;
VAL_ 1476 EPB_a077_substate 4 "EPB_SUBSTATE_CLR_FAULT" 3 "EPB_SUBSTATE_FAULT" 2 "EPB_SUBSTATE_RELEASING" 1 "EPB_SUBSTATE_APPLYING" 0 "EPB_SUBSTATE_STATIONARY" ;
VAL_ 1476 EPB_a078_reqState 7 "EPB_STATE_SNA" 6 "EPB_STATE_SELFPARK" 5 "EPB_STATE_SERVICE" 4 "EPB_STATE_START" 3 "EPB_STATE_HANDBRAKE" 2 "EPB_STATE_PARK" 1 "EPB_STATE_DYNAMIC" 0 "EPB_STATE_OPEN" ;
VAL_ 1476 EPB_a078_substate 4 "EPB_SUBSTATE_CLR_FAULT" 3 "EPB_SUBSTATE_FAULT" 2 "EPB_SUBSTATE_RELEASING" 1 "EPB_SUBSTATE_APPLYING" 0 "EPB_SUBSTATE_STATIONARY" ;
VAL_ 1476 EPB_a079_state 7 "EPB_STATE_SNA" 6 "EPB_STATE_SELFPARK" 5 "EPB_STATE_SERVICE" 4 "EPB_STATE_START" 3 "EPB_STATE_HANDBRAKE" 2 "EPB_STATE_PARK" 1 "EPB_STATE_DYNAMIC" 0 "EPB_STATE_OPEN" ;
VAL_ 1476 EPB_a079_reqState 7 "EPB_STATE_SNA" 6 "EPB_STATE_SELFPARK" 5 "EPB_STATE_SERVICE" 4 "EPB_STATE_START" 3 "EPB_STATE_HANDBRAKE" 2 "EPB_STATE_PARK" 1 "EPB_STATE_DYNAMIC" 0 "EPB_STATE_OPEN" ;
VAL_ 1476 EPB_a086_EPBsubstate 4 "EPB_SUBSTATE_CLR_FAULT" 3 "EPB_SUBSTATE_FAULT" 2 "EPB_SUBSTATE_RELEASING" 1 "EPB_SUBSTATE_APPLYING" 0 "EPB_SUBSTATE_STATIONARY" ;
VAL_ 1476 EPB_a086_EPBMsubstate 4 "EPBM_SUBSTATE_CTRL_FAULT" 3 "EPBM_SUBSTATE_FAULT" 2 "EPBM_SUBSTATE_RELEASING" 1 "EPBM_SUBSTATE_APPLYING" 0 "EPBM_SUBSTATE_STATIONARY" ;
VAL_ 1476 EPB_a094_inhibitEacReason 15 "EPB_EAC_FAULT_ELK_LKA_SEQ" 14 "EPB_EAC_FAULT_SCT_EAC_MISMATCH" 13 "EPB_EAC_FAULT_AC_MISMATCH" 12 "EPB_EAC_FAULT_LSS_MISMATCH" 11 "EPB_EAC_FAULT_DURATION_ELK" 10 "EPB_EAC_FAULT_HYSTERESIS_ELK" 9 "EPB_EAC_CONFIG_MISMATCH" 8 "EPB_EAC_FAULT_EPAS" 7 "EPB_EAC_ANGLE_BOUNDS" 6 "EPB_EAC_FAULT_HYSTERESIS_LKA" 5 "EPB_EAC_FAULT_DURATION_LKA" 4 "EPB_EAC_FAULT_DI_FAULT" 3 "EPB_EAC_FAULT_DI_MIA" 2 "EPB_EAC_FAULT_EPAS_MIA" 1 "EPB_EAC_FAULT_DAS_MIA" 0 "EPB_EAC_FAULT_NONE" ;
VAL_ 1476 EPB_a097_selfParkAbortReason 23 "EPB_SELFPARKFAULT_PM_MISMATCH" 22 "EPB_SELFPARKFAULT_EPAS_NOT_LEARNED" 21 "EPB_SELFPARKFAULT_CALIBRATION" 20 "EPB_SELFPARKFAULT_DI_STATE_INVALID" 19 "EPB_SELFPARKFAULT_EPB_FAULT" 18 "EPB_SELFPARKFAULT_MISMATCH" 17 "EPB_SELFPARKFAULT_OOC" 16 "EPB_SELFPARKFAULT_PM_REQUEST" 15 "EPB_SELFPARKFAULT_PM_MIA" 14 "EPB_SELFPARKFAULT_PARK_MIA" 13 "EPB_SELFPARKFAULT_EXTERNAL" 12 "EPB_SELFPARKFAULT_SPEED" 11 "EPB_SELFPARKFAULT_EPBM_REQUEST" 10 "EPB_SELFPARKFAULT_EAC_NOT_ALLOWED" 9 "EPB_SELFPARKFAULT_CH_CAN_FAULT" 8 "EPB_SELFPARKFAULT_ESP_FAULT" 7 "EPB_SELFPARKFAULT_DAS_FAULT" 6 "EPB_SELFPARKFAULT_DI_APC_FAULT" 5 "EPB_SELFPARKFAULT_DI_FAULT" 4 "EPB_SELFPARKFAULT_EPBM_MIA" 3 "EPB_SELFPARKFAULT_ESP_MIA" 2 "EPB_SELFPARKFAULT_DAS_MIA" 1 "EPB_SELFPARKFAULT_DI_MIA" 0 "EPB_SELFPARKFAULT_NONE" ;
VAL_ 1476 EPB_a103_datatype 5 "EEP_CHASSIS_TYPE_DATATYPE" 4 "EEP_EPAS_TYPE_DATATYPE" 3 "EEP_STATISTICS_DATATYPE" 2 "EEP_BRAKE_HW_TYPE_DATATYPE" 1 "EEP_STATE_DATATYPE" 0 "EEP_NONE_DATATYPE" ;
VAL_ 1476 EPB_a110_offsetApplied 2 "EPB_OFFSET_RELEASE" 1 "EPB_OFFSET_DYNAMIC" 0 "EPB_OFFSET_STATIC" ;
VAL_ 1476 EPB_a111_offsetApplied 2 "EPB_OFFSET_RELEASE" 1 "EPB_OFFSET_DYNAMIC" 0 "EPB_OFFSET_STATIC" ;
VAL_ 1476 EPB_a112_offsetApplied 2 "EPB_OFFSET_RELEASE" 1 "EPB_OFFSET_DYNAMIC" 0 "EPB_OFFSET_STATIC" ;
VAL_ 1476 EPB_a113_offsetApplied 2 "EPB_OFFSET_RELEASE" 1 "EPB_OFFSET_DYNAMIC" 0 "EPB_OFFSET_STATIC" ;
VAL_ 1476 EPB_a114_alertID 8204 "EPB_u012_mcuParkUnavailable" 8203 "EPB_u011_parkSlope" 8202 "EPB_u010_serviceModeEnabled" 8201 "EPB_u009_towModeEnabled" 8200 "EPB_u008_turnOnCarToPark" 8199 "EPB_u007_dynNotApplied" 8198 "EPB_u006_epbNotReleased" 8197 "EPB_u005_epbProblem" 8196 "EPB_u004_pressFootBrake" 8195 "EPB_u003_dynamicBrakeApplied" 8194 "EPB_u002_carMayRoll" 8193 "EPB_u001_calibrationRequired" 192 "EPB_a192_unused" 191 "EPB_a191_unused" 190 "EPB_a190_unused" 189 "EPB_a189_unused" 188 "EPB_a188_unused" 187 "EPB_a187_unused" 186 "EPB_a186_unused" 185 "EPB_a185_unused" 184 "EPB_a184_unused" 183 "EPB_a183_unused" 182 "EPB_a182_unused" 181 "EPB_a181_unused" 180 "EPB_a180_unused" 179 "EPB_a179_unused" 178 "EPB_a178_unused" 177 "EPB_a177_unused" 176 "EPB_a176_unused" 175 "EPB_a175_unused" 174 "EPB_a174_unused" 173 "EPB_a173_unused" 172 "EPB_a172_unused" 171 "EPB_a171_unused" 170 "EPB_a170_unused" 169 "EPB_a169_unused" 168 "EPB_a168_unused" 167 "EPB_a167_unused" 166 "EPB_a166_unused" 165 "EPB_a165_unused" 164 "EPB_a164_unused" 163 "EPB_a163_unused" 162 "EPB_a162_unused" 161 "EPB_a161_unused" 160 "EPB_a160_unused" 159 "EPB_a159_unused" 158 "EPB_a158_unused" 157 "EPB_a157_unused" 156 "EPB_a156_unused" 155 "EPB_a155_unused" 154 "EPB_a154_unused" 153 "EPB_a153_unused" 152 "EPB_a152_unused" 151 "EPB_a151_unused" 150 "EPB_a150_unused" 149 "EPB_a149_unused" 148 "EPB_a148_unused" 147 "EPB_a147_unused" 146 "EPB_a146_unused" 145 "EPB_a145_unused" 144 "EPB_a144_unused" 143 "EPB_a143_unused" 142 "EPB_a142_unused" 141 "EPB_a141_unused" 140 "EPB_a140_unused" 139 "EPB_a139_unused" 138 "EPB_a138_unused" 137 "EPB_a137_unused" 136 "EPB_a136_unused" 135 "EPB_a135_unused" 134 "EPB_a134_unused" 133 "EPB_a133_unused" 132 "EPB_a132_unused" 131 "EPB_a131_unused" 130 "EPB_a130_unused" 129 "EPB_a129_unparkNotAllowed" 128 "EPB_a128_followedDiToPark" 127 "EPB_a127_oocSpeedViolation" 126 "EPB_a126_ShortApplyUF" 125 "EPB_a125_gradeTooSteep" 124 "EPB_a124_releaseDistanceR" 123 "EPB_a123_releaseDistanceL" 122 "EPB_a122_freeRollMdEpbmMismatch" 121 "EPB_a121_releaseLogR" 120 "EPB_a120_releaseLogL" 119 "EPB_a119_freeRollingModeAborted" 118 "EPB_a118_freeRollingModeActive" 117 "EPB_a117_usedFallbackValues" 116 "EPB_a116_unableToCalcGrade" 115 "EPB_a115_currentWarning" 114 "EPB_a114_voltageWarning" 113 "EPB_a113_calFaultRight" 112 "EPB_a112_calFaultLeft" 111 "EPB_a111_calWarningRight" 110 "EPB_a110_calWarningLeft" 109 "EPB_a109_rightPVoltageHigh" 108 "EPB_a108_rightNVoltageLow" 107 "EPB_a107_leftPVoltageHigh" 106 "EPB_a106_leftNVoltageLow" 105 "EPB_a105_epbmWentToSleep" 104 "EPB_a104_epbmStillAsleep" 103 "EPB_a103_eepromUpdated" 102 "EPB_a102_eepromCorrupt" 101 "EPB_a101_calibrationFault" 100 "EPB_a100_calibrationWarning" 99 "EPB_a099_pmMia" 98 "EPB_a098_parkMia" 97 "EPB_a097_selfParkAborted" 96 "EPB_a096_epasMia" 95 "EPB_a095_invalidConfig" 94 "EPB_a094_inhibitEac" 93 "EPB_a093_dasMIA" 92 "EPB_a092_obsolete" 91 "EPB_a091_spuriousEncIntR" 90 "EPB_a090_noCurrentCalR" 89 "EPB_a089_motorShortedApplyR" 88 "EPB_a088_motorShortedReleaseR" 87 "EPB_a087_rightFirstShortApply" 86 "EPB_a086_rightSubstateErr" 85 "EPB_a085_rightPvUv" 84 "EPB_a084_rightPvOv" 83 "EPB_a083_rightNvUv" 82 "EPB_a082_rightNvOv" 81 "EPB_a081_rightNHalfBridge" 80 "EPB_a080_rightPHalfBridge" 79 "EPB_a079_rightDriveDuration" 78 "EPB_a078_rightEnaStuckLow" 77 "EPB_a077_rightEnaStuckHigh" 76 "EPB_a076_rightPOpen" 75 "EPB_a075_rightNOpen" 74 "EPB_a074_rightPShort" 73 "EPB_a073_rightNShort" 72 "EPB_a072_rightShortApply" 71 "EPB_a071_rightEndStop" 70 "EPB_a070_rightUc" 69 "EPB_a069_rightOc" 68 "EPB_a068_rightEncoderSna" 67 "EPB_a067_rightEncIrrational" 66 "EPB_a066_rightIdleOc" 65 "EPB_a065_rightEncIntrpt" 64 "EPB_a064_EPBMTimeout" 63 "EPB_a063_parkWhlSpeed" 62 "EPB_a062_diGearInvld" 61 "EPB_a061_maxCycles2" 60 "EPB_a060_maxCycles1" 59 "EPB_a059_battMismatch" 58 "EPB_a058_5vLost" 57 "EPB_a057_12vUv" 56 "EPB_a056_12vOv" 55 "EPB_a055_stackOverflow" 54 "EPB_a054_severeShortApply" 53 "EPB_a053_epbNotReleased" 52 "EPB_a052_epbProblem" 51 "EPB_a051_epbNotApplied" 50 "EPB_a050_resetRequired" 49 "EPB_a049_espMIA" 48 "EPB_a048_mcuMIA" 47 "EPB_a047_epbmMIA" 46 "EPB_a046_sccmMIA" 45 "EPB_a045_gtwMIA" 44 "EPB_a044_diMIA" 43 "EPB_a043_absMIA" 42 "EPB_a042_spiRead" 41 "EPB_a041_spiOpen" 40 "EPB_a040_memoryError" 39 "EPB_a039_watchdogReset" 38 "EPB_a038_eeprom" 37 "EPB_a037_firmware" 36 "EPB_a036_canOverrun" 35 "EPB_a035_canErr" 34 "EPB_a034_canData" 33 "EPB_a033_canHardware" 32 "EPB_a032_canDisabled" 31 "EPB_a031_chgMIA" 30 "EPB_a030_interProcSpi" 29 "EPB_a029_stateErr" 28 "EPB_a028_reqStateErr" 27 "EPB_a027_spuriousEncIntL" 26 "EPB_a026_noCurrentCalL" 25 "EPB_a025_motorShortedApplyL" 24 "EPB_a024_motorShortedReleaseL" 23 "EPB_a023_leftFirstShortApply" 22 "EPB_a022_leftSubstateErr" 21 "EPB_a021_leftPvUv" 20 "EPB_a020_leftPvOv" 19 "EPB_a019_leftNvUv" 18 "EPB_a018_leftNvOv" 17 "EPB_a017_leftNHalfBridge" 16 "EPB_a016_leftPHalfBridge" 15 "EPB_a015_leftDriveDuration" 14 "EPB_a014_leftEnaStuckLow" 13 "EPB_a013_leftEnaStuckHigh" 12 "EPB_a012_leftPOpen" 11 "EPB_a011_leftNOpen" 10 "EPB_a010_leftPShort" 9 "EPB_a009_leftNShort" 8 "EPB_a008_leftShortApply" 7 "EPB_a007_leftEndStop" 6 "EPB_a006_leftUc" 5 "EPB_a005_leftOc" 4 "EPB_a004_leftEncoderSna" 3 "EPB_a003_leftEncIrrational" 2 "EPB_a002_leftIdleOc" 1 "EPB_a001_leftEncIntrpt" ;
VAL_ 1476 EPB_a114_motorSel 1 "RIGHT" 0 "LEFT" ;
VAL_ 1476 EPB_a115_alertID 8204 "EPB_u012_mcuParkUnavailable" 8203 "EPB_u011_parkSlope" 8202 "EPB_u010_serviceModeEnabled" 8201 "EPB_u009_towModeEnabled" 8200 "EPB_u008_turnOnCarToPark" 8199 "EPB_u007_dynNotApplied" 8198 "EPB_u006_epbNotReleased" 8197 "EPB_u005_epbProblem" 8196 "EPB_u004_pressFootBrake" 8195 "EPB_u003_dynamicBrakeApplied" 8194 "EPB_u002_carMayRoll" 8193 "EPB_u001_calibrationRequired" 192 "EPB_a192_unused" 191 "EPB_a191_unused" 190 "EPB_a190_unused" 189 "EPB_a189_unused" 188 "EPB_a188_unused" 187 "EPB_a187_unused" 186 "EPB_a186_unused" 185 "EPB_a185_unused" 184 "EPB_a184_unused" 183 "EPB_a183_unused" 182 "EPB_a182_unused" 181 "EPB_a181_unused" 180 "EPB_a180_unused" 179 "EPB_a179_unused" 178 "EPB_a178_unused" 177 "EPB_a177_unused" 176 "EPB_a176_unused" 175 "EPB_a175_unused" 174 "EPB_a174_unused" 173 "EPB_a173_unused" 172 "EPB_a172_unused" 171 "EPB_a171_unused" 170 "EPB_a170_unused" 169 "EPB_a169_unused" 168 "EPB_a168_unused" 167 "EPB_a167_unused" 166 "EPB_a166_unused" 165 "EPB_a165_unused" 164 "EPB_a164_unused" 163 "EPB_a163_unused" 162 "EPB_a162_unused" 161 "EPB_a161_unused" 160 "EPB_a160_unused" 159 "EPB_a159_unused" 158 "EPB_a158_unused" 157 "EPB_a157_unused" 156 "EPB_a156_unused" 155 "EPB_a155_unused" 154 "EPB_a154_unused" 153 "EPB_a153_unused" 152 "EPB_a152_unused" 151 "EPB_a151_unused" 150 "EPB_a150_unused" 149 "EPB_a149_unused" 148 "EPB_a148_unused" 147 "EPB_a147_unused" 146 "EPB_a146_unused" 145 "EPB_a145_unused" 144 "EPB_a144_unused" 143 "EPB_a143_unused" 142 "EPB_a142_unused" 141 "EPB_a141_unused" 140 "EPB_a140_unused" 139 "EPB_a139_unused" 138 "EPB_a138_unused" 137 "EPB_a137_unused" 136 "EPB_a136_unused" 135 "EPB_a135_unused" 134 "EPB_a134_unused" 133 "EPB_a133_unused" 132 "EPB_a132_unused" 131 "EPB_a131_unused" 130 "EPB_a130_unused" 129 "EPB_a129_unparkNotAllowed" 128 "EPB_a128_followedDiToPark" 127 "EPB_a127_oocSpeedViolation" 126 "EPB_a126_ShortApplyUF" 125 "EPB_a125_gradeTooSteep" 124 "EPB_a124_releaseDistanceR" 123 "EPB_a123_releaseDistanceL" 122 "EPB_a122_freeRollMdEpbmMismatch" 121 "EPB_a121_releaseLogR" 120 "EPB_a120_releaseLogL" 119 "EPB_a119_freeRollingModeAborted" 118 "EPB_a118_freeRollingModeActive" 117 "EPB_a117_usedFallbackValues" 116 "EPB_a116_unableToCalcGrade" 115 "EPB_a115_currentWarning" 114 "EPB_a114_voltageWarning" 113 "EPB_a113_calFaultRight" 112 "EPB_a112_calFaultLeft" 111 "EPB_a111_calWarningRight" 110 "EPB_a110_calWarningLeft" 109 "EPB_a109_rightPVoltageHigh" 108 "EPB_a108_rightNVoltageLow" 107 "EPB_a107_leftPVoltageHigh" 106 "EPB_a106_leftNVoltageLow" 105 "EPB_a105_epbmWentToSleep" 104 "EPB_a104_epbmStillAsleep" 103 "EPB_a103_eepromUpdated" 102 "EPB_a102_eepromCorrupt" 101 "EPB_a101_calibrationFault" 100 "EPB_a100_calibrationWarning" 99 "EPB_a099_pmMia" 98 "EPB_a098_parkMia" 97 "EPB_a097_selfParkAborted" 96 "EPB_a096_epasMia" 95 "EPB_a095_invalidConfig" 94 "EPB_a094_inhibitEac" 93 "EPB_a093_dasMIA" 92 "EPB_a092_obsolete" 91 "EPB_a091_spuriousEncIntR" 90 "EPB_a090_noCurrentCalR" 89 "EPB_a089_motorShortedApplyR" 88 "EPB_a088_motorShortedReleaseR" 87 "EPB_a087_rightFirstShortApply" 86 "EPB_a086_rightSubstateErr" 85 "EPB_a085_rightPvUv" 84 "EPB_a084_rightPvOv" 83 "EPB_a083_rightNvUv" 82 "EPB_a082_rightNvOv" 81 "EPB_a081_rightNHalfBridge" 80 "EPB_a080_rightPHalfBridge" 79 "EPB_a079_rightDriveDuration" 78 "EPB_a078_rightEnaStuckLow" 77 "EPB_a077_rightEnaStuckHigh" 76 "EPB_a076_rightPOpen" 75 "EPB_a075_rightNOpen" 74 "EPB_a074_rightPShort" 73 "EPB_a073_rightNShort" 72 "EPB_a072_rightShortApply" 71 "EPB_a071_rightEndStop" 70 "EPB_a070_rightUc" 69 "EPB_a069_rightOc" 68 "EPB_a068_rightEncoderSna" 67 "EPB_a067_rightEncIrrational" 66 "EPB_a066_rightIdleOc" 65 "EPB_a065_rightEncIntrpt" 64 "EPB_a064_EPBMTimeout" 63 "EPB_a063_parkWhlSpeed" 62 "EPB_a062_diGearInvld" 61 "EPB_a061_maxCycles2" 60 "EPB_a060_maxCycles1" 59 "EPB_a059_battMismatch" 58 "EPB_a058_5vLost" 57 "EPB_a057_12vUv" 56 "EPB_a056_12vOv" 55 "EPB_a055_stackOverflow" 54 "EPB_a054_severeShortApply" 53 "EPB_a053_epbNotReleased" 52 "EPB_a052_epbProblem" 51 "EPB_a051_epbNotApplied" 50 "EPB_a050_resetRequired" 49 "EPB_a049_espMIA" 48 "EPB_a048_mcuMIA" 47 "EPB_a047_epbmMIA" 46 "EPB_a046_sccmMIA" 45 "EPB_a045_gtwMIA" 44 "EPB_a044_diMIA" 43 "EPB_a043_absMIA" 42 "EPB_a042_spiRead" 41 "EPB_a041_spiOpen" 40 "EPB_a040_memoryError" 39 "EPB_a039_watchdogReset" 38 "EPB_a038_eeprom" 37 "EPB_a037_firmware" 36 "EPB_a036_canOverrun" 35 "EPB_a035_canErr" 34 "EPB_a034_canData" 33 "EPB_a033_canHardware" 32 "EPB_a032_canDisabled" 31 "EPB_a031_chgMIA" 30 "EPB_a030_interProcSpi" 29 "EPB_a029_stateErr" 28 "EPB_a028_reqStateErr" 27 "EPB_a027_spuriousEncIntL" 26 "EPB_a026_noCurrentCalL" 25 "EPB_a025_motorShortedApplyL" 24 "EPB_a024_motorShortedReleaseL" 23 "EPB_a023_leftFirstShortApply" 22 "EPB_a022_leftSubstateErr" 21 "EPB_a021_leftPvUv" 20 "EPB_a020_leftPvOv" 19 "EPB_a019_leftNvUv" 18 "EPB_a018_leftNvOv" 17 "EPB_a017_leftNHalfBridge" 16 "EPB_a016_leftPHalfBridge" 15 "EPB_a015_leftDriveDuration" 14 "EPB_a014_leftEnaStuckLow" 13 "EPB_a013_leftEnaStuckHigh" 12 "EPB_a012_leftPOpen" 11 "EPB_a011_leftNOpen" 10 "EPB_a010_leftPShort" 9 "EPB_a009_leftNShort" 8 "EPB_a008_leftShortApply" 7 "EPB_a007_leftEndStop" 6 "EPB_a006_leftUc" 5 "EPB_a005_leftOc" 4 "EPB_a004_leftEncoderSna" 3 "EPB_a003_leftEncIrrational" 2 "EPB_a002_leftIdleOc" 1 "EPB_a001_leftEncIntrpt" ;
VAL_ 1476 EPB_a115_motorSel 1 "RIGHT" 0 "LEFT" ;
VAL_ 1476 EPB_a117_brakeHwTypeLearnState 2 "HW_LEARN_STATE_WRITE" 1 "HW_LEARN_STATE_STORED" 0 "HW_LEARN_STATE_INIT" ;
VAL_ 1476 EPB_a117_learnedBrakeHwType 2 "BREMBO_P44_MANDO_43MOC" 1 "BREMBO_P40_MANDO_43MOC" 0 "BREMBO_P40_BREMBO_P28_BREMBO_EPB" ;
VAL_ 1476 EPB_a119_DIgear 7 "DI_GEAR_SNA" 4 "DI_GEAR_D" 3 "DI_GEAR_N" 2 "DI_GEAR_R" 1 "DI_GEAR_P" 0 "DI_GEAR_INVALID" ;
VAL_ 1476 EPB_a119_EPBstate 7 "EPB_STATE_SNA" 6 "EPB_STATE_SELFPARK" 5 "EPB_STATE_SERVICE" 4 "EPB_STATE_START" 3 "EPB_STATE_HANDBRAKE" 2 "EPB_STATE_PARK" 1 "EPB_STATE_DYNAMIC" 0 "EPB_STATE_OPEN" ;
VAL_ 1476 EPB_a119_EPBreqState 7 "EPB_STATE_SNA" 6 "EPB_STATE_SELFPARK" 5 "EPB_STATE_SERVICE" 4 "EPB_STATE_START" 3 "EPB_STATE_HANDBRAKE" 2 "EPB_STATE_PARK" 1 "EPB_STATE_DYNAMIC" 0 "EPB_STATE_OPEN" ;
VAL_ 1476 EPB_a119_wheelParkState_FL 3 "NOT_OK_TO_PARK" 2 "OK_TO_PARK" 1 "VEHICLE_STOPPED" 0 "DATA_INVALID" ;
VAL_ 1476 EPB_a119_wheelParkState_FR 3 "NOT_OK_TO_PARK" 2 "OK_TO_PARK" 1 "VEHICLE_STOPPED" 0 "DATA_INVALID" ;
VAL_ 1476 EPB_a119_wheelParkState_RL 3 "NOT_OK_TO_PARK" 2 "OK_TO_PARK" 1 "VEHICLE_STOPPED" 0 "DATA_INVALID" ;
VAL_ 1476 EPB_a119_wheelParkState_RR 3 "NOT_OK_TO_PARK" 2 "OK_TO_PARK" 1 "VEHICLE_STOPPED" 0 "DATA_INVALID" ;
VAL_ 1476 EPB_a120_state 7 "EPB_STATE_SNA" 6 "EPB_STATE_SELFPARK" 5 "EPB_STATE_SERVICE" 4 "EPB_STATE_START" 3 "EPB_STATE_HANDBRAKE" 2 "EPB_STATE_PARK" 1 "EPB_STATE_DYNAMIC" 0 "EPB_STATE_OPEN" ;
VAL_ 1476 EPB_a120_intReqState 8 "EPB_INT_STATE_PARK_TELLTALE" 7 "EPB_INT_STATE_SNA" 6 "EPB_INT_STATE_SELFPARK" 5 "EPB_INT_STATE_SERVICE" 4 "EPB_INT_STATE_START" 3 "EPB_INT_STATE_HANDBRAKE" 2 "EPB_INT_STATE_PARK" 1 "EPB_INT_STATE_DYNAMIC" 0 "EPB_INT_STATE_OPEN" ;
VAL_ 1476 EPB_a121_state 7 "EPB_STATE_SNA" 6 "EPB_STATE_SELFPARK" 5 "EPB_STATE_SERVICE" 4 "EPB_STATE_START" 3 "EPB_STATE_HANDBRAKE" 2 "EPB_STATE_PARK" 1 "EPB_STATE_DYNAMIC" 0 "EPB_STATE_OPEN" ;
VAL_ 1476 EPB_a121_intReqState 8 "EPB_INT_STATE_PARK_TELLTALE" 7 "EPB_INT_STATE_SNA" 6 "EPB_INT_STATE_SELFPARK" 5 "EPB_INT_STATE_SERVICE" 4 "EPB_INT_STATE_START" 3 "EPB_INT_STATE_HANDBRAKE" 2 "EPB_INT_STATE_PARK" 1 "EPB_INT_STATE_DYNAMIC" 0 "EPB_INT_STATE_OPEN" ;
VAL_ 1476 EPB_a128_DIgear 7 "DI_GEAR_SNA" 4 "DI_GEAR_D" 3 "DI_GEAR_N" 2 "DI_GEAR_R" 1 "DI_GEAR_P" 0 "DI_GEAR_INVALID" ;
VAL_ 1476 EPB_a128_EPBstate 7 "EPB_STATE_SNA" 6 "EPB_STATE_SELFPARK" 5 "EPB_STATE_SERVICE" 4 "EPB_STATE_START" 3 "EPB_STATE_HANDBRAKE" 2 "EPB_STATE_PARK" 1 "EPB_STATE_DYNAMIC" 0 "EPB_STATE_OPEN" ;
VAL_ 1476 EPB_a128_EPBreqState 7 "EPB_STATE_SNA" 6 "EPB_STATE_SELFPARK" 5 "EPB_STATE_SERVICE" 4 "EPB_STATE_START" 3 "EPB_STATE_HANDBRAKE" 2 "EPB_STATE_PARK" 1 "EPB_STATE_DYNAMIC" 0 "EPB_STATE_OPEN" ;
VAL_ 1476 EPB_a128_EPBpendingState 7 "EPB_STATE_SNA" 6 "EPB_STATE_SELFPARK" 5 "EPB_STATE_SERVICE" 4 "EPB_STATE_START" 3 "EPB_STATE_HANDBRAKE" 2 "EPB_STATE_PARK" 1 "EPB_STATE_DYNAMIC" 0 "EPB_STATE_OPEN" ;
VAL_ 1476 EPB_a128_EPBsubstateL 4 "EPB_SUBSTATE_CLR_FAULT" 3 "EPB_SUBSTATE_FAULT" 2 "EPB_SUBSTATE_RELEASING" 1 "EPB_SUBSTATE_APPLYING" 0 "EPB_SUBSTATE_STATIONARY" ;
VAL_ 1476 EPB_a128_EPBsubstateR 4 "EPB_SUBSTATE_CLR_FAULT" 3 "EPB_SUBSTATE_FAULT" 2 "EPB_SUBSTATE_RELEASING" 1 "EPB_SUBSTATE_APPLYING" 0 "EPB_SUBSTATE_STATIONARY" ;
VAL_ 1476 EPB_a129_diGear 7 "DI_GEAR_SNA" 4 "DI_GEAR_D" 3 "DI_GEAR_N" 2 "DI_GEAR_R" 1 "DI_GEAR_P" 0 "DI_GEAR_INVALID" ;
VAL_ 1476 EPB_a129_internalPendingState 8 "EPB_INT_STATE_PARK_TELLTALE" 7 "EPB_INT_STATE_SNA" 6 "EPB_INT_STATE_SELFPARK" 5 "EPB_INT_STATE_SERVICE" 4 "EPB_INT_STATE_START" 3 "EPB_INT_STATE_HANDBRAKE" 2 "EPB_INT_STATE_PARK" 1 "EPB_INT_STATE_DYNAMIC" 0 "EPB_INT_STATE_OPEN" ;
VAL_ 1044 EPB_nmKeepAwakeReason 1 "EPB_KEEPAWAKE_REASON_NOT_SECURE" 0 "EPB_KEEPAWAKE_REASON_NONE_SNA" ;
VAL_ 1812 EPB_debugOutput 9 "EPB_DEBUG_9" 8 "EPB_DEBUG_8" 7 "EPB_DEBUG_7" 6 "EPB_DEBUG_6" 5 "EPB_DEBUG_5" 4 "EPB_DEBUG_4" 3 "EPB_DEBUG_3" 2 "EPB_DEBUG_2" 1 "EPB_DEBUG_1" 0 "EPB_DEBUG_0" ;
VAL_ 1812 EPB_learnedBrakeHwType 2 "BREMBO_P44_MANDO_43MOC" 1 "BREMBO_P40_MANDO_43MOC" 0 "BREMBO_P40_BREMBO_P28_BREMBO_EPB" ;
VAL_ 1812 EPB_brakeHwTypeLearnState 2 "HW_LEARN_STATE_WRITE" 1 "HW_LEARN_STATE_STORED" 0 "HW_LEARN_STATE_INIT" ;
VAL_ 1812 EPB_learnedEpasType 4 "MANDO_VGR66_GEN3" 3 "MANDO_VGR66" 2 "MANDO_FGR64" 1 "BOSCH_L405" 0 "BOSCH_L538" ;
VAL_ 1812 EPB_epasTypeLearnState 2 "HW_LEARN_STATE_WRITE" 1 "HW_LEARN_STATE_STORED" 0 "HW_LEARN_STATE_INIT" ;
VAL_ 1812 EPB_CAN_brakeHwType 2 "BRAKE_HW_TYPE_MANDO" 1 "BRAKE_HW_TYPE_BREMBO_STANDALONE" 0 "BRAKE_HW_TYPE_NONE" ;
VAL_ 1812 EPB_learnedChassisType 3 "EPB_CHASSIS_TYPE_NONE" 1 "EPB_CHASSIS_TYPE_X" 0 "EPB_CHASSIS_TYPE_S" ;
VAL_ 1812 EPB_chassisTypeLearnState 2 "HW_LEARN_STATE_WRITE" 1 "HW_LEARN_STATE_STORED" 0 "HW_LEARN_STATE_INIT" ;
VAL_ 1812 EPB_epasEacState 4 "EAC_LATERAL_CTRL_INHIBIT" 3 "EAC_LATERAL_CTRL_AUTOPARK" 2 "EAC_LATERAL_CTRL_CONTINUOUS" 1 "EAC_LATERAL_CTRL_MOMENTARY" 0 "EAC_LATERAL_CTRL_INIT" ;
VAL_ 1812 EPB_internalState 8 "EPB_INT_STATE_PARK_TELLTALE" 7 "EPB_INT_STATE_SNA" 6 "EPB_INT_STATE_SELFPARK" 5 "EPB_INT_STATE_SERVICE" 4 "EPB_INT_STATE_START" 3 "EPB_INT_STATE_HANDBRAKE" 2 "EPB_INT_STATE_PARK" 1 "EPB_INT_STATE_DYNAMIC" 0 "EPB_INT_STATE_OPEN" ;
VAL_ 1812 EPB_internalReqState 8 "EPB_INT_STATE_PARK_TELLTALE" 7 "EPB_INT_STATE_SNA" 6 "EPB_INT_STATE_SELFPARK" 5 "EPB_INT_STATE_SERVICE" 4 "EPB_INT_STATE_START" 3 "EPB_INT_STATE_HANDBRAKE" 2 "EPB_INT_STATE_PARK" 1 "EPB_INT_STATE_DYNAMIC" 0 "EPB_INT_STATE_OPEN" ;
VAL_ 1812 EPB_internalPendingState 8 "EPB_INT_STATE_PARK_TELLTALE" 7 "EPB_INT_STATE_SNA" 6 "EPB_INT_STATE_SELFPARK" 5 "EPB_INT_STATE_SERVICE" 4 "EPB_INT_STATE_START" 3 "EPB_INT_STATE_HANDBRAKE" 2 "EPB_INT_STATE_PARK" 1 "EPB_INT_STATE_DYNAMIC" 0 "EPB_INT_STATE_OPEN" ;
VAL_ 1812 EPB_selfParkFaultReason 23 "EPB_SELFPARKFAULT_PM_MISMATCH" 22 "EPB_SELFPARKFAULT_EPAS_NOT_LEARNED" 21 "EPB_SELFPARKFAULT_CALIBRATION" 20 "EPB_SELFPARKFAULT_DI_STATE_INVALID" 19 "EPB_SELFPARKFAULT_EPB_FAULT" 18 "EPB_SELFPARKFAULT_MISMATCH" 17 "EPB_SELFPARKFAULT_OOC" 16 "EPB_SELFPARKFAULT_PM_REQUEST" 15 "EPB_SELFPARKFAULT_PM_MIA" 14 "EPB_SELFPARKFAULT_PARK_MIA" 13 "EPB_SELFPARKFAULT_EXTERNAL" 12 "EPB_SELFPARKFAULT_SPEED" 11 "EPB_SELFPARKFAULT_EPBM_REQUEST" 10 "EPB_SELFPARKFAULT_EAC_NOT_ALLOWED" 9 "EPB_SELFPARKFAULT_CH_CAN_FAULT" 8 "EPB_SELFPARKFAULT_ESP_FAULT" 7 "EPB_SELFPARKFAULT_DAS_FAULT" 6 "EPB_SELFPARKFAULT_DI_APC_FAULT" 5 "EPB_SELFPARKFAULT_DI_FAULT" 4 "EPB_SELFPARKFAULT_EPBM_MIA" 3 "EPB_SELFPARKFAULT_ESP_MIA" 2 "EPB_SELFPARKFAULT_DAS_MIA" 1 "EPB_SELFPARKFAULT_DI_MIA" 0 "EPB_SELFPARKFAULT_NONE" ;
VAL_ 1812 EPB_nmState 6 "EPB_NM_STATE_NUM" 5 "EPB_NM_STATE_WAKEUP" 4 "EPB_NM_STATE_SLEEP" 3 "EPB_NM_STATE_QUIESCE" 2 "EPB_NM_STATE_GOING_TO_SLEEP" 1 "EPB_NM_STATE_AWAKE" 0 "EPB_NM_STATE_INIT" ;
VAL_ 1812 EPB_offsetApplied 2 "EPB_OFFSET_RELEASE" 1 "EPB_OFFSET_DYNAMIC" 0 "EPB_OFFSET_STATIC" ;
VAL_ 1892 EPB_debugOutput2 9 "EPB_DEBUG_9" 8 "EPB_DEBUG_8" 7 "EPB_DEBUG_7" 6 "EPB_DEBUG_6" 5 "EPB_DEBUG_5" 4 "EPB_DEBUG_4" 3 "EPB_DEBUG_3" 2 "EPB_DEBUG_2" 1 "EPB_DEBUG_1" 0 "EPB_DEBUG_0" ;
VAL_ 532 EPB_epasEACAllow 3 "EPB_SNA" 2 "EPB_RESERVED" 1 "EPB_ALLOW_EAC" 0 "EPB_INHIBIT_EAC" ;
VAL_ 1332 EPB_infoIndex 255 "INFO_END" 20 "INFO_UDS_PROTOCOL_BOOTCRC" 19 "INFO_VERSION_DEPRECATED" 18 "INFO_BOOTLOADER_GITHASH" 17 "INFO_APP_GITHASH" 16 "INFO_SUBCOMPONENT" 15 "INFO_BOOTLOADER_CRC" 14 "INFO_BOOTLOADER_SVN" 13 "INFO_APP_CRC" 11 "INFO_PCBAID_ASSYID_USAGEID" 10 "INFO_BUILD_HWID_COMPONENTID" 9 "INFO_DEPRECATED_9" 8 "INFO_DEPRECATED_8" 7 "INFO_DEPRECATED_7" 6 "INFO_DEPRECATED_6" 5 "INFO_DEPRECATED_5" 4 "INFO_DEPRECATED_4" 3 "INFO_DEPRECATED_3" 2 "INFO_DEPRECATED_2" 1 "INFO_DEPRECATED_1" 0 "INFO_DEPRECATED_0" ;
VAL_ 1332 EPB_infoHardwareRevision 252 "CONFIGURABLE_HWID_PLACEHOLDER" ;
VAL_ 1828 EPB_statsOutput 5 "EPB_MAX_DATA" 4 "EPB_DYNAMIC_DATA" 3 "EPB_STATIC3_DATA" 2 "EPB_STATIC2_DATA" 1 "EPB_STATIC1_DATA" 0 "EPB_STATIC0_DATA" ;
VAL_ 516 EPB_state 7 "EPB_STATE_SNA" 6 "EPB_STATE_SELFPARK" 5 "EPB_STATE_SERVICE" 4 "EPB_STATE_START" 3 "EPB_STATE_HANDBRAKE" 2 "EPB_STATE_PARK" 1 "EPB_STATE_DYNAMIC" 0 "EPB_STATE_OPEN" ;
VAL_ 516 EPB_stateRequest 7 "EPB_STATE_SNA" 6 "EPB_STATE_SELFPARK" 5 "EPB_STATE_SERVICE" 4 "EPB_STATE_START" 3 "EPB_STATE_HANDBRAKE" 2 "EPB_STATE_PARK" 1 "EPB_STATE_DYNAMIC" 0 "EPB_STATE_OPEN" ;
VAL_ 516 EPB_substateL 4 "EPB_SUBSTATE_CLR_FAULT" 3 "EPB_SUBSTATE_FAULT" 2 "EPB_SUBSTATE_RELEASING" 1 "EPB_SUBSTATE_APPLYING" 0 "EPB_SUBSTATE_STATIONARY" ;
VAL_ 516 EPB_substateR 4 "EPB_SUBSTATE_CLR_FAULT" 3 "EPB_SUBSTATE_FAULT" 2 "EPB_SUBSTATE_RELEASING" 1 "EPB_SUBSTATE_APPLYING" 0 "EPB_SUBSTATE_STATIONARY" ;
VAL_ 516 EPB_freeRollingModeStatus 2 "EPB_FREE_ROLLING_MODE_ENABLED" 1 "EPB_FREE_ROLLING_MODE_AVAILABLE" 0 "EPB_FREE_ROLLING_MODE_UNAVAILABLE" ;
VAL_ 516 EPB_brakeApplied 3 "SNA" 1 "APPLIED" 0 "RELEASED" ;
VAL_ 516 EPB_statePending 7 "EPB_STATE_SNA" 6 "EPB_STATE_SELFPARK" 5 "EPB_STATE_SERVICE" 4 "EPB_STATE_START" 3 "EPB_STATE_HANDBRAKE" 2 "EPB_STATE_PARK" 1 "EPB_STATE_DYNAMIC" 0 "EPB_STATE_OPEN" ;
VAL_ 516 EPB_calibrationStateLeft 4 "CAL_BUSY" 3 "CAL_FAULT" 2 "CAL_WARN" 1 "CAL_NORMAL" 0 "CAL_UNAVAILABLE" ;
VAL_ 516 EPB_ignoreCan 3 "IGNORE_CAN_SNA" 2 "IGNORE_CAN_UPDATE" 1 "LISTEN_TO_CAN" 0 "IGNORE_CAN_BOOT" ;
VAL_ 516 EPB_selfParkState 5 "SELFPARK_FAULT" 4 "SELFPARK_COMPLETE" 3 "SELFPARK_ACTIVE" 2 "SELFPARK_ARMED" 1 "SELFPARK_IDLE" 0 "SELFPARK_INIT" ;
VAL_ 516 EPB_telltale 7 "EPB_TELLTALE_SNA" 3 "LAMP_RED_FLASH_AMBER_ON" 2 "LAMP_AMBER_ON" 1 "LAMP_RED_ON" 0 "LAMP_OFF" ;
VAL_ 516 EPB_syncState 3 "EPB_SYNCSTATE_READY" 2 "EPB_SYNCSTATE_SYNCING" 1 "EPB_SYNCSTATE_LOSTSYNC" 0 "EPB_SYNCSTATE_INIT" ;
VAL_ 516 EPB_calibrationStateRight 4 "CAL_BUSY" 3 "CAL_FAULT" 2 "CAL_WARN" 1 "CAL_NORMAL" 0 "CAL_UNAVAILABLE" ;
VAL_ 277 ESP_understeerActive 1 "ACTIVE" 0 "INACTIVE" ;
VAL_ 277 ESP_oversteerActive 1 "ACTIVE" 0 "INACTIVE" ;
VAL_ 277 ESP_ebrStatus 7 "EBR_SNA" 3 "EBR_SAFETY_OVERRIDE" 2 "ESP_RELEASING_EBR_FOR_SKID" 1 "EBR_IS_NOT_AVAILABLE" 0 "EBR_IS_AVAILABLE" ;
VAL_ 277 ESP_regenTcOff 1 "ESP_REGEN_TC_NOT_AVAILABLE" 0 "ESP_REGEN_TC_AVAILABLE" ;
VAL_ 293 Long_Acceleration 127 "SNA" ;
VAL_ 293 Lat_Acceleration 127 "SNA" ;
VAL_ 309 ESP_hillStartAssistActive 3 "HSA_SNA" 2 "HSA_NOT_AVAILABLE" 1 "HSA_ACTIVE" 0 "HSA_INACTIVE" ;
VAL_ 309 ESP_absBrakeEvent 1 "ABS_EVENT_ACTIVE" 0 "ABS_EVENT_NOT_ACTIVE" ;
VAL_ 309 ESP_brakeLamp 1 "LAMP_ON" 0 "LAMP_OFF" ;
VAL_ 309 ESP_brakeDiscWipingActive 1 "BDW_ACTIVE" 0 "BDW_INACTIVE" ;
VAL_ 309 ESP_tcLampFlash 1 "LAMP_FLASH" 0 "LAMP_OFF" ;
VAL_ 309 ESP_espFaultLamp 1 "ESP_ESP_FAULT_LAMP_ON" 0 "ESP_ESP_FAULT_LAMP_OFF" ;
VAL_ 309 ESP_espLampFlash 1 "LAMP_FLASH" 0 "LAMP_OFF" ;
VAL_ 309 ESP_stabilityControlSts 5 "INIT" 4 "NOT_CONFIGURED" 3 "FAULTED" 2 "ENGAGED" 1 "ON" 0 "OFF" ;
VAL_ 309 ESP_absFaultLamp 1 "ABS_FAULT_LAMP_ON" 0 "ABS_FAULT_LAMP_OFF" ;
VAL_ 309 ESP_espOffLamp 1 "LAMP_ON" 0 "LAMP_OFF" ;
SIG_GROUP_ 1463 EPBM_alertDataW0 1 : EPBM_canAddress EPBM_canErrorType;
SIG_GROUP_ 1463 EPBM_alertDataW1 1 : EPBM_canErrorWord1;
SIG_GROUP_ 1463 EPBM_alertDataW2 1 : EPBM_canErrorWord2;
SIG_GROUP_ 1463 EPBM_alertIDWord 1 : EPBM_alertID EPBM_alertType;
SIG_GROUP_ 775 EPBM_faultMatrix0 1 : EPBM_f001_leftEncIntrpt EPBM_f002_leftIdleOc EPBM_f003_leftEncIrrational EPBM_f004_leftEncoderSna EPBM_f005_leftOc EPBM_f006_leftUc EPBM_f007_leftEndStop EPBM_f008_leftShortApply EPBM_f009_leftNShort EPBM_f010_leftPShort EPBM_f011_leftNOpen EPBM_f012_leftPOpen EPBM_f013_leftEnaStuckHigh EPBM_f014_leftEnaStuckLow EPBM_f015_leftDriveDuration EPBM_f016_leftPHalfBridge;
SIG_GROUP_ 775 EPBM_faultMatrix1 1 : EPBM_f017_leftNHalfBridge EPBM_f018_leftNvOv EPBM_f019_leftNvUv EPBM_f020_leftPvOv EPBM_f021_leftPvUv EPBM_f022_leftSubstateErr EPBM_f023_leftOverApply EPBM_f024_leftUnderApply EPBM_f025_leftOverRelease EPBM_f026_leftUnderRelease EPBM_f027_spuriousEncIntL EPBM_f028_noCurrentCalL EPBM_f029_canDisabled EPBM_f030_interProcSpi EPBM_f031_stateErr EPBM_f032_reqStateErr;
SIG_GROUP_ 775 EPBM_faultMatrix2 1 : EPBM_f033_canHardware EPBM_f034_canData EPBM_f035_canErr EPBM_f036_canOverrun EPBM_f037_firmware EPBM_f038_eeprom EPBM_f039_watchdogReset EPBM_f040_memoryError EPBM_f041_spiOpen EPBM_f042_spiRead EPBM_f043_absMIA EPBM_f044_diMIA EPBM_f045_gtwMIA EPBM_f046_sccmMIA EPBM_f047_epbMIA EPBM_f048_chgMIA;
SIG_GROUP_ 775 EPBM_faultMatrix3 1 : EPBM_f049_espMIA EPBM_f050_mcuMIA EPBM_f051_leftNVoltageLow EPBM_f052_leftPVoltageHigh EPBM_f053_unused EPBM_f054_unused EPBM_f055_stackOverflow EPBM_f056_12vOv EPBM_f057_12vUv EPBM_f058_5vLost EPBM_f059_battMismatch EPBM_f060_maxCycles1 EPBM_f061_maxCycles2 EPBM_f062_diGearInvld EPBM_f063_unused EPBM_f064_unused;
SIG_GROUP_ 823 EPBM_faultMatrix4 1 : EPBM_f065_rightEncIntrpt EPBM_f066_rightIdleOc EPBM_f067_rightEncIrrational EPBM_f068_rightEncoderSna EPBM_f069_rightOc EPBM_f070_rightUc EPBM_f071_rightEndStop EPBM_f072_rightShortApply EPBM_f073_rightNShort EPBM_f074_rightPShort EPBM_f075_rightNOpen EPBM_f076_rightPOpen EPBM_f077_rightEnaStuckHigh EPBM_f078_rightEnaStuckLow EPBM_f079_rightDriveDuration EPBM_f080_rightPHalfBridge;
SIG_GROUP_ 823 EPBM_faultMatrix5 1 : EPBM_f081_rightNHalfBridge EPBM_f082_rightNvOv EPBM_f083_rightNvUv EPBM_f084_rightPvOv EPBM_f085_rightPvUv EPBM_f086_rightSubstateErr EPBM_f087_rightOverApply EPBM_f088_rightUnderApply EPBM_f089_rightOverRelease EPBM_f090_rightUnderRelease EPBM_f091_spuriousEncIntR EPBM_f092_noCurrentCalR EPBM_f093_dasMIA EPBM_f094_unused EPBM_f095_invalidConfig EPBM_f096_selfParkAborted;
SIG_GROUP_ 823 EPBM_faultMatrix6 1 : EPBM_f097_parkMia EPBM_f098_pmMia EPBM_f099_unused EPBM_f100_calibrationWarning EPBM_f101_calibrationFault EPBM_f102_targetNotReachedL EPBM_f103_targetNotReachedR EPBM_f104_epbStillAsleep EPBM_f105_epbWentToSleep EPBM_f106_voltageWarning EPBM_f107_currentWarning EPBM_f108_unused EPBM_f109_unused EPBM_f110_calWarningLeft EPBM_f111_calWarningRight EPBM_f112_calFaultLeft;
SIG_GROUP_ 823 EPBM_faultMatrix7 1 : EPBM_f113_calFaultRight EPBM_f114_unparkNotAllowed EPBM_f115_rightNVoltageLow EPBM_f116_rightPVoltageHigh EPBM_f117_usedFallbackValues EPBM_f118_unused EPBM_f119_unused EPBM_f120_unused EPBM_f121_unused EPBM_f122_unused EPBM_f123_unused EPBM_f124_unused EPBM_f125_unused EPBM_f126_unused EPBM_f127_unused EPBM_f128_unused;
SIG_GROUP_ 791 EPBM_warnMatrix0 1 : EPBM_w001_leftEncIntrpt EPBM_w002_leftIdleOc EPBM_w003_leftEncIrrational EPBM_w004_leftEncoderSna EPBM_w005_leftOc EPBM_w006_leftUc EPBM_w007_leftEndStop EPBM_w008_leftShortApply EPBM_w009_leftNShort EPBM_w010_leftPShort EPBM_w011_leftNOpen EPBM_w012_leftPOpen EPBM_w013_leftEnaStuckHigh EPBM_w014_leftEnaStuckLow EPBM_w015_leftDriveDuration EPBM_w016_leftPHalfBridge;
SIG_GROUP_ 791 EPBM_warnMatrix1 1 : EPBM_w017_leftNHalfBridge EPBM_w018_leftNvOv EPBM_w019_leftNvUv EPBM_w020_leftPvOv EPBM_w021_leftPvUv EPBM_w022_leftSubstateErr EPBM_w023_leftOverApply EPBM_w024_leftUnderApply EPBM_w025_leftOverRelease EPBM_w026_leftUnderRelease EPBM_w027_spuriousEncIntL EPBM_w028_noCurrentCalL EPBM_w029_canDisabled EPBM_w030_interProcSpi EPBM_w031_stateErr EPBM_w032_reqStateErr;
SIG_GROUP_ 791 EPBM_warnMatrix2 1 : EPBM_w033_canHardware EPBM_w034_canData EPBM_w035_canErr EPBM_w036_canOverrun EPBM_w037_firmware EPBM_w038_eeprom EPBM_w039_watchdogReset EPBM_w040_memoryError EPBM_w041_spiOpen EPBM_w042_spiRead EPBM_w043_absMIA EPBM_w044_diMIA EPBM_w045_gtwMIA EPBM_w046_sccmMIA EPBM_w047_epbMIA EPBM_w048_chgMIA;
SIG_GROUP_ 791 EPBM_warnMatrix3 1 : EPBM_w049_espMIA EPBM_w050_mcuMIA EPBM_w051_leftNVoltageLow EPBM_w052_leftPVoltageHigh EPBM_w053_unused EPBM_w054_unused EPBM_w055_stackOverflow EPBM_w056_12vOv EPBM_w057_12vUv EPBM_w058_5vLost EPBM_w059_battMismatch EPBM_w060_maxCycles1 EPBM_w061_maxCycles2 EPBM_w062_diGearInvld EPBM_w063_unused EPBM_w064_unused;
SIG_GROUP_ 807 EPBM_warnMatrix4 1 : EPBM_w065_rightEncIntrpt EPBM_w066_rightIdleOc EPBM_w067_rightEncIrrational EPBM_w068_rightEncoderSna EPBM_w069_rightOc EPBM_w070_rightUc EPBM_w071_rightEndStop EPBM_w072_rightShortApply EPBM_w073_rightNShort EPBM_w074_rightPShort EPBM_w075_rightNOpen EPBM_w076_rightPOpen EPBM_w077_rightEnaStuckHigh EPBM_w078_rightEnaStuckLow EPBM_w079_rightDriveDuration EPBM_w080_rightPHalfBridge;
SIG_GROUP_ 807 EPBM_warnMatrix5 1 : EPBM_w081_rightNHalfBridge EPBM_w082_rightNvOv EPBM_w083_rightNvUv EPBM_w084_rightPvOv EPBM_w085_rightPvUv EPBM_w086_rightSubstateErr EPBM_w087_rightOverApply EPBM_w088_rightUnderApply EPBM_w089_rightOverRelease EPBM_w090_rightUnderRelease EPBM_w091_spuriousEncIntR EPBM_w092_noCurrentCalR EPBM_w093_dasMIA EPBM_w094_unused EPBM_w095_invalidConfig EPBM_w096_selfParkAborted;
SIG_GROUP_ 807 EPBM_warnMatrix6 1 : EPBM_w097_parkMia EPBM_w098_pmMia EPBM_w099_unused EPBM_w100_calibrationWarning EPBM_w101_calibrationFault EPBM_w102_targetNotReachedL EPBM_w103_targetNotReachedR EPBM_w104_epbStillAsleep EPBM_w105_epbWentToSleep EPBM_w106_voltageWarning EPBM_w107_currentWarning EPBM_w108_unused EPBM_w109_unused EPBM_w110_calWarningLeft EPBM_w111_calWarningRight EPBM_w112_calFaultLeft;
SIG_GROUP_ 807 EPBM_warnMatrix7 1 : EPBM_w113_calFaultRight EPBM_w114_unparkNotAllowed EPBM_w115_rightNVoltageLow EPBM_w116_rightPVoltageHigh EPBM_w117_usedFallbackValues EPBM_w118_unused EPBM_w119_unused EPBM_w120_unused EPBM_w121_unused EPBM_w122_unused EPBM_w123_unused EPBM_w124_unused EPBM_w125_unused EPBM_w126_unused EPBM_w127_unused EPBM_w128_unused;
SIG_GROUP_ 1476 EPB_alertDataW0 1 : EPB_canAddress EPB_canErrorType;
SIG_GROUP_ 1476 EPB_alertDataW1 1 : EPB_canErrorWord1;
SIG_GROUP_ 1476 EPB_alertDataW2 1 : EPB_canErrorWord2;
SIG_GROUP_ 1476 EPB_alertIDWord 1 : EPB_alertID EPB_alertType;
SIG_GROUP_ 772 EPB_faultMatrix0 1 : EPB_f001_leftEncIntrpt EPB_f002_leftIdleOc EPB_f003_leftEncIrrational EPB_f004_leftEncoderSna EPB_f005_leftOc EPB_f006_leftUc EPB_f007_leftEndStop EPB_f008_leftShortApply EPB_f009_leftNShort EPB_f010_leftPShort EPB_f011_leftNOpen EPB_f012_leftPOpen EPB_f013_leftEnaStuckHigh EPB_f014_leftEnaStuckLow EPB_f015_leftDriveDuration EPB_f016_leftPHalfBridge;
SIG_GROUP_ 772 EPB_faultMatrix1 1 : EPB_f017_leftNHalfBridge EPB_f018_leftNvOv EPB_f019_leftNvUv EPB_f020_leftPvOv EPB_f021_leftPvUv EPB_f022_leftSubstateErr EPB_f023_leftFirstShortApply EPB_f024_motorShortedReleaseL EPB_f025_motorShortedApplyL EPB_f026_noCurrentCalL EPB_f027_spuriousEncIntL EPB_f028_reqStateErr EPB_f029_stateErr EPB_f030_interProcSpi EPB_f031_chgMIA EPB_f032_canDisabled;
SIG_GROUP_ 772 EPB_faultMatrix2 1 : EPB_f033_canHardware EPB_f034_canData EPB_f035_canErr EPB_f036_canOverrun EPB_f037_firmware EPB_f038_eeprom EPB_f039_watchdogReset EPB_f040_memoryError EPB_f041_spiOpen EPB_f042_spiRead EPB_f043_absMIA EPB_f044_diMIA EPB_f045_gtwMIA EPB_f046_sccmMIA EPB_f047_epbmMIA EPB_f048_mcuMIA;
SIG_GROUP_ 772 EPB_faultMatrix3 1 : EPB_f049_espMIA EPB_f050_resetRequired EPB_f051_epbNotApplied EPB_f052_epbProblem EPB_f053_epbNotReleased EPB_f054_severeShortApply EPB_f055_stackOverflow EPB_f056_12vOv EPB_f057_12vUv EPB_f058_5vLost EPB_f059_battMismatch EPB_f060_maxCycles1 EPB_f061_maxCycles2 EPB_f062_diGearInvld EPB_f063_parkWhlSpeed EPB_f064_EPBMTimeout;
SIG_GROUP_ 820 EPB_faultMatrix4 1 : EPB_f065_rightEncIntrpt EPB_f066_rightIdleOc EPB_f067_rightEncIrrational EPB_f068_rightEncoderSna EPB_f069_rightOc EPB_f070_rightUc EPB_f071_rightEndStop EPB_f072_rightShortApply EPB_f073_rightNShort EPB_f074_rightPShort EPB_f075_rightNOpen EPB_f076_rightPOpen EPB_f077_rightEnaStuckHigh EPB_f078_rightEnaStuckLow EPB_f079_rightDriveDuration EPB_f080_rightPHalfBridge;
SIG_GROUP_ 820 EPB_faultMatrix5 1 : EPB_f081_rightNHalfBridge EPB_f082_rightNvOv EPB_f083_rightNvUv EPB_f084_rightPvOv EPB_f085_rightPvUv EPB_f086_rightSubstateErr EPB_f087_rightFirstShortApply EPB_f088_motorShortedReleaseR EPB_f089_motorShortedApplyR EPB_f090_noCurrentCalR EPB_f091_spuriousEncIntR EPB_f092_obsolete EPB_f093_dasMIA EPB_f094_inhibitEac EPB_f095_invalidConfig EPB_f096_epasMia;
SIG_GROUP_ 820 EPB_faultMatrix6 1 : EPB_f097_selfParkAborted EPB_f098_parkMia EPB_f099_pmMia EPB_f100_calibrationWarning EPB_f101_calibrationFault EPB_f102_eepromCorrupt EPB_f103_eepromUpdated EPB_f104_epbmStillAsleep EPB_f105_epbmWentToSleep EPB_f106_leftNVoltageLow EPB_f107_leftPVoltageHigh EPB_f108_rightNVoltageLow EPB_f109_rightPVoltageHigh EPB_f110_calWarningLeft EPB_f111_calWarningRight EPB_f112_calFaultLeft;
SIG_GROUP_ 820 EPB_faultMatrix7 1 : EPB_f113_calFaultRight EPB_f114_voltageWarning EPB_f115_currentWarning EPB_f116_unableToCalcGrade EPB_f117_usedFallbackValues EPB_f118_freeRollingModeActive EPB_f119_freeRollingModeAborted EPB_f120_releaseLogL EPB_f121_releaseLogR EPB_f122_freeRollMdEpbmMismatch EPB_f123_releaseDistanceL EPB_f124_releaseDistanceR EPB_f125_gradeTooSteep EPB_f126_ShortApplyUF EPB_f127_oocSpeedViolation EPB_f128_followedDiToPark;
SIG_GROUP_ 788 EPB_warnMatrix0 1 : EPB_w001_leftEncIntrpt EPB_w002_leftIdleOc EPB_w003_leftEncIrrational EPB_w004_leftEncoderSna EPB_w005_leftOc EPB_w006_leftUc EPB_w007_leftEndStop EPB_w008_leftShortApply EPB_w009_leftNShort EPB_w010_leftPShort EPB_w011_leftNOpen EPB_w012_leftPOpen EPB_w013_leftEnaStuckHigh EPB_w014_leftEnaStuckLow EPB_w015_leftDriveDuration EPB_w016_leftPHalfBridge;
SIG_GROUP_ 788 EPB_warnMatrix1 1 : EPB_w017_leftNHalfBridge EPB_w018_leftNvOv EPB_w019_leftNvUv EPB_w020_leftPvOv EPB_w021_leftPvUv EPB_w022_leftSubstateErr EPB_w023_leftFirstShortApply EPB_w024_motorShortedReleaseL EPB_w025_motorShortedApplyL EPB_w026_noCurrentCalL EPB_w027_spuriousEncIntL EPB_w028_reqStateErr EPB_w029_stateErr EPB_w030_interProcSpi EPB_w031_chgMIA EPB_w032_canDisabled;
SIG_GROUP_ 788 EPB_warnMatrix2 1 : EPB_w033_canHardware EPB_w034_canData EPB_w035_canErr EPB_w036_canOverrun EPB_w037_firmware EPB_w038_eeprom EPB_w039_watchdogReset EPB_w040_memoryError EPB_w041_spiOpen EPB_w042_spiRead EPB_w043_absMIA EPB_w044_diMIA EPB_w045_gtwMIA EPB_w046_sccmMIA EPB_w047_epbmMIA EPB_w048_mcuMIA;
SIG_GROUP_ 788 EPB_warnMatrix3 1 : EPB_w049_espMIA EPB_w050_resetRequired EPB_w051_epbNotApplied EPB_w052_epbProblem EPB_w053_epbNotReleased EPB_w054_severeShortApply EPB_w055_stackOverflow EPB_w056_12vOv EPB_w057_12vUv EPB_w058_5vLost EPB_w059_battMismatch EPB_w060_maxCycles1 EPB_w061_maxCycles2 EPB_w062_diGearInvld EPB_w063_parkWhlSpeed EPB_w064_EPBMTimeout;
SIG_GROUP_ 804 EPB_warnMatrix4 1 : EPB_w065_rightEncIntrpt EPB_w066_rightIdleOc EPB_w067_rightEncIrrational EPB_w068_rightEncoderSna EPB_w069_rightOc EPB_w070_rightUc EPB_w071_rightEndStop EPB_w072_rightShortApply EPB_w073_rightNShort EPB_w074_rightPShort EPB_w075_rightNOpen EPB_w076_rightPOpen EPB_w077_rightEnaStuckHigh EPB_w078_rightEnaStuckLow EPB_w079_rightDriveDuration EPB_w080_rightPHalfBridge;
SIG_GROUP_ 804 EPB_warnMatrix5 1 : EPB_w081_rightNHalfBridge EPB_w082_rightNvOv EPB_w083_rightNvUv EPB_w084_rightPvOv EPB_w085_rightPvUv EPB_w086_rightSubstateErr EPB_w087_rightFirstShortApply EPB_w088_motorShortedReleaseR EPB_w089_motorShortedApplyR EPB_w090_noCurrentCalR EPB_w091_spuriousEncIntR EPB_w092_obsolete EPB_w093_dasMIA EPB_w094_inhibitEac EPB_w095_invalidConfig EPB_w096_epasMia;
SIG_GROUP_ 804 EPB_warnMatrix6 1 : EPB_w097_selfParkAborted EPB_w098_parkMia EPB_w099_pmMia EPB_w100_calibrationWarning EPB_w101_calibrationFault EPB_w102_eepromCorrupt EPB_w103_eepromUpdated EPB_w104_epbmStillAsleep EPB_w105_epbmWentToSleep EPB_w106_leftNVoltageLow EPB_w107_leftPVoltageHigh EPB_w108_rightNVoltageLow EPB_w109_rightPVoltageHigh EPB_w110_calWarningLeft EPB_w111_calWarningRight EPB_w112_calFaultLeft;
SIG_GROUP_ 804 EPB_warnMatrix7 1 : EPB_w113_calFaultRight EPB_w114_voltageWarning EPB_w115_currentWarning EPB_w116_unableToCalcGrade EPB_w117_usedFallbackValues EPB_w118_freeRollingModeActive EPB_w119_freeRollingModeAborted EPB_w120_releaseLogL EPB_w121_releaseLogR EPB_w122_freeRollMdEpbmMismatch EPB_w123_releaseDistanceL EPB_w124_releaseDistanceR EPB_w125_gradeTooSteep EPB_w126_ShortApplyUF EPB_w127_oocSpeedViolation EPB_w128_followedDiToPark;
SIG_GROUP_ 836 EPB_userMatrix0 1 : EPB_u001_calibrationRequired EPB_u002_carMayRoll EPB_u003_dynamicBrakeApplied EPB_u004_pressFootBrake EPB_u005_epbProblem EPB_u006_epbNotReleased EPB_u007_dynNotApplied EPB_u008_turnOnCarToPark EPB_u009_towModeEnabled EPB_u010_serviceModeEnabled EPB_u011_parkSlope;
SIG_GROUP_ 852 EPB_warnMatrix10 1 : EPB_w161_unused EPB_w162_unused EPB_w163_unused EPB_w164_unused EPB_w165_unused EPB_w166_unused EPB_w167_unused EPB_w168_unused EPB_w169_unused EPB_w170_unused EPB_w171_unused EPB_w172_unused EPB_w173_unused EPB_w174_unused EPB_w175_unused EPB_w176_unused;
SIG_GROUP_ 852 EPB_warnMatrix11 1 : EPB_w177_unused EPB_w178_unused EPB_w179_unused EPB_w180_unused EPB_w181_unused EPB_w182_unused EPB_w183_unused EPB_w184_unused EPB_w185_unused EPB_w186_unused EPB_w187_unused EPB_w188_unused EPB_w189_unused EPB_w190_unused EPB_w191_unused EPB_w192_unused;
SIG_GROUP_ 852 EPB_warnMatrix8 1 : EPB_w129_unparkNotAllowed EPB_w130_unused EPB_w131_unused EPB_w132_unused EPB_w133_unused EPB_w134_unused EPB_w135_unused EPB_w136_unused EPB_w137_unused EPB_w138_unused EPB_w139_unused EPB_w140_unused EPB_w141_unused EPB_w142_unused EPB_w143_unused EPB_w144_unused;
SIG_GROUP_ 852 EPB_warnMatrix9 1 : EPB_w145_unused EPB_w146_unused EPB_w147_unused EPB_w148_unused EPB_w149_unused EPB_w150_unused EPB_w151_unused EPB_w152_unused EPB_w153_unused EPB_w154_unused EPB_w155_unused EPB_w156_unused EPB_w157_unused EPB_w158_unused EPB_w159_unused EPB_w160_unused;
SIG_GROUP_ 884 EPB_faultMatrix10 1 : EPB_f161_unused EPB_f162_unused EPB_f163_unused EPB_f164_unused EPB_f165_unused EPB_f166_unused EPB_f167_unused EPB_f168_unused EPB_f169_unused EPB_f170_unused EPB_f171_unused EPB_f172_unused EPB_f173_unused EPB_f174_unused EPB_f175_unused EPB_f176_unused;
SIG_GROUP_ 884 EPB_faultMatrix11 1 : EPB_f177_unused EPB_f178_unused EPB_f179_unused EPB_f180_unused EPB_f181_unused EPB_f182_unused EPB_f183_unused EPB_f184_unused EPB_f185_unused EPB_f186_unused EPB_f187_unused EPB_f188_unused EPB_f189_unused EPB_f190_unused EPB_f191_unused EPB_f192_unused;
SIG_GROUP_ 884 EPB_faultMatrix8 1 : EPB_f129_unparkNotAllowed EPB_f130_unused EPB_f131_unused EPB_f132_unused EPB_f133_unused EPB_f134_unused EPB_f135_unused EPB_f136_unused EPB_f137_unused EPB_f138_unused EPB_f139_unused EPB_f140_unused EPB_f141_unused EPB_f142_unused EPB_f143_unused EPB_f144_unused;
SIG_GROUP_ 884 EPB_faultMatrix9 1 : EPB_f145_unused EPB_f146_unused EPB_f147_unused EPB_f148_unused EPB_f149_unused EPB_f150_unused EPB_f151_unused EPB_f152_unused EPB_f153_unused EPB_f154_unused EPB_f155_unused EPB_f156_unused EPB_f157_unused EPB_f158_unused EPB_f159_unused EPB_f160_unused;
SIG_GROUP_ 309 ESP_messages 1 : ESP_absFaultLamp ESP_espOffLamp ESP_hydraulicBoostEnabled ESP_messageDynoModeActive ESP_messageEBDFailure ESP_messagePumpFailure ESP_messagePumpService ESP_tcDisabledByFault;
